VERSION ""

NS_ :

BS_:

BU_:

BO_ 2147548630 BJM1: 8 Vector__XXX
 SG_ Joystick1XAxisDetentPosStatus : 38|2@1+ (1,0) [0|3] "" Vector__XXX
 SG_ Joystick1YAxisDetentPosStatus : 36|2@1+ (1,0) [0|3] "" Vector__XXX
 SG_ Joystick1YAxisPos : 22|10@1+ (0.1,0) [0|102] "%" Vector__XXX
 SG_ Jystck1YAxsLvrFrwrdPstvPsStatus : 20|2@1+ (1,0) [0|3] "" Vector__XXX
 SG_ Jystck1YAxsLvrBckNgtvePosStatus : 18|2@1+ (1,0) [0|3] "" Vector__XXX
 SG_ Joystick1YAxisNeutralPosStatus : 16|2@1+ (1,0) [0|3] "" Vector__XXX
 SG_ Joystick1XAxisPos : 6|10@1+ (0.1,0) [0|102] "%" Vector__XXX
 SG_ Joystick1Button9PressedStatus : 62|2@1+ (1,0) [0|3] "" Vector__XXX
 SG_ Joystick1Button10PressedStatus : 60|2@1+ (1,0) [0|3] "" Vector__XXX
 SG_ Joystick1Button11PressedStatus : 58|2@1+ (1,0) [0|3] "" Vector__XXX
 SG_ Joystick1Button12PressedStatus : 56|2@1+ (1,0) [0|3] "" Vector__XXX
 SG_ Joystick1Button5PressedStatus : 54|2@1+ (1,0) [0|3] "" Vector__XXX
 SG_ Joystick1Button6PressedStatus : 52|2@1+ (1,0) [0|3] "" Vector__XXX
 SG_ Joystick1Button7PressedStatus : 50|2@1+ (1,0) [0|3] "" Vector__XXX
 SG_ Joystick1Button8PressedStatus : 48|2@1+ (1,0) [0|3] "" Vector__XXX
 SG_ Joystick1Button1PressedStatus : 46|2@1+ (1,0) [0|3] "" Vector__XXX
 SG_ Joystick1Button2PressedStatus : 44|2@1+ (1,0) [0|3] "" Vector__XXX
 SG_ Joystick1Button3PressedStatus : 42|2@1+ (1,0) [0|3] "" Vector__XXX
 SG_ Joystick1Button4PressedStatus : 40|2@1+ (1,0) [0|3] "" Vector__XXX
 SG_ Jystck1XAxsLvrRghtPstvPosStatus : 4|2@1+ (1,0) [0|3] "" Vector__XXX
 SG_ Jystck1XAxsLvrLftNgtvePosStatus : 2|2@1+ (1,0) [0|3] "" Vector__XXX
 SG_ Joystick1XAxisNeutralPosStatus : 0|2@1+ (1,0) [0|3] "" Vector__XXX

BO_ 2147548922 B: 8 Vector__XXX
 SG_ ParkingBrakeActuator : 24|2@1+ (1,0) [0|3] "" Vector__XXX
 SG_ BrakeSecondPress : 16|8@1+ (4,0) [0|1000] "kPa" Vector__XXX
 SG_ BrakePrimaryPress : 8|8@1+ (4,0) [0|1000] "kPa" Vector__XXX
 SG_ BrakeAppPress : 0|8@1+ (4,0) [0|1000] "kPa" Vector__XXX

BO_ 2147548926 AWPP: 8 Vector__XXX
 SG_ AuxPumpPress : 0|8@1+ (16,0) [0|4000] "kPa" Vector__XXX

BO_ 2147548889 AUXIO: 8 Vector__XXX
 SG_ AuxI_OChannel2 : 48|16@1+ (1,0) [0|64255] "counts" Vector__XXX
 SG_ AuxI_OChannel1 : 32|16@1+ (1,0) [0|64255] "counts" Vector__XXX
 SG_ AuxI_O13 : 30|2@1+ (1,0) [0|3] "" Vector__XXX
 SG_ AuxI_O14 : 28|2@1+ (1,0) [0|3] "" Vector__XXX
 SG_ AuxI_O15 : 26|2@1+ (1,0) [0|3] "" Vector__XXX
 SG_ AuxI_O16 : 24|2@1+ (1,0) [0|3] "" Vector__XXX
 SG_ AuxI_O09 : 22|2@1+ (1,0) [0|3] "" Vector__XXX
 SG_ AuxI_O10 : 20|2@1+ (1,0) [0|3] "" Vector__XXX
 SG_ AuxI_O11 : 18|2@1+ (1,0) [0|3] "" Vector__XXX
 SG_ AuxI_O12 : 16|2@1+ (1,0) [0|3] "" Vector__XXX
 SG_ AuxI_O05 : 14|2@1+ (1,0) [0|3] "" Vector__XXX
 SG_ AuxI_O06 : 12|2@1+ (1,0) [0|3] "" Vector__XXX
 SG_ AuxI_O07 : 10|2@1+ (1,0) [0|3] "" Vector__XXX
 SG_ AuxI_O08 : 8|2@1+ (1,0) [0|3] "" Vector__XXX
 SG_ AuxI_O01 : 6|2@1+ (1,0) [0|3] "" Vector__XXX
 SG_ AuxI_O02 : 4|2@1+ (1,0) [0|3] "" Vector__XXX
 SG_ AuxI_O03 : 2|2@1+ (1,0) [0|3] "" Vector__XXX
 SG_ AuxI_O04 : 0|2@1+ (1,0) [0|3] "" Vector__XXX

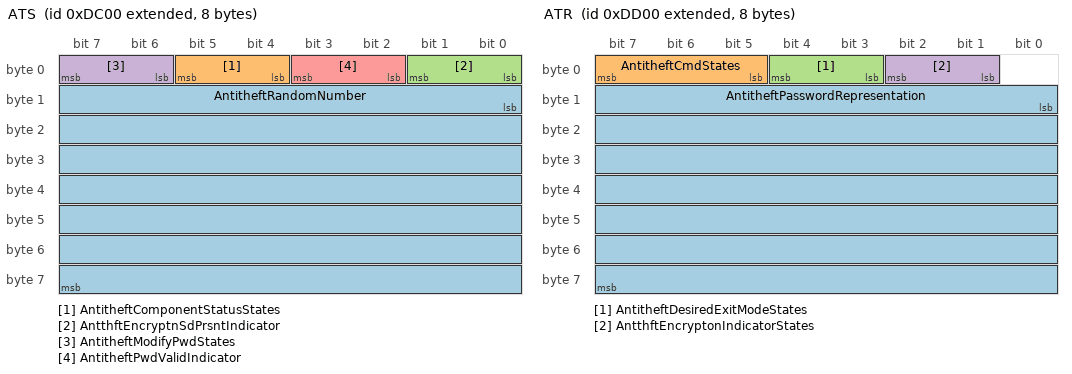
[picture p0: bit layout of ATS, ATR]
BO_ 2147539968 ATS: 8 Vector__XXX
 SG_ AntitheftRandomNumber : 8|56@1+ (1,0) [0|255] "per" Vector__XXX
 SG_ AntitheftComponentStatusStates : 4|2@1+ (1,0) [0|3] "" Vector__XXX
 SG_ AntthftEncryptnSdPrsntIndicator : 0|2@1+ (1,0) [0|3] "" Vector__XXX
 SG_ AntitheftModifyPwdStates : 6|2@1+ (1,0) [0|3] "" Vector__XXX
 SG_ AntitheftPwdValidIndicator : 2|2@1+ (1,0) [0|3] "" Vector__XXX

BO_ 2147540224 ATR: 8 Vector__XXX
 SG_ AntitheftPasswordRepresentation : 8|56@1+ (1,0) [0|255] "per" Vector__XXX
 SG_ AntitheftCmdStates : 5|3@1+ (1,0) [0|7] "" Vector__XXX
 SG_ AntitheftDesiredExitModeStates : 3|2@1+ (1,0) [0|3] "" Vector__XXX
 SG_ AntthftEncryptonIndicatorStates : 1|2@1+ (1,0) [0|3] "" Vector__XXX

BO_ 2147548593 ATI2b: 8 Vector__XXX

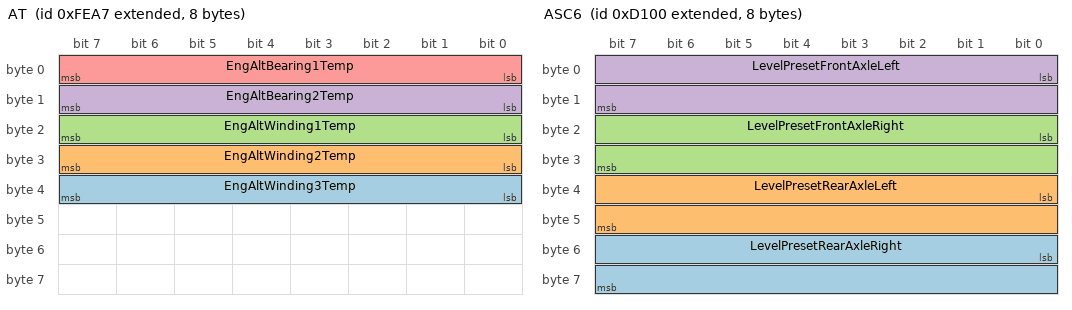
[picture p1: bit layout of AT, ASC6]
BO_ 2147548839 AT: 8 Vector__XXX
 SG_ EngAltWinding3Temp : 32|8@1+ (1,-40) [-40|210] "deg" Vector__XXX
 SG_ EngAltWinding2Temp : 24|8@1+ (1,-40) [-40|210] "deg" Vector__XXX
 SG_ EngAltWinding1Temp : 16|8@1+ (1,-40) [-40|210] "deg" Vector__XXX
 SG_ EngAltBearing2Temp : 8|8@1+ (1,-40) [-40|210] "deg" Vector__XXX
 SG_ EngAltBearing1Temp : 0|8@1+ (1,-40) [-40|210] "deg" Vector__XXX

BO_ 2147537152 ASC6: 8 Vector__XXX
 SG_ LevelPresetRearAxleRight : 48|16@1+ (0.1,-2800) [-2800|3225.5] "mm" Vector__XXX
 SG_ LevelPresetRearAxleLeft : 32|16@1+ (0.1,-2800) [-2800|3225.5] "mm" Vector__XXX
 SG_ LevelPresetFrontAxleRight : 16|16@1+ (0.1,-2800) [-2800|3225.5] "mm" Vector__XXX
 SG_ LevelPresetFrontAxleLeft : 0|16@1+ (0.1,-2800) [-2800|3225.5] "mm" Vector__XXX

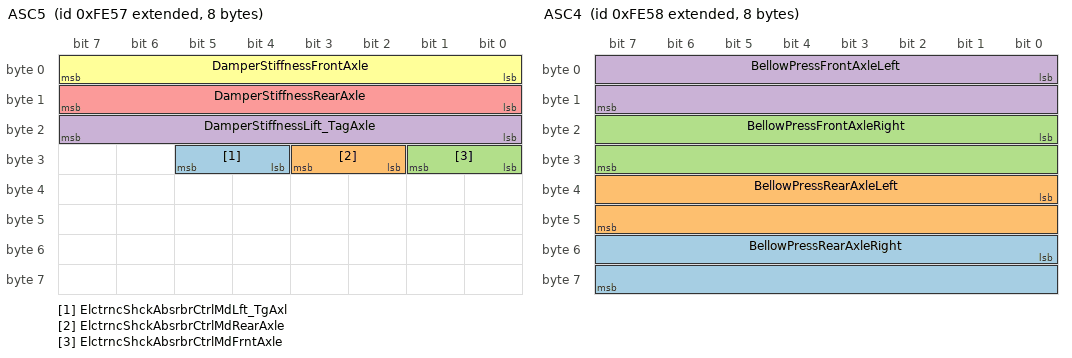
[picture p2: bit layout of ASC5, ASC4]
BO_ 2147548759 ASC5: 8 Vector__XXX
 SG_ ElctrncShckAbsrbrCtrlMdLft_TgAxl : 28|2@1+ (1,0) [0|3] "" Vector__XXX
 SG_ ElctrncShckAbsrbrCtrlMdRearAxle : 26|2@1+ (1,0) [0|3] "" Vector__XXX
 SG_ ElctrncShckAbsrbrCtrlMdFrntAxle : 24|2@1+ (1,0) [0|3] "" Vector__XXX
 SG_ DamperStiffnessLift_TagAxle : 16|8@1+ (0.4,0) [0|100] "%" Vector__XXX
 SG_ DamperStiffnessRearAxle : 8|8@1+ (0.4,0) [0|100] "%" Vector__XXX
 SG_ DamperStiffnessFrontAxle : 0|8@1+ (0.4,0) [0|100] "%" Vector__XXX

BO_ 2147548760 ASC4: 8 Vector__XXX
 SG_ BellowPressRearAxleRight : 48|16@1+ (0.1,0) [0|6425.5] "kPa" Vector__XXX
 SG_ BellowPressRearAxleLeft : 32|16@1+ (0.1,0) [0|6425.5] "kPa" Vector__XXX
 SG_ BellowPressFrontAxleRight : 16|16@1+ (0.1,0) [0|6425.5] "kPa" Vector__XXX
 SG_ BellowPressFrontAxleLeft : 0|16@1+ (0.1,0) [0|6425.5] "kPa" Vector__XXX

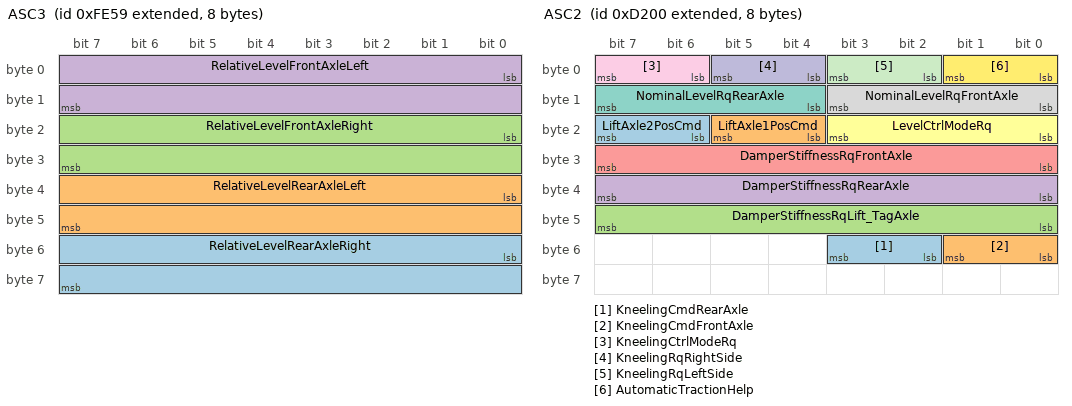
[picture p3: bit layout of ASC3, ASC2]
BO_ 2147548761 ASC3: 8 Vector__XXX
 SG_ RelativeLevelRearAxleRight : 48|16@1+ (0.1,-2800) [-2800|3225.5] "mm" Vector__XXX
 SG_ RelativeLevelRearAxleLeft : 32|16@1+ (0.1,-2800) [-2800|3225.5] "mm" Vector__XXX
 SG_ RelativeLevelFrontAxleRight : 16|16@1+ (0.1,-2800) [-2800|3225.5] "mm" Vector__XXX
 SG_ RelativeLevelFrontAxleLeft : 0|16@1+ (0.1,-2800) [-2800|3225.5] "mm" Vector__XXX

BO_ 2147537408 ASC2: 8 Vector__XXX
 SG_ KneelingCmdRearAxle : 50|2@1+ (1,0) [0|3] "" Vector__XXX
 SG_ KneelingCmdFrontAxle : 48|2@1+ (1,0) [0|3] "" Vector__XXX
 SG_ DamperStiffnessRqLift_TagAxle : 40|8@1+ (0.4,0) [0|100] "%" Vector__XXX
 SG_ DamperStiffnessRqRearAxle : 32|8@1+ (0.4,0) [0|100] "%" Vector__XXX
 SG_ DamperStiffnessRqFrontAxle : 24|8@1+ (0.4,0) [0|100] "%" Vector__XXX
 SG_ LevelCtrlModeRq : 16|4@1+ (1,0) [0|15] "" Vector__XXX
 SG_ NominalLevelRqRearAxle : 12|4@1+ (1,0) [0|15] "" Vector__XXX
 SG_ NominalLevelRqFrontAxle : 8|4@1+ (1,0) [0|15] "" Vector__XXX
 SG_ KneelingCtrlModeRq : 6|2@1+ (1,0) [0|3] "" Vector__XXX
 SG_ KneelingRqRightSide : 4|2@1+ (1,0) [0|3] "" Vector__XXX
 SG_ KneelingRqLeftSide : 2|2@1+ (1,0) [0|3] "" Vector__XXX
 SG_ AutomaticTractionHelp : 0|2@1+ (1,0) [0|3] "" Vector__XXX
 SG_ LiftAxle2PosCmd : 22|2@1+ (1,0) [0|3] "" Vector__XXX
 SG_ LiftAxle1PosCmd : 20|2@1+ (1,0) [0|3] "" Vector__XXX

BO_ 2147548762 ASC1: 8 Vector__XXX
 SG_ SspensionCtrlRefusalInformation : 56|4@1+ (1,0) [0|15] "" Vector__XXX
 SG_ SuspensionRemoteCtrl2 : 50|2@1+ (1,0) [0|3] "" Vector__XXX
 SG_ SuspensionRemoteCtrl1 : 48|2@1+ (1,0) [0|3] "" Vector__XXX
 SG_ RearAxleInBumperRange : 42|2@1+ (1,0) [0|3] "" Vector__XXX
 SG_ FrontAxleInBumperRange : 40|2@1+ (1,0) [0|3] "" Vector__XXX
 SG_ DoorRelease : 36|2@1+ (1,0) [0|3] "" Vector__XXX
 SG_ VehicleMotionInhibit : 34|2@1+ (1,0) [0|3] "" Vector__XXX
 SG_ SecurityDevice : 32|2@1+ (1,0) [0|3] "" Vector__XXX
 SG_ LevelCtrlMode : 28|4@1+ (1,0) [0|15] "" Vector__XXX
 SG_ KneelingInformation : 24|4@1+ (1,0) [0|15] "" Vector__XXX
 SG_ LiftingCtrlModeRearAxle : 22|2@1+ (1,0) [0|3] "" Vector__XXX
 SG_ LiftingCtrlModeFrontAxle : 20|2@1+ (1,0) [0|3] "" Vector__XXX
 SG_ LoweringCtrlModeRearAxle : 18|2@1+ (1,0) [0|3] "" Vector__XXX
 SG_ LoweringCtrlModeFrontAxle : 16|2@1+ (1,0) [0|3] "" Vector__XXX
 SG_ AboveNominalLevelRearAxle : 14|2@1+ (1,0) [0|3] "" Vector__XXX
 SG_ AboveNominalLevelFrontAxle : 12|2@1+ (1,0) [0|3] "" Vector__XXX
 SG_ BelowNominalLevelRearAxle : 10|2@1+ (1,0) [0|3] "" Vector__XXX
 SG_ BelowNominalLevelFrontAxle : 8|2@1+ (1,0) [0|3] "" Vector__XXX
 SG_ NominalLevelRearAxle : 4|4@1+ (1,0) [0|15] "" Vector__XXX
 SG_ NominalLevelFrontAxle : 0|4@1+ (1,0) [0|15] "" Vector__XXX
 SG_ LiftAxle2Pos : 46|2@1+ (1,0) [0|3] "" Vector__XXX
 SG_ LiftAxle1Pos : 38|2@1+ (1,0) [0|3] "" Vector__XXX

BO_ 2147548885 AS: 8 Vector__XXX
 SG_ AltSpeed : 0|16@1+ (0.5,0) [0|32127.5] "rpm" Vector__XXX

BO_ 2147548791 AP: 8 Vector__XXX
 SG_ AuxAbsPressReading : 32|16@1+ (0.5,0) [0|32127.5] "kPa" Vector__XXX
 SG_ AuxGagePressReading1 : 16|16@1+ (0.5,0) [0|32127.5] "kPa" Vector__XXX
 SG_ AuxVacuumPressReading : 0|16@1+ (0.5,0) [0|32127.5] "kPa" Vector__XXX

BO_ 2147548640 AMB2: 8 Vector__XXX
 SG_ SolarSensorMax : 8|8@1+ (0.4,0) [0|100] "mW/cm^2" Vector__XXX
 SG_ SolarIntensityPercent : 0|8@1+ (0.4,0) [0|100] "%" Vector__XXX

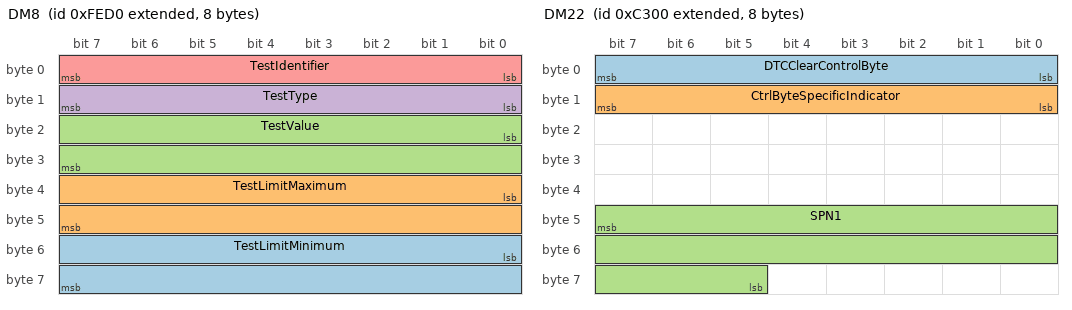
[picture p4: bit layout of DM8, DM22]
BO_ 2147548880 DM8: 8 Vector__XXX
 SG_ TestLimitMinimum : 48|16@1+ (1,0) [0|64255] "" Vector__XXX
 SG_ TestLimitMaximum : 32|16@1+ (1,0) [0|64255] "" Vector__XXX
 SG_ TestValue : 16|16@1+ (1,0) [0|64255] "" Vector__XXX
 SG_ TestType : 8|8@1+ (1,0) [1|64] "" Vector__XXX
 SG_ TestIdentifier : 0|8@1+ (1,0) [1|64] "" Vector__XXX

BO_ 2680225732 PropBC4: 8 Vector__XXX

BO_ 2680225731 PropBC3: 8 Vector__XXX

BO_ 2680225730 PropBC2: 8 Vector__XXX

BO_ 2680225729 PropBC1: 8 Vector__XXX

BO_ 2680225728 PropBC0: 8 Vector__XXX

BO_ 2680225727 PropBBF: 8 Vector__XXX

BO_ 2680225726 PropBBE: 8 Vector__XXX

BO_ 2680225725 PropBBD: 8 Vector__XXX

BO_ 2680225724 PropBBC: 8 Vector__XXX

BO_ 2680225723 PropBBB: 8 Vector__XXX

BO_ 2680225722 PropBBA: 8 Vector__XXX

BO_ 2680225721 PropBB9: 8 Vector__XXX

BO_ 2680225720 PropBB8: 8 Vector__XXX

BO_ 2680225719 PropBB7: 8 Vector__XXX

BO_ 2680225718 PropBB6: 8 Vector__XXX

BO_ 2680225717 PropBB5: 8 Vector__XXX

BO_ 2680225716 PropBB4: 8 Vector__XXX

BO_ 2680225715 PropBB3: 8 Vector__XXX

BO_ 2680225714 PropBB2: 8 Vector__XXX

BO_ 2680225713 PropBB1: 8 Vector__XXX

BO_ 2680225712 PropBB0: 8 Vector__XXX

BO_ 2680225711 PropBAF: 8 Vector__XXX

BO_ 2680225710 PropBAE: 8 Vector__XXX

BO_ 2680225709 PropBAD: 8 Vector__XXX

BO_ 2680225708 PropBAC: 8 Vector__XXX

BO_ 2680225707 PropBAB: 8 Vector__XXX

BO_ 2680225706 PropBAA: 8 Vector__XXX

BO_ 2680225705 PropBA9: 8 Vector__XXX

BO_ 2680225704 PropBA8: 8 Vector__XXX

BO_ 2680225703 PropBA7: 8 Vector__XXX

BO_ 2680225702 PropBA6: 8 Vector__XXX

BO_ 2680225701 PropBA5: 8 Vector__XXX

BO_ 2680225700 PropBA4: 8 Vector__XXX

BO_ 2680225699 PropBA3: 8 Vector__XXX

BO_ 2680225698 PropBA2: 8 Vector__XXX

BO_ 2680225697 PropBA1: 8 Vector__XXX

BO_ 2680225696 PropBA0: 8 Vector__XXX

BO_ 2680225695 PropB9F: 8 Vector__XXX

BO_ 2680225694 PropB9E: 8 Vector__XXX

BO_ 2680225693 PropB9D: 8 Vector__XXX

BO_ 2680225692 PropB9C: 8 Vector__XXX

BO_ 2680225691 PropB9B: 8 Vector__XXX

BO_ 2680225690 PropB9A: 8 Vector__XXX

BO_ 2680225689 PropB99: 8 Vector__XXX

BO_ 2680225688 PropB98: 8 Vector__XXX

BO_ 2680225687 PropB97: 8 Vector__XXX

BO_ 2680225686 PropB96: 8 Vector__XXX

BO_ 2680225685 PropB95: 8 Vector__XXX

BO_ 2680225684 PropB94: 8 Vector__XXX

BO_ 2680225683 PropB93: 8 Vector__XXX

BO_ 2680225682 PropB92: 8 Vector__XXX

BO_ 2680225681 PropB91: 8 Vector__XXX

BO_ 2680225680 PropB90: 8 Vector__XXX

BO_ 2680225679 PropB8F: 8 Vector__XXX

BO_ 2680225678 PropB8E: 8 Vector__XXX

BO_ 2680225677 PropB8D: 8 Vector__XXX

BO_ 2680225676 PropB8C: 8 Vector__XXX

BO_ 2680225675 PropB8B: 8 Vector__XXX

BO_ 2680225674 PropB8A: 8 Vector__XXX

BO_ 2680225673 PropB89: 8 Vector__XXX

BO_ 2680225672 PropB88: 8 Vector__XXX

BO_ 2680225671 PropB87: 8 Vector__XXX

BO_ 2680225670 PropB86: 8 Vector__XXX

BO_ 2680225669 PropB85: 8 Vector__XXX

BO_ 2680225668 PropB84: 8 Vector__XXX

BO_ 2680225667 PropB83: 8 Vector__XXX

BO_ 2680225666 PropB82: 8 Vector__XXX

BO_ 2680225665 PropB81: 8 Vector__XXX

BO_ 2680225664 PropB80: 8 Vector__XXX

BO_ 2680225663 PropB7F: 8 Vector__XXX

BO_ 2147541760 DM7: 8 Vector__XXX
 SG_ TestIdentifier : 0|8@1+ (1,0) [1|64] "" Vector__XXX

BO_ 2147548879 DM6: 22 Vector__XXX
 SG_ SPN5 : 151|19@0+ (1,0) [0|524287] "" Vector__XXX
 SG_ SPN4 : 119|19@0+ (1,0) [0|524287] "" Vector__XXX
 SG_ SPN3 : 87|19@0+ (1,0) [0|524287] "" Vector__XXX
 SG_ SPN2 : 55|19@0+ (1,0) [0|524287] "" Vector__XXX
 SG_ FailureModeIdentifier5 : 160|5@1+ (1,0) [0|0] "" Vector__XXX
 SG_ FailureModeIdentifier4 : 128|5@1+ (1,0) [0|0] "" Vector__XXX
 SG_ FailureModeIdentifier3 : 96|5@1+ (1,0) [0|0] "" Vector__XXX
 SG_ FailureModeIdentifier2 : 64|5@1+ (1,0) [0|0] "" Vector__XXX
 SG_ SPNConversionMethod5 : 175|1@1+ (1,0) [0|1] "" Vector__XXX
 SG_ SPNConversionMethod4 : 143|1@1+ (1,0) [0|1] "" Vector__XXX
 SG_ SPNConversionMethod3 : 111|1@1+ (1,0) [0|1] "" Vector__XXX
 SG_ SPNConversionMethod2 : 79|1@1+ (1,0) [0|1] "" Vector__XXX
 SG_ OccurenceCount5 : 168|7@1+ (1,0) [0|126] "" Vector__XXX
 SG_ OccurenceCount4 : 136|7@1+ (1,0) [0|126] "" Vector__XXX
 SG_ OccurenceCount3 : 104|7@1+ (1,0) [0|126] "" Vector__XXX
 SG_ OccurenceCount2 : 72|7@1+ (1,0) [0|126] "" Vector__XXX
 SG_ OccurenceCount1 : 40|7@1+ (1,0) [0|126] "" Vector__XXX
 SG_ SPNConversionMethod1 : 47|1@1+ (1,0) [0|1] "" Vector__XXX
 SG_ FailureModeIdentifier1 : 32|5@1+ (1,0) [0|0] "" Vector__XXX
 SG_ SPN1 : 23|19@0+ (1,0) [0|524287] "" Vector__XXX
 SG_ MalfunctionIndicatorLampStatus : 6|2@1+ (1,0) [0|3] "" Vector__XXX
 SG_ RedStopLampState : 4|2@1+ (1,0) [0|3] "" Vector__XXX
 SG_ AmberWarningLampStatus : 2|2@1+ (1,0) [0|3] "" Vector__XXX
 SG_ ProtectLampStatus : 0|2@1+ (1,0) [0|3] "" Vector__XXX

BO_ 2147548878 DM5: 8 Vector__XXX
 SG_ MisfireMonitoringSupport : 24|1@1+ (1,0) [0|0] "" Vector__XXX
 SG_ OBDCompliance : 16|8@1+ (1,0) [0|240] "" Vector__XXX
 SG_ PreviouslyActiveTroubleCodes : 8|8@1+ (1,0) [0|240] "" Vector__XXX
 SG_ ActiveTroubleCodes : 0|8@1+ (1,0) [0|240] "" Vector__XXX
 SG_ SecondAirSystemMonStatus : 51|1@1+ (1,0) [0|1] "" Vector__XXX
 SG_ EvaporativeSystemMonStatus : 50|1@1+ (1,0) [0|1] "" Vector__XXX
 SG_ ACSystemRefrigerantMonStatus : 52|1@1+ (1,0) [0|1] "" Vector__XXX
 SG_ OxygenSensorHeaterMonStatus : 54|1@1+ (1,0) [0|1] "" Vector__XXX
 SG_ OxygenSensorMonStatus : 53|1@1+ (1,0) [0|1] "" Vector__XXX
 SG_ EGRSystemMonitoringStatus : 55|1@1+ (1,0) [0|1] "" Vector__XXX
 SG_ CatalystMonStatus : 48|1@1+ (1,0) [0|1] "" Vector__XXX
 SG_ ColdStartAidSystemMonStatus : 56|1@1+ (1,0) [0|1] "" Vector__XXX
 SG_ HeatedCatalystMonStatus : 49|1@1+ (1,0) [0|0] "" Vector__XXX
 SG_ CatalystMonSupp : 32|1@1+ (1,0) [0|1] "" Vector__XXX
 SG_ ColdStartAidSystemMonSupp : 40|1@1+ (1,0) [0|1] "" Vector__XXX
 SG_ HeatedCatalystMonSupp : 33|1@1+ (1,0) [0|0] "" Vector__XXX
 SG_ EvaporativeSystemMonSupp : 34|1@1+ (1,0) [0|1] "" Vector__XXX
 SG_ SecondAirSystemMonSupp : 35|1@1+ (1,0) [0|1] "" Vector__XXX
 SG_ ACSystemRefrigerantMonSupp : 36|1@1+ (1,0) [0|1] "" Vector__XXX
 SG_ OxygenSensorMonSupp : 37|1@1+ (1,0) [0|1] "" Vector__XXX
 SG_ OxygenSensorHeaterMonSupp : 38|1@1+ (1,0) [0|1] "" Vector__XXX
 SG_ EGRSystemMonitoringSupp : 39|1@1+ (1,0) [0|1] "" Vector__XXX
 SG_ MisfireMonitoringStatus : 28|1@1+ (1,0) [0|0] "" Vector__XXX
 SG_ ComprehensiveCompMonStatus : 30|1@1+ (1,0) [0|1] "" Vector__XXX
 SG_ FuelSystemMonitoringStatus : 29|1@1+ (1,0) [0|1] "" Vector__XXX
 SG_ ComprehensiveComponentMonSupp : 26|1@1+ (1,0) [0|0] "" Vector__XXX
 SG_ FuelSystemMonitoringSupport : 25|1@1+ (1,0) [0|1] "" Vector__XXX

BO_ 2147548877 DM4: 13 Vector__XXX
 SG_ OccurenceCount1 : 32|7@1+ (1,0) [0|126] "" Vector__XXX
 SG_ SPNConversionMethod1 : 39|1@1+ (1,0) [0|1] "" Vector__XXX
 SG_ VehicleSpeed : 88|16@1+ (0.00390625,0) [0|250.996] "km/h" Vector__XXX
 SG_ EngineLoad : 72|8@1+ (0.4,0) [0|100] "%" Vector__XXX
 SG_ Boost : 48|8@1+ (2,0) [0|500] "kPa" Vector__XXX
 SG_ FailureModeIdentifier1 : 24|5@1+ (1,0) [0|0] "" Vector__XXX
 SG_ SPN1 : 15|19@0+ (1,0) [0|524287] "" Vector__XXX
 SG_ FreezeFrameLength : 0|8@1+ (1,0) [0|255] "byte" Vector__XXX
 SG_ EngineTorqueMode : 40|8@1+ (1,0) [0|255] "" Vector__XXX
 SG_ EngineSpeed : 56|16@1+ (0.125,0) [0|8031.88] "rpm" Vector__XXX
 SG_ EngineCoolantTemperature : 80|8@1+ (1,-40) [-40|210] "°C" Vector__XXX

BO_ 2147548876 DM3: 0 Vector__XXX

BO_ 2147548599 DM25: 13 Vector__XXX
 SG_ OccurenceCount1 : 32|7@1+ (1,0) [0|126] "" Vector__XXX
 SG_ SPNConversionMethod1 : 39|1@1+ (1,0) [0|1] "" Vector__XXX
 SG_ FailureModeIdentifier1 : 24|5@1+ (1,0) [0|0] "" Vector__XXX
 SG_ SPN1 : 15|19@0+ (1,0) [0|524287] "" Vector__XXX
 SG_ ExtendedFreezeFrameLength : 0|8@1+ (1,0) [0|255] "byte" Vector__XXX

BO_ 2147548598 DM24: 8 Vector__XXX
 SG_ SPNDataLength : 56|8@1+ (1,0) [0|240] "" Vector__XXX
 SG_ SPNSupportType : 24|32@1+ (1,0) [0|4294967295] "" Vector__XXX
 SG_ SPNSupported : 0|24@1+ (1,0) [0|524287] "" Vector__XXX

BO_ 2147548597 DM23: 22 Vector__XXX
 SG_ SPN5 : 151|19@0+ (1,0) [0|524287] "" Vector__XXX
 SG_ SPN4 : 119|19@0+ (1,0) [0|524287] "" Vector__XXX
 SG_ SPN3 : 87|19@0+ (1,0) [0|524287] "" Vector__XXX
 SG_ SPN2 : 55|19@0+ (1,0) [0|524287] "" Vector__XXX
 SG_ FailureModeIdentifier5 : 160|5@1+ (1,0) [0|0] "" Vector__XXX
 SG_ FailureModeIdentifier4 : 128|5@1+ (1,0) [0|0] "" Vector__XXX
 SG_ OccurenceCount1 : 40|7@1+ (1,0) [0|126] "" Vector__XXX
 SG_ SPNConversionMethod1 : 47|1@1+ (1,0) [0|1] "" Vector__XXX
 SG_ FailureModeIdentifier1 : 32|5@1+ (1,0) [0|0] "" Vector__XXX
 SG_ SPN1 : 23|19@0+ (1,0) [0|524287] "" Vector__XXX
 SG_ MalfunctionIndicatorLampStatus : 6|2@1+ (1,0) [0|3] "" Vector__XXX
 SG_ RedStopLampState : 4|2@1+ (1,0) [0|3] "" Vector__XXX
 SG_ AmberWarningLampStatus : 2|2@1+ (1,0) [0|3] "" Vector__XXX
 SG_ ProtectLampStatus : 0|2@1+ (1,0) [0|3] "" Vector__XXX
 SG_ FailureModeIdentifier3 : 96|5@1+ (1,0) [0|0] "" Vector__XXX
 SG_ FailureModeIdentifier2 : 64|5@1+ (1,0) [0|0] "" Vector__XXX
 SG_ SPNConversionMethod5 : 175|1@1+ (1,0) [0|1] "" Vector__XXX
 SG_ SPNConversionMethod4 : 143|1@1+ (1,0) [0|1] "" Vector__XXX
 SG_ SPNConversionMethod3 : 111|1@1+ (1,0) [0|1] "" Vector__XXX
 SG_ SPNConversionMethod2 : 79|1@1+ (1,0) [0|1] "" Vector__XXX
 SG_ OccurenceCount5 : 168|7@1+ (1,0) [0|126] "" Vector__XXX
 SG_ OccurenceCount4 : 136|7@1+ (1,0) [0|126] "" Vector__XXX
 SG_ OccurenceCount3 : 104|7@1+ (1,0) [0|126] "" Vector__XXX
 SG_ OccurenceCount2 : 72|7@1+ (1,0) [0|126] "" Vector__XXX

BO_ 2147533568 DM22: 8 Vector__XXX
 SG_ DTCClearControlByte : 0|8@1+ (1,0) [0|255] "" Vector__XXX
 SG_ CtrlByteSpecificIndicator : 8|8@1+ (1,0) [0|255] "" Vector__XXX
 SG_ SPN1 : 47|19@0+ (1,0) [0|524287] "" Vector__XXX

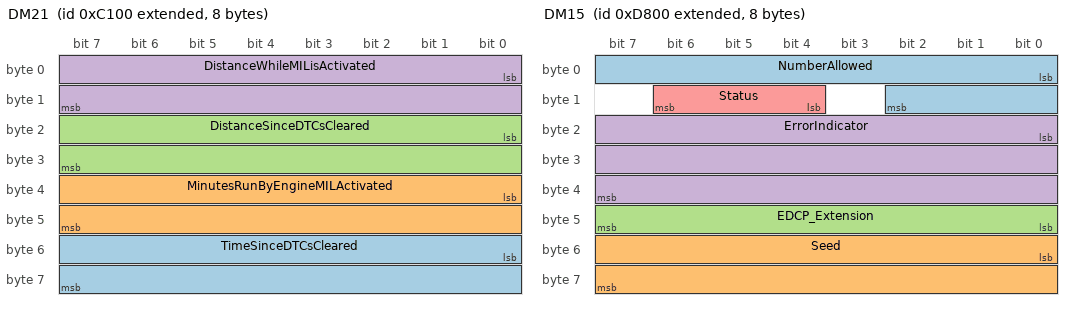
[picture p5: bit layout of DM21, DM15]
BO_ 2147533056 DM21: 8 Vector__XXX
 SG_ TimeSinceDTCsCleared : 48|16@1+ (1,0) [0|64255] "min" Vector__XXX
 SG_ MinutesRunByEngineMILActivated : 32|16@1+ (1,0) [0|64255] "min" Vector__XXX
 SG_ DistanceSinceDTCsCleared : 16|16@1+ (1,0) [0|64255] "km" Vector__XXX
 SG_ DistanceWhileMILisActivated : 0|16@1+ (1,0) [0|64255] "km" Vector__XXX

BO_ 2147533312 DM20: 11 Vector__XXX
 SG_ ApplSysMonitorDenominator : 72|16@1+ (1,0) [0|65535] "" Vector__XXX
 SG_ ApplSysMonitorNumerator : 56|16@1+ (1,0) [0|65535] "" Vector__XXX
 SG_ SPNofApplSysMonitor : 32|24@1+ (1,0) [0|524287] "" Vector__XXX
 SG_ OBDMonitoringCondEncountered : 16|16@1+ (1,0) [0|65535] "" Vector__XXX
 SG_ IgnitionCycleCounter : 0|16@1+ (1,0) [0|65535] "" Vector__XXX

BO_ 2147548875 DM2: 22 Vector__XXX
 SG_ SPN5 : 151|19@0+ (1,0) [0|524287] "" Vector__XXX
 SG_ SPN4 : 119|19@0+ (1,0) [0|524287] "" Vector__XXX
 SG_ SPN3 : 87|19@0+ (1,0) [0|524287] "" Vector__XXX
 SG_ SPN2 : 55|19@0+ (1,0) [0|524287] "" Vector__XXX
 SG_ FailureModeIdentifier5 : 160|5@1+ (1,0) [0|0] "" Vector__XXX
 SG_ FailureModeIdentifier4 : 128|5@1+ (1,0) [0|0] "" Vector__XXX
 SG_ OccurenceCount1 : 40|7@1+ (1,0) [0|126] "" Vector__XXX
 SG_ SPNConversionMethod1 : 47|1@1+ (1,0) [0|1] "" Vector__XXX
 SG_ FailureModeIdentifier1 : 32|5@1+ (1,0) [0|0] "" Vector__XXX
 SG_ SPN1 : 23|19@0+ (1,0) [0|524287] "" Vector__XXX
 SG_ MalfunctionIndicatorLampStatus : 6|2@1+ (1,0) [0|3] "" Vector__XXX
 SG_ RedStopLampState : 4|2@1+ (1,0) [0|3] "" Vector__XXX
 SG_ AmberWarningLampStatus : 2|2@1+ (1,0) [0|3] "" Vector__XXX
 SG_ ProtectLampStatus : 0|2@1+ (1,0) [0|3] "" Vector__XXX
 SG_ FailureModeIdentifier3 : 96|5@1+ (1,0) [0|0] "" Vector__XXX
 SG_ FailureModeIdentifier2 : 64|5@1+ (1,0) [0|0] "" Vector__XXX
 SG_ SPNConversionMethod5 : 175|1@1+ (1,0) [0|1] "" Vector__XXX
 SG_ SPNConversionMethod4 : 143|1@1+ (1,0) [0|1] "" Vector__XXX
 SG_ SPNConversionMethod3 : 111|1@1+ (1,0) [0|1] "" Vector__XXX
 SG_ SPNConversionMethod2 : 79|1@1+ (1,0) [0|1] "" Vector__XXX
 SG_ OccurenceCount5 : 168|7@1+ (1,0) [0|126] "" Vector__XXX
 SG_ OccurenceCount4 : 136|7@1+ (1,0) [0|126] "" Vector__XXX
 SG_ OccurenceCount3 : 104|7@1+ (1,0) [0|126] "" Vector__XXX
 SG_ OccurenceCount2 : 72|7@1+ (1,0) [0|126] "" Vector__XXX

BO_ 2147537664 DM19: 20 Vector__XXX
 SG_ CalibrationID4 : 128|32@1+ (1,0) [0|4294967295] "" Vector__XXX
 SG_ CalibrationID3 : 96|32@1+ (1,0) [0|4294967295] "" Vector__XXX
 SG_ CalibrationID2 : 64|32@1+ (1,0) [0|4294967295] "" Vector__XXX
 SG_ CalibrationID1 : 32|32@1+ (1,0) [0|4294967295] "" Vector__XXX
 SG_ CalibrationVerificationNumber : 0|32@1+ (1,0) [0|4294967295] "" Vector__XXX

BO_ 2147538432 DM17: 8 Vector__XXX

BO_ 2147538688 DM16: 8 Vector__XXX
 SG_ NumberOfOccurance : 0|8@1+ (1,0) [0|0] "" Vector__XXX

BO_ 2147538944 DM15: 8 Vector__XXX
 SG_ NumberAllowed : 0|11@1+ (1,0) [0|2047] "" Vector__XXX
 SG_ Seed : 48|16@1+ (1,0) [0|65535] "" Vector__XXX
 SG_ EDCP_Extension : 40|8@1+ (1,0) [0|255] "" Vector__XXX
 SG_ ErrorIndicator : 16|24@1+ (1,0) [0|16777215] "" Vector__XXX
 SG_ Status : 12|3@1+ (1,0) [0|7] "" Vector__XXX

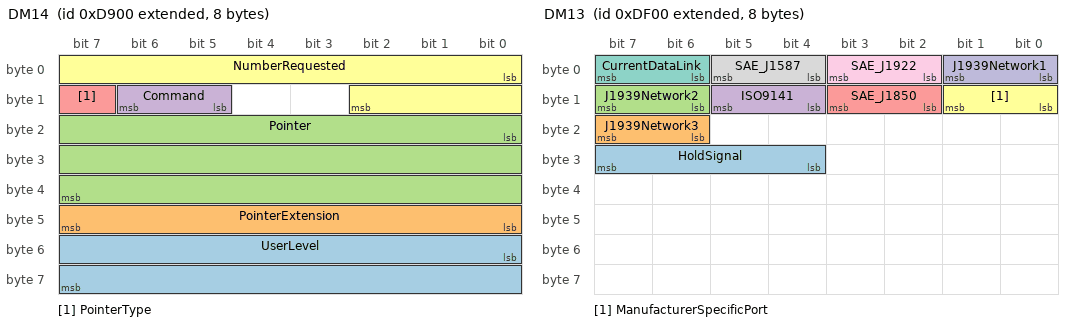
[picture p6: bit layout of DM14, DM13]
BO_ 2147539200 DM14: 8 Vector__XXX
 SG_ UserLevel : 48|16@1+ (1,0) [0|65535] "" Vector__XXX
 SG_ PointerExtension : 40|8@1+ (1,0) [0|255] "" Vector__XXX
 SG_ Pointer : 16|24@1+ (1,0) [0|16777215] "" Vector__XXX
 SG_ Command : 13|2@1+ (1,0) [0|3] "" Vector__XXX
 SG_ PointerType : 15|1@1+ (1,0) [0|1] "" Vector__XXX
 SG_ NumberRequested : 0|11@1+ (1,0) [0|2047] "" Vector__XXX

BO_ 2147540736 DM13: 8 Vector__XXX
 SG_ HoldSignal : 28|4@1+ (1,0) [0|15] "" Vector__XXX
 SG_ J1939Network3 : 22|2@1+ (1,0) [0|3] "" Vector__XXX
 SG_ J1939Network2 : 14|2@1+ (1,0) [0|3] "" Vector__XXX
 SG_ ISO9141 : 12|2@1+ (1,0) [0|3] "" Vector__XXX
 SG_ SAE_J1850 : 10|2@1+ (1,0) [0|3] "" Vector__XXX
 SG_ ManufacturerSpecificPort : 8|2@1+ (1,0) [0|3] "" Vector__XXX
 SG_ CurrentDataLink : 6|2@1+ (1,0) [0|3] "" Vector__XXX
 SG_ SAE_J1587 : 4|2@1+ (1,0) [0|3] "" Vector__XXX
 SG_ SAE_J1922 : 2|2@1+ (1,0) [0|3] "" Vector__XXX
 SG_ J1939Network1 : 0|2@1+ (1,0) [0|3] "" Vector__XXX

BO_ 2147548884 DM12: 22 Vector__XXX
 SG_ SPN5 : 151|19@0+ (1,0) [0|524287] "" Vector__XXX
 SG_ SPN4 : 119|19@0+ (1,0) [0|524287] "" Vector__XXX
 SG_ SPN3 : 87|19@0+ (1,0) [0|524287] "" Vector__XXX
 SG_ SPN2 : 55|19@0+ (1,0) [0|524287] "" Vector__XXX
 SG_ FailureModeIdentifier5 : 160|5@1+ (1,0) [0|0] "" Vector__XXX
 SG_ FailureModeIdentifier4 : 128|5@1+ (1,0) [0|0] "" Vector__XXX
 SG_ FailureModeIdentifier3 : 96|5@1+ (1,0) [0|0] "" Vector__XXX
 SG_ OccurenceCount1 : 40|7@1+ (1,0) [0|126] "" Vector__XXX
 SG_ SPNConversionMethod1 : 47|1@1+ (1,0) [0|1] "" Vector__XXX
 SG_ FailureModeIdentifier1 : 32|5@1+ (1,0) [0|0] "" Vector__XXX
 SG_ SPN1 : 23|19@0+ (1,0) [0|524287] "" Vector__XXX
 SG_ MalfunctionIndicatorLampStatus : 6|2@1+ (1,0) [0|3] "" Vector__XXX
 SG_ RedStopLampState : 4|2@1+ (1,0) [0|3] "" Vector__XXX
 SG_ AmberWarningLampStatus : 2|2@1+ (1,0) [0|3] "" Vector__XXX
 SG_ ProtectLampStatus : 0|2@1+ (1,0) [0|3] "" Vector__XXX
 SG_ FailureModeIdentifier2 : 64|5@1+ (1,0) [0|0] "" Vector__XXX
 SG_ SPNConversionMethod5 : 175|1@1+ (1,0) [0|1] "" Vector__XXX
 SG_ SPNConversionMethod4 : 143|1@1+ (1,0) [0|1] "" Vector__XXX
 SG_ SPNConversionMethod3 : 111|1@1+ (1,0) [0|1] "" Vector__XXX
 SG_ SPNConversionMethod2 : 79|1@1+ (1,0) [0|1] "" Vector__XXX
 SG_ OccurenceCount5 : 168|7@1+ (1,0) [0|126] "" Vector__XXX
 SG_ OccurenceCount4 : 136|7@1+ (1,0) [0|126] "" Vector__XXX
 SG_ OccurenceCount3 : 104|7@1+ (1,0) [0|126] "" Vector__XXX
 SG_ OccurenceCount2 : 72|7@1+ (1,0) [0|126] "" Vector__XXX

BO_ 2147548883 DM11: 0 Vector__XXX

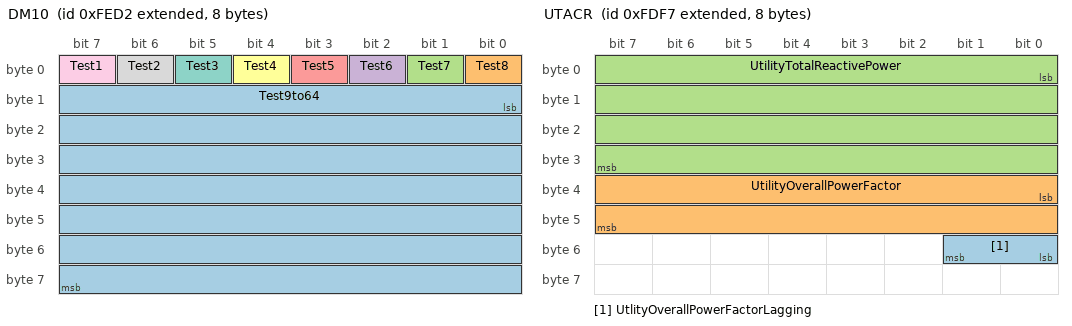
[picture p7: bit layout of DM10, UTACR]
BO_ 2147548882 DM10: 8 Vector__XXX
 SG_ Test9to64 : 8|56@1+ (1,0) [0|0] "" Vector__XXX
 SG_ Test8 : 0|1@1+ (1,0) [0|0] "" Vector__XXX
 SG_ Test7 : 1|1@1+ (1,0) [0|0] "" Vector__XXX
 SG_ Test6 : 2|1@1+ (1,0) [0|0] "" Vector__XXX
 SG_ Test5 : 3|1@1+ (1,0) [0|0] "" Vector__XXX
 SG_ Test4 : 4|1@1+ (1,0) [0|0] "" Vector__XXX
 SG_ Test3 : 5|1@1+ (1,0) [0|0] "" Vector__XXX
 SG_ Test2 : 6|1@1+ (1,0) [0|0] "" Vector__XXX
 SG_ Test1 : 7|1@1+ (1,0) [0|0] "" Vector__XXX

BO_ 2147548874 DM1: 22 Vector__XXX
 SG_ SPN5 : 151|19@0+ (1,0) [0|524287] "" Vector__XXX
 SG_ SPN4 : 119|19@0+ (1,0) [0|524287] "" Vector__XXX
 SG_ SPN3 : 87|19@0+ (1,0) [0|524287] "" Vector__XXX
 SG_ SPN2 : 55|19@0+ (1,0) [0|524287] "" Vector__XXX
 SG_ FailureModeIdentifier5 : 160|5@1+ (1,0) [0|0] "" Vector__XXX
 SG_ FailureModeIdentifier4 : 128|5@1+ (1,0) [0|0] "" Vector__XXX
 SG_ FailureModeIdentifier3 : 96|5@1+ (1,0) [0|0] "" Vector__XXX
 SG_ FlashEngineRedStopLamp : 12|2@1+ (1,0) [0|3] "" Vector__XXX
 SG_ FlashEngineProtectLamp : 8|2@1+ (1,0) [0|3] "" Vector__XXX
 SG_ FlashEngineMalfuncIndicatorLamp : 14|2@1+ (1,0) [0|3] "" Vector__XXX
 SG_ FlashEngineAmberWarningLamp : 10|2@1+ (1,0) [0|3] "" Vector__XXX
 SG_ MalfunctionIndicatorLampStatus : 6|2@1+ (1,0) [0|3] "" Vector__XXX
 SG_ AmberWarningLampStatus : 2|2@1+ (1,0) [0|3] "" Vector__XXX
 SG_ OccurenceCount1 : 40|7@1+ (1,0) [0|126] "" Vector__XXX
 SG_ SPNConversionMethod1 : 47|1@1+ (1,0) [0|1] "" Vector__XXX
 SG_ FailureModeIdentifier1 : 32|5@1+ (1,0) [0|0] "" Vector__XXX
 SG_ SPN1 : 23|19@0+ (1,0) [0|524287] "" Vector__XXX
 SG_ RedStopLampState : 4|2@1+ (1,0) [0|3] "" Vector__XXX
 SG_ ProtectLampStatus : 0|2@1+ (1,0) [0|3] "" Vector__XXX
 SG_ FailureModeIdentifier2 : 64|5@1+ (1,0) [0|0] "" Vector__XXX
 SG_ SPNConversionMethod5 : 175|1@1+ (1,0) [0|1] "" Vector__XXX
 SG_ SPNConversionMethod4 : 143|1@1+ (1,0) [0|1] "" Vector__XXX
 SG_ SPNConversionMethod3 : 111|1@1+ (1,0) [0|1] "" Vector__XXX
 SG_ SPNConversionMethod2 : 79|1@1+ (1,0) [0|1] "" Vector__XXX
 SG_ OccurenceCount5 : 168|7@1+ (1,0) [0|126] "" Vector__XXX
 SG_ OccurenceCount4 : 136|7@1+ (1,0) [0|126] "" Vector__XXX
 SG_ OccurenceCount3 : 104|7@1+ (1,0) [0|126] "" Vector__XXX
 SG_ OccurenceCount2 : 72|7@1+ (1,0) [0|126] "" Vector__XXX

BO_ 2147548663 UTACR: 8 Vector__XXX
 SG_ UtlityOverallPowerFactorLagging : 48|2@1+ (1,0) [0|3] "" Vector__XXX
 SG_ UtilityOverallPowerFactor : 32|16@1+ (1,-1) [-1|0] "+2.921814" Vector__XXX
 SG_ UtilityTotalReactivePower : 0|32@1+ (1,-2000000000) [-2000000000|0] "+2,211,081,215 Var" Vector__XXX

BO_ 2147548664 UTACP: 8 Vector__XXX
 SG_ UtilityTotalApparentPower : 32|32@1+ (1,-2000000000) [-2000000000|0] "+2,211,081,215 VA" Vector__XXX
 SG_ UtilityTotalRealPower : 0|32@1+ (1,-2000000000) [-2000000000|0] "+2,211,081,215 Watts" Vector__XXX

BO_ 2147548653 UTACE: 8 Vector__XXX
 SG_ UtilityTotalKWHoursImport : 32|32@1+ (1,0) [-83886081|0] "kWh" Vector__XXX
 SG_ UtilityTotalKWHoursExport : 0|32@1+ (1,0) [-83886081|0] "kWh" Vector__XXX

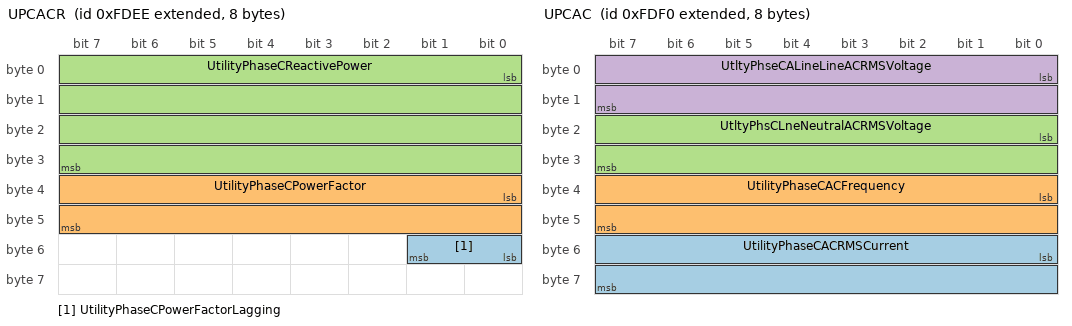
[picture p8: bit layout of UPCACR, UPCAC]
BO_ 2147548654 UPCACR: 8 Vector__XXX
 SG_ UtilityPhaseCPowerFactorLagging : 48|2@1+ (1,0) [0|3] "" Vector__XXX
 SG_ UtilityPhaseCPowerFactor : 32|16@1+ (1,-1) [-1|0] "+2.921814" Vector__XXX
 SG_ UtilityPhaseCReactivePower : 0|32@1+ (1,-2000000000) [-2000000000|0] "+2,211,081,215 Var" Vector__XXX

BO_ 2147548655 UPCACP: 8 Vector__XXX
 SG_ UtilityPhaseCApparentPower : 32|32@1+ (1,-2000000000) [-2000000000|0] "+2,211,081,215 VA" Vector__XXX
 SG_ UtilityPhaseCRealPower : 0|32@1+ (1,-2000000000) [-2000000000|0] "+2,211,081,215 Watts" Vector__XXX

BO_ 2147548656 UPCAC: 8 Vector__XXX
 SG_ UtilityPhaseCACRMSCurrent : 48|16@1+ (1,0) [0|64255] "Amps" Vector__XXX
 SG_ UtilityPhaseCACFrequency : 32|16@1+ (1,0) [0|501.9921875] "Hz" Vector__XXX
 SG_ UtltyPhsCLneNeutralACRMSVoltage : 16|16@1+ (1,0) [0|64255] "Volts" Vector__XXX
 SG_ UtltyPhseCALineLineACRMSVoltage : 0|16@1+ (1,0) [0|64255] "Volts" Vector__XXX

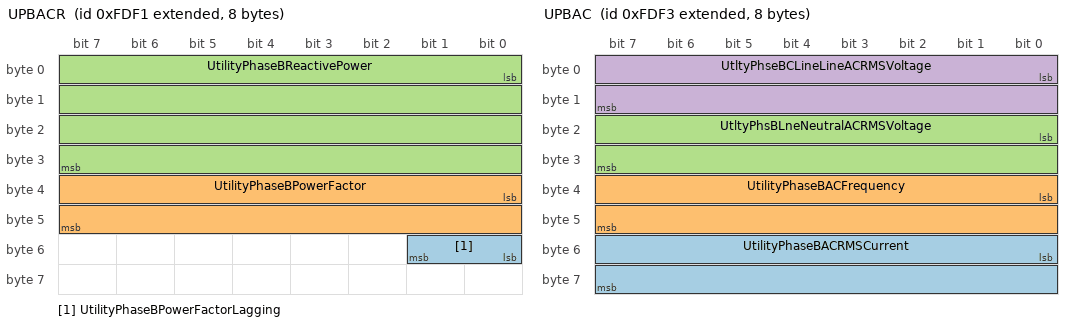
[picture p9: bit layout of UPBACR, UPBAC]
BO_ 2147548657 UPBACR: 8 Vector__XXX
 SG_ UtilityPhaseBPowerFactorLagging : 48|2@1+ (1,0) [0|3] "" Vector__XXX
 SG_ UtilityPhaseBPowerFactor : 32|16@1+ (1,-1) [-1|0] "+2.921814" Vector__XXX
 SG_ UtilityPhaseBReactivePower : 0|32@1+ (1,-2000000000) [-2000000000|0] "+2,211,081,215 Var" Vector__XXX

BO_ 2147548658 UPBACP: 8 Vector__XXX
 SG_ UtilityPhaseBApparentPower : 32|32@1+ (1,-2000000000) [-2000000000|0] "+2,211,081,215 VA" Vector__XXX
 SG_ UtilityPhaseBRealPower : 0|32@1+ (1,-2000000000) [-2000000000|0] "+2,211,081,215 Watts" Vector__XXX

BO_ 2147548659 UPBAC: 8 Vector__XXX
 SG_ UtilityPhaseBACRMSCurrent : 48|16@1+ (1,0) [0|64255] "Amps" Vector__XXX
 SG_ UtilityPhaseBACFrequency : 32|16@1+ (1,0) [0|501.9921875] "Hz" Vector__XXX
 SG_ UtltyPhsBLneNeutralACRMSVoltage : 16|16@1+ (1,0) [0|64255] "Volts" Vector__XXX
 SG_ UtltyPhseBCLineLineACRMSVoltage : 0|16@1+ (1,0) [0|64255] "Volts" Vector__XXX

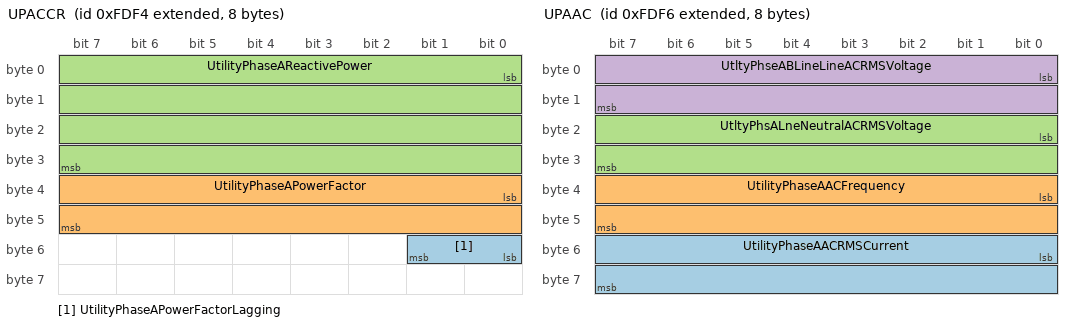
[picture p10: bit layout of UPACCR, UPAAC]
BO_ 2147548660 UPACCR: 8 Vector__XXX
 SG_ UtilityPhaseAPowerFactorLagging : 48|2@1+ (1,0) [0|3] "" Vector__XXX
 SG_ UtilityPhaseAPowerFactor : 32|16@1+ (1,-1) [-1|0] "+2.921814" Vector__XXX
 SG_ UtilityPhaseAReactivePower : 0|32@1+ (1,-2000000000) [-2000000000|0] "+2,211,081,215 Var" Vector__XXX

BO_ 2147548661 UPAACP: 8 Vector__XXX
 SG_ UtilityPhaseAApparentPower : 32|32@1+ (1,-2000000000) [-2000000000|0] "+2,211,081,215 VA" Vector__XXX
 SG_ UtilityPhaseARealPower : 0|32@1+ (1,-2000000000) [-2000000000|0] "+2,211,081,215 Watts" Vector__XXX

BO_ 2147548662 UPAAC: 8 Vector__XXX
 SG_ UtilityPhaseAACRMSCurrent : 48|16@1+ (1,0) [0|64255] "Amps" Vector__XXX
 SG_ UtilityPhaseAACFrequency : 32|16@1+ (1,0) [0|501.9921875] "Hz" Vector__XXX
 SG_ UtltyPhsALneNeutralACRMSVoltage : 16|16@1+ (1,0) [0|64255] "Volts" Vector__XXX
 SG_ UtltyPhseABLineLineACRMSVoltage : 0|16@1+ (1,0) [0|64255] "Volts" Vector__XXX

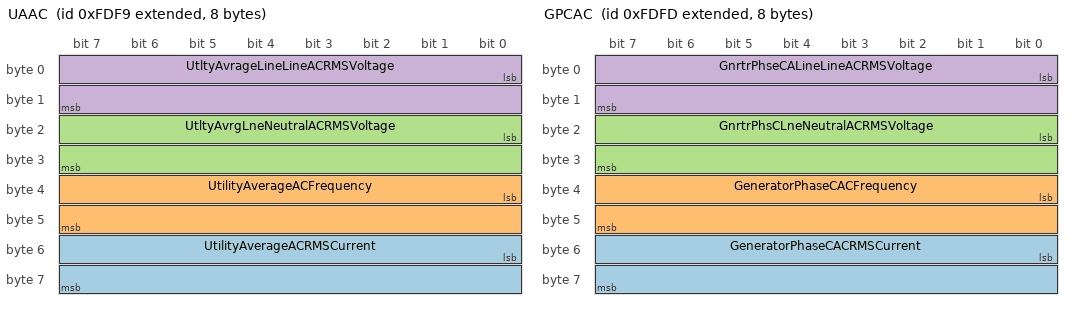
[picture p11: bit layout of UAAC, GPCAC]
BO_ 2147548665 UAAC: 8 Vector__XXX
 SG_ UtilityAverageACRMSCurrent : 48|16@1+ (1,0) [0|64255] "Amps" Vector__XXX
 SG_ UtilityAverageACFrequency : 32|16@1+ (1,0) [0|501.9921875] "Hz" Vector__XXX
 SG_ UtltyAvrgLneNeutralACRMSVoltage : 16|16@1+ (1,0) [0|64255] "Volts" Vector__XXX
 SG_ UtltyAvrageLineLineACRMSVoltage : 0|16@1+ (1,0) [0|64255] "Volts" Vector__XXX

BO_ 2147548676 GTACR: 8 Vector__XXX
 SG_ GnrtorOverallPowerFactorLagging : 48|2@1+ (1,0) [0|3] "" Vector__XXX
 SG_ GeneratorOverallPowerFactor : 32|16@1+ (1,-1) [-1|0] "+2.921814" Vector__XXX
 SG_ GeneratorTotalReactivePower : 0|32@1+ (1,-2000000000) [-2000000000|0] "+2,211,081,215 Var" Vector__XXX

BO_ 2147548677 GTACP: 8 Vector__XXX
 SG_ GeneratorTotalApparentPower : 32|32@1+ (1,-2000000000) [-2000000000|0] "+2,211,081,215 VA" Vector__XXX
 SG_ GeneratorTotalRealPower : 0|32@1+ (1,-2000000000) [-2000000000|0] "+2,211,081,215 Watts" Vector__XXX

BO_ 2147548666 GTACE: 8 Vector__XXX
 SG_ GeneratorTotalKWHoursImport : 32|32@1+ (1,0) [-83886081|0] "kWh" Vector__XXX
 SG_ GeneratorTotalKWHoursExport : 0|32@1+ (1,0) [-83886081|0] "kWh" Vector__XXX

BO_ 2147548667 GPCACR: 8 Vector__XXX
 SG_ GnratorPhaseCPowerFactorLagging : 48|2@1+ (1,0) [0|3] "" Vector__XXX
 SG_ GeneratorPhaseCPowerFactor : 32|16@1+ (1,-1) [-1|0] "+2.921814" Vector__XXX
 SG_ GeneratorPhaseCReactivePower : 0|32@1+ (1,-2000000000) [-2000000000|0] "+2,211,081,215 Var" Vector__XXX

BO_ 2147548668 GPCACP: 8 Vector__XXX
 SG_ GeneratorPhaseCApparentPower : 32|32@1+ (1,-2000000000) [-2000000000|0] "+2,211,081,215 VA" Vector__XXX
 SG_ GeneratorPhaseCRealPower : 0|32@1+ (1,-2000000000) [-2000000000|0] "+2,211,081,215 Watts" Vector__XXX

BO_ 2147548669 GPCAC: 8 Vector__XXX
 SG_ GeneratorPhaseCACRMSCurrent : 48|16@1+ (1,0) [0|64255] "Amps" Vector__XXX
 SG_ GeneratorPhaseCACFrequency : 32|16@1+ (1,0) [0|501.9921875] "Hz" Vector__XXX
 SG_ GnrtrPhsCLneNeutralACRMSVoltage : 16|16@1+ (1,0) [0|64255] "Volts" Vector__XXX
 SG_ GnrtrPhseCALineLineACRMSVoltage : 0|16@1+ (1,0) [0|64255] "Volts" Vector__XXX

BO_ 2147548670 GPBACRP: 8 Vector__XXX
 SG_ GnratorPhaseBPowerFactorLagging : 48|2@1+ (1,0) [0|3] "" Vector__XXX
 SG_ GeneratorPhaseBPowerFactor : 32|16@1+ (1,-1) [-1|0] "+2.921814" Vector__XXX
 SG_ GeneratorPhaseBReactivePower : 0|32@1+ (1,-2000000000) [-2000000000|0] "+2,211,081,215 Var" Vector__XXX

BO_ 2147548671 GPBACP: 8 Vector__XXX
 SG_ GeneratorPhaseBApparentPower : 32|32@1+ (1,-2000000000) [-2000000000|0] "+2,211,081,215 VA" Vector__XXX
 SG_ GeneratorPhaseBRealPower : 0|32@1+ (1,-2000000000) [-2000000000|0] "+2,211,081,215 Watts" Vector__XXX

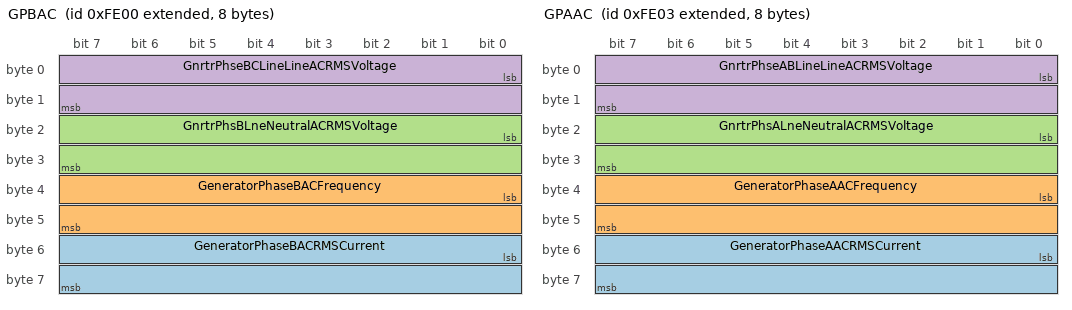
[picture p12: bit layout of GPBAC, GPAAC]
BO_ 2147548672 GPBAC: 8 Vector__XXX
 SG_ GeneratorPhaseBACRMSCurrent : 48|16@1+ (1,0) [0|64255] "Amps" Vector__XXX
 SG_ GeneratorPhaseBACFrequency : 32|16@1+ (1,0) [0|501.9921875] "Hz" Vector__XXX
 SG_ GnrtrPhsBLneNeutralACRMSVoltage : 16|16@1+ (1,0) [0|64255] "Volts" Vector__XXX
 SG_ GnrtrPhseBCLineLineACRMSVoltage : 0|16@1+ (1,0) [0|64255] "Volts" Vector__XXX

BO_ 2147548673 GPAACR: 8 Vector__XXX
 SG_ GnratorPhaseAPowerFactorLagging : 48|2@1+ (1,0) [0|3] "" Vector__XXX
 SG_ GeneratorPhaseAPowerFactor : 32|16@1+ (1,-1) [-1|0] "+2.921814" Vector__XXX
 SG_ GeneratorPhaseAReactivePower : 0|32@1+ (1,-2000000000) [-2000000000|0] "+2,211,081,215 Var" Vector__XXX

BO_ 2147548674 GPAACP: 8 Vector__XXX
 SG_ GeneratorPhaseAApparentPower : 32|32@1+ (1,-2000000000) [-2000000000|0] "+2,211,081,215 VA" Vector__XXX
 SG_ GeneratorPhaseARealPower : 0|32@1+ (1,-2000000000) [-2000000000|0] "+2,211,081,215 Watts" Vector__XXX

BO_ 2147548675 GPAAC: 8 Vector__XXX
 SG_ GeneratorPhaseAACRMSCurrent : 48|16@1+ (1,0) [0|64255] "Amps" Vector__XXX
 SG_ GeneratorPhaseAACFrequency : 32|16@1+ (1,0) [0|501.9921875] "Hz" Vector__XXX
 SG_ GnrtrPhsALneNeutralACRMSVoltage : 16|16@1+ (1,0) [0|64255] "Volts" Vector__XXX
 SG_ GnrtrPhseABLineLineACRMSVoltage : 0|16@1+ (1,0) [0|64255] "Volts" Vector__XXX

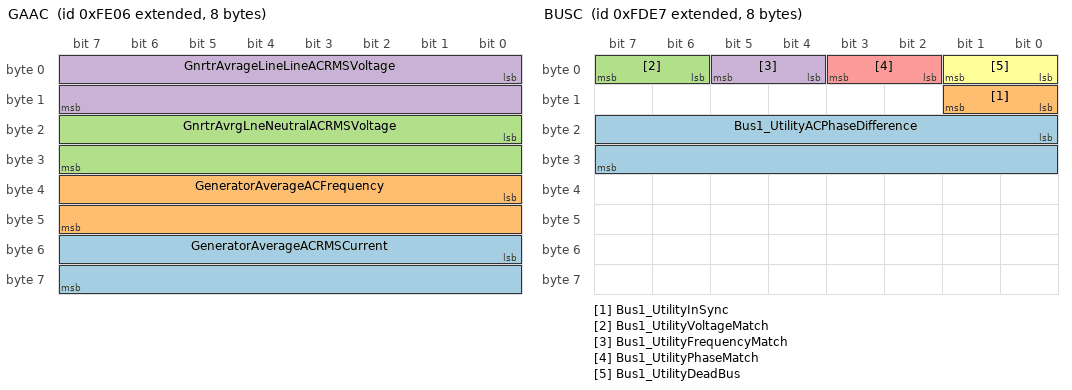
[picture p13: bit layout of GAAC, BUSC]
BO_ 2147548678 GAAC: 8 Vector__XXX
 SG_ GeneratorAverageACRMSCurrent : 48|16@1+ (1,0) [0|64255] "Amps" Vector__XXX
 SG_ GeneratorAverageACFrequency : 32|16@1+ (1,0) [0|501.9921875] "Hz" Vector__XXX
 SG_ GnrtrAvrgLneNeutralACRMSVoltage : 16|16@1+ (1,0) [0|64255] "Volts" Vector__XXX
 SG_ GnrtrAvrageLineLineACRMSVoltage : 0|16@1+ (1,0) [0|64255] "Volts" Vector__XXX

BO_ 2147548647 BUSC: 8 Vector__XXX
 SG_ Bus1_UtilityACPhaseDifference : 16|16@1+ (1,-200) [-200|301.99] "deg" Vector__XXX
 SG_ Bus1_UtilityInSync : 8|2@1+ (1,0) [0|3] "" Vector__XXX
 SG_ Bus1_UtilityVoltageMatch : 6|2@1+ (1,0) [0|3] "" Vector__XXX
 SG_ Bus1_UtilityFrequencyMatch : 4|2@1+ (1,0) [0|3] "" Vector__XXX
 SG_ Bus1_UtilityPhaseMatch : 2|2@1+ (1,0) [0|3] "" Vector__XXX
 SG_ Bus1_UtilityDeadBus : 0|2@1+ (1,0) [0|3] "" Vector__XXX

BO_ 2147548649 BPCAC: 8 Vector__XXX
 SG_ Bus1PhaseCACFrequency : 32|16@1+ (1,0) [0|501.9921875] "Hz" Vector__XXX
 SG_ Bs1PhseCLineNeutralACRMSVoltage : 16|16@1+ (1,0) [0|64255] "Volts" Vector__XXX
 SG_ Bus1PhaseCALineLineACRMSVoltage : 0|16@1+ (1,0) [0|64255] "Volts" Vector__XXX

BO_ 2147548650 BPBAC: 8 Vector__XXX
 SG_ Bus1PhaseBACFrequency : 32|16@1+ (1,0) [0|501.9921875] "Hz" Vector__XXX
 SG_ Bs1PhseBLineNeutralACRMSVoltage : 16|16@1+ (1,0) [0|64255] "Volts" Vector__XXX
 SG_ Bus1PhaseBCLineLineACRMSVoltage : 0|16@1+ (1,0) [0|64255] "Volts" Vector__XXX

BO_ 2147548651 BPAAC: 8 Vector__XXX
 SG_ Bus1PhaseAACFrequency : 32|16@1+ (1,0) [0|501.9921875] "Hz" Vector__XXX
 SG_ Bs1PhseALineNeutralACRMSVoltage : 16|16@1+ (1,0) [0|64255] "Volts" Vector__XXX
 SG_ Bus1PhaseABLineLineACRMSVoltage : 0|16@1+ (1,0) [0|64255] "Volts" Vector__XXX

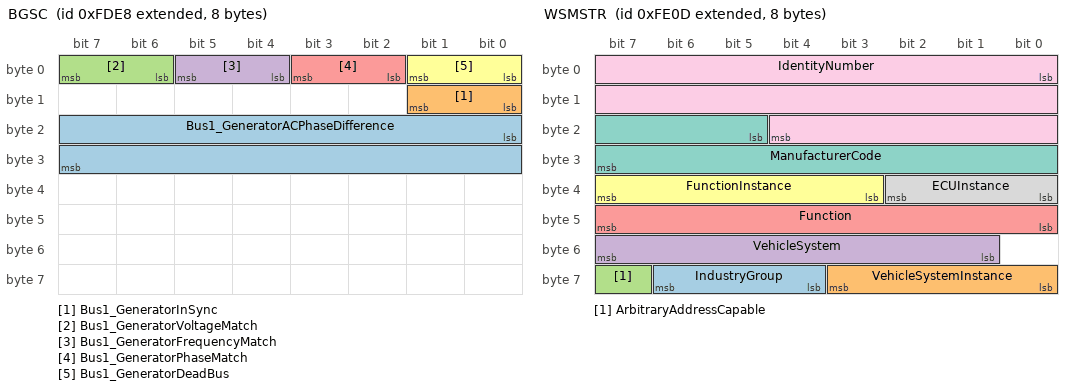
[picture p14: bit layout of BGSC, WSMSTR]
BO_ 2147548648 BGSC: 8 Vector__XXX
 SG_ Bus1_GeneratorACPhaseDifference : 16|16@1+ (1,-200) [-200|301.99] "deg" Vector__XXX
 SG_ Bus1_GeneratorInSync : 8|2@1+ (1,0) [0|3] "" Vector__XXX
 SG_ Bus1_GeneratorVoltageMatch : 6|2@1+ (1,0) [0|3] "" Vector__XXX
 SG_ Bus1_GeneratorFrequencyMatch : 4|2@1+ (1,0) [0|3] "" Vector__XXX
 SG_ Bus1_GeneratorPhaseMatch : 2|2@1+ (1,0) [0|3] "" Vector__XXX
 SG_ Bus1_GeneratorDeadBus : 0|2@1+ (1,0) [0|3] "" Vector__XXX

BO_ 2147548652 BAAC: 8 Vector__XXX
 SG_ Bus1AverageACFrequency : 32|16@1+ (1,0) [0|501.9921875] "Hz" Vector__XXX
 SG_ Bs1AvrgeLineNeutralACRMSVoltage : 16|16@1+ (1,0) [0|64255] "Volts" Vector__XXX
 SG_ Bus1AverageLineLineACRMSVoltage : 0|16@1+ (1,0) [0|64255] "Volts" Vector__XXX

BO_ 2147548685 WSMSTR: 8 Vector__XXX
 SG_ IndustryGroup : 60|3@1+ (1,0) [0|7] "" Vector__XXX
 SG_ VehicleSystemInstance : 56|4@1+ (1,0) [0|15] "" Vector__XXX
 SG_ ArbitraryAddressCapable : 63|1@1+ (1,0) [0|1] "" Vector__XXX
 SG_ VehicleSystem : 49|7@1+ (1,0) [0|127] "" Vector__XXX
 SG_ Function : 40|8@1+ (1,0) [0|255] "" Vector__XXX
 SG_ FunctionInstance : 35|5@1+ (1,0) [0|31] "" Vector__XXX
 SG_ ManufacturerCode : 21|11@1+ (1,0) [0|2047] "" Vector__XXX
 SG_ ECUInstance : 32|3@1+ (1,0) [0|7] "" Vector__XXX
 SG_ IdentityNumber : 0|21@1+ (1,0) [0|2097152] "" Vector__XXX

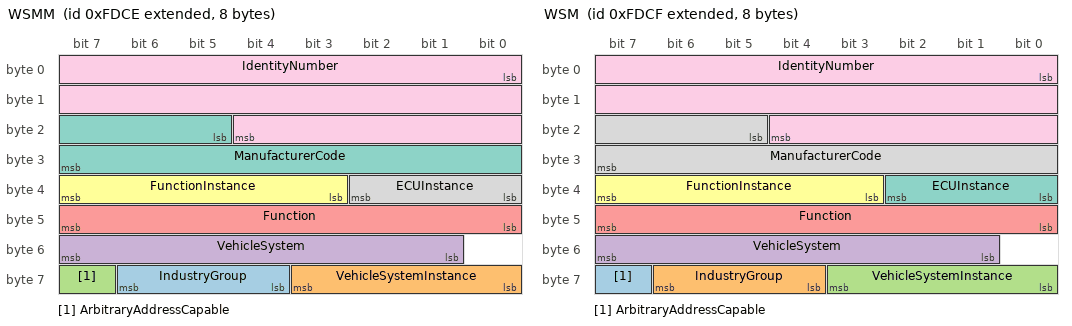
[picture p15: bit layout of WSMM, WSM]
BO_ 2147548622 WSMM: 8 Vector__XXX
 SG_ IndustryGroup : 60|3@1+ (1,0) [0|7] "" Vector__XXX
 SG_ VehicleSystemInstance : 56|4@1+ (1,0) [0|15] "" Vector__XXX
 SG_ ArbitraryAddressCapable : 63|1@1+ (1,0) [0|1] "" Vector__XXX
 SG_ VehicleSystem : 49|7@1+ (1,0) [0|127] "" Vector__XXX
 SG_ Function : 40|8@1+ (1,0) [0|255] "" Vector__XXX
 SG_ FunctionInstance : 35|5@1+ (1,0) [0|31] "" Vector__XXX
 SG_ ManufacturerCode : 21|11@1+ (1,0) [0|2047] "" Vector__XXX
 SG_ ECUInstance : 32|3@1+ (1,0) [0|7] "" Vector__XXX
 SG_ IdentityNumber : 0|21@1+ (1,0) [0|2097152] "" Vector__XXX

BO_ 2147548623 WSM: 8 Vector__XXX
 SG_ ArbitraryAddressCapable : 63|1@1+ (1,0) [0|1] "" Vector__XXX
 SG_ IndustryGroup : 60|3@1+ (1,0) [0|7] "" Vector__XXX
 SG_ VehicleSystemInstance : 56|4@1+ (1,0) [0|15] "" Vector__XXX
 SG_ VehicleSystem : 49|7@1+ (1,0) [0|127] "" Vector__XXX
 SG_ Function : 40|8@1+ (1,0) [0|255] "" Vector__XXX
 SG_ FunctionInstance : 35|5@1+ (1,0) [0|31] "" Vector__XXX
 SG_ ECUInstance : 32|3@1+ (1,0) [0|7] "" Vector__XXX
 SG_ ManufacturerCode : 21|11@1+ (1,0) [0|2047] "" Vector__XXX
 SG_ IdentityNumber : 0|21@1+ (1,0) [0|2097152] "" Vector__XXX

BO_ 2147548888 CA: 9 Vector__XXX
 SG_ ArbitraryAddressCapable : 63|1@1+ (1,0) [0|1] "" Vector__XXX
 SG_ IndustryGroup : 60|3@1+ (1,0) [0|7] "" Vector__XXX
 SG_ VehicleSystemInstance : 56|4@1+ (1,0) [0|15] "" Vector__XXX
 SG_ VehicleSystem : 49|7@1+ (1,0) [0|127] "" Vector__XXX
 SG_ Function : 40|8@1+ (1,0) [0|255] "" Vector__XXX
 SG_ FunctionInstance : 35|5@1+ (1,0) [0|31] "" Vector__XXX
 SG_ ECUInstance : 32|3@1+ (1,0) [0|7] "" Vector__XXX
 SG_ ManufacturerCode : 21|11@1+ (1,0) [0|2047] "" Vector__XXX
 SG_ IdentityNumber : 0|21@1+ (1,0) [0|2097152] "" Vector__XXX
 SG_ AddressAssignment : 64|8@1+ (1,0) [0|255] "" Vector__XXX

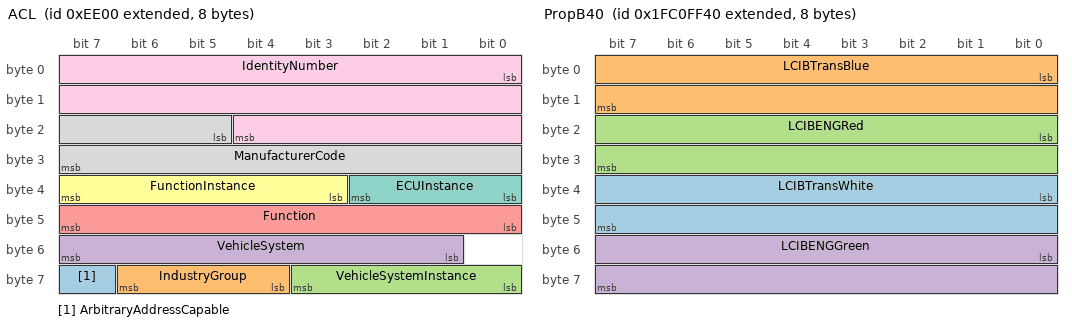
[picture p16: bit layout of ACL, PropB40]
BO_ 2147544576 ACL: 8 Vector__XXX
 SG_ ArbitraryAddressCapable : 63|1@1+ (1,0) [0|1] "" Vector__XXX
 SG_ IndustryGroup : 60|3@1+ (1,0) [0|7] "" Vector__XXX
 SG_ VehicleSystemInstance : 56|4@1+ (1,0) [0|15] "" Vector__XXX
 SG_ VehicleSystem : 49|7@1+ (1,0) [0|127] "" Vector__XXX
 SG_ Function : 40|8@1+ (1,0) [0|255] "" Vector__XXX
 SG_ FunctionInstance : 35|5@1+ (1,0) [0|31] "" Vector__XXX
 SG_ ECUInstance : 32|3@1+ (1,0) [0|7] "" Vector__XXX
 SG_ ManufacturerCode : 21|11@1+ (1,0) [0|2047] "" Vector__XXX
 SG_ IdentityNumber : 0|21@1+ (1,0) [0|2097152] "" Vector__XXX

BO_ 2147535360 XFER: 8 Vector__XXX
 SG_ ShrtNameOfActualReportingDevice : 32|32@1+ (1,0) [0|0] "(2^32 - 1)" Vector__XXX
 SG_ LengthOfDataForTheReportedPGN : 24|8@1+ (1,0) [0|255] "" Vector__XXX
 SG_ PGNofRequstedInformation : 0|24@1+ (1,0) [0|16777215] "" Vector__XXX

BO_ 2147543808 TPDT: 8 Vector__XXX
 SG_ SequenceNumber : 0|8@1+ (1,0) [0|252] "" Vector__XXX

BO_ 2147544064 TPCM: 8 Vector__XXX
 SG_ PGNumber m255 : 40|24@1+ (1,0) [0|16777215] "" Vector__XXX
 SG_ ConnectionAbortReason m255 : 8|8@1+ (1,0) [0|255] "" Vector__XXX
 SG_ NextPacketNumberToBeSent m17 : 16|8@1+ (1,0) [0|255] "" Vector__XXX
 SG_ NumberOfPacketsThatCanBeSent m17 : 8|8@1+ (1,0) [0|255] "" Vector__XXX
 SG_ PGNumber m32 : 40|24@1+ (1,0) [0|16777200] "" Vector__XXX
 SG_ MaximumNumberOfPackets m16 : 32|8@1+ (1,0) [0|255] "" Vector__XXX
 SG_ TotalNumberOfPackets m32 : 24|8@1+ (1,0) [0|255] "" Vector__XXX
 SG_ TotalMessageSize m32 : 8|16@1+ (1,0) [0|64255] "counts" Vector__XXX
 SG_ ControlByte M : 0|8@1+ (1,0) [0|255] "" Vector__XXX

BO_ 2147535104 RQST2: 8 Vector__XXX
 SG_ UseTransferMode : 24|2@1+ (1,0) [0|3] "" Vector__XXX
 SG_ ParameterGroupNumber : 0|24@1+ (1,0) [0|16777215] "" Vector__XXX

BO_ 2147543552 RQST: 3 Vector__XXX
 SG_ RqstedPGN : 0|24@1+ (1,0) [0|16777215] "" Vector__XXX

BO_ 2680225791 PropBFF: 8 Vector__XXX

BO_ 2680225790 PropBFE: 8 Vector__XXX

BO_ 2680225789 PropBFD: 8 Vector__XXX

BO_ 2680225788 PropBFC: 8 Vector__XXX

BO_ 2680225787 PropBFB: 8 Vector__XXX

BO_ 2680225786 PropBFA: 8 Vector__XXX

BO_ 2680225785 PropBF9: 8 Vector__XXX

BO_ 2680225784 PropBF8: 8 Vector__XXX

BO_ 2680225783 PropBF7: 8 Vector__XXX

BO_ 2680225782 PropBF6: 8 Vector__XXX

BO_ 2680225781 PropBF5: 8 Vector__XXX

BO_ 2680225780 PropBF4: 8 Vector__XXX

BO_ 2680225779 PropBF3: 8 Vector__XXX

BO_ 2680225778 PropBF2: 8 Vector__XXX

BO_ 2680225777 PropBF1: 8 Vector__XXX

BO_ 2680225776 PropBF0: 8 Vector__XXX

BO_ 2680225775 PropBEF: 8 Vector__XXX

BO_ 2680225774 PropBEE: 8 Vector__XXX

BO_ 2680225773 PropBED: 8 Vector__XXX

BO_ 2680225772 PropBEC: 8 Vector__XXX

BO_ 2680225771 PropBEB: 8 Vector__XXX

BO_ 2680225770 PropBEA: 8 Vector__XXX

BO_ 2680225769 PropBE9: 8 Vector__XXX

BO_ 2680225768 PropBE8: 8 Vector__XXX

BO_ 2680225767 PropBE7: 8 Vector__XXX

BO_ 2680225766 PropBE6: 8 Vector__XXX

BO_ 2680225765 PropBE5: 8 Vector__XXX

BO_ 2680225764 PropBE4: 8 Vector__XXX

BO_ 2680225763 PropBE3: 8 Vector__XXX

BO_ 2680225762 PropBE2: 8 Vector__XXX

BO_ 2680225761 PropBE1: 8 Vector__XXX

BO_ 2680225760 PropBE0: 8 Vector__XXX

BO_ 2680225759 PropBDF: 8 Vector__XXX

BO_ 2680225758 PropBDE: 8 Vector__XXX

BO_ 2680225757 PropBDD: 8 Vector__XXX

BO_ 2680225756 PropBDC: 8 Vector__XXX

BO_ 2680225755 PropBDB: 8 Vector__XXX

BO_ 2680225754 PropBDA: 8 Vector__XXX

BO_ 2680225753 PropBD9: 8 Vector__XXX

BO_ 2680225752 PropBD8: 8 Vector__XXX

BO_ 2680225751 PropBD7: 8 Vector__XXX

BO_ 2680225750 PropBD6: 8 Vector__XXX

BO_ 2680225749 PropBD5: 8 Vector__XXX

BO_ 2680225748 PropBD4: 8 Vector__XXX

BO_ 2680225747 PropBD3: 8 Vector__XXX

BO_ 2680225746 PropBD2: 8 Vector__XXX

BO_ 2680225745 PropBD1: 8 Vector__XXX

BO_ 2680225744 PropBD0: 8 Vector__XXX

BO_ 2680225743 PropBCF: 8 Vector__XXX

BO_ 2680225742 PropBCE: 8 Vector__XXX

BO_ 2680225741 PropBCD: 8 Vector__XXX

BO_ 2680225740 PropBCC: 8 Vector__XXX

BO_ 2680225739 PropBCB: 8 Vector__XXX

BO_ 2680225738 PropBCA: 8 Vector__XXX

BO_ 2680225737 PropBC9: 8 Vector__XXX

BO_ 2680225736 PropBC8: 8 Vector__XXX

BO_ 2680225735 PropBC7: 8 Vector__XXX

BO_ 2680225734 PropBC6: 8 Vector__XXX

BO_ 2680225733 PropBC5: 8 Vector__XXX

BO_ 2680225627 PropB5B: 8 Vector__XXX

BO_ 2680225626 PropB5A: 8 Vector__XXX

BO_ 2680225625 PropB59: 8 Vector__XXX

BO_ 2680225624 PropB58: 8 Vector__XXX

BO_ 2680225623 PropB57: 8 Vector__XXX

BO_ 2680225622 PropB56: 8 Vector__XXX

BO_ 2680225621 PropB55: 8 Vector__XXX

BO_ 2680225620 PropB54: 8 Vector__XXX

BO_ 2680225619 PropB53: 8 Vector__XXX

BO_ 2680225618 PropB52: 8 Vector__XXX

BO_ 2680225617 PropB51: 8 Vector__XXX

BO_ 2680225616 PropB50: 8 Vector__XXX

BO_ 2680225615 PropB4F: 8 Vector__XXX

BO_ 2680225614 PropB4E: 8 Vector__XXX

BO_ 2680225613 PropB4D: 8 Vector__XXX

BO_ 2680225612 PropB4C: 8 Vector__XXX

BO_ 2680225611 PropB4B: 8 Vector__XXX

BO_ 2680225610 PropB4A: 8 Vector__XXX

BO_ 2680225609 PropB49: 8 Vector__XXX

BO_ 2680225608 PropB48: 8 Vector__XXX

BO_ 2680225607 PropB47: 6 Vector__XXX
 SG_ FrontAxlePSI : 32|16@1- (0.005722,-18.75) [0|0] "PSI" Vector__XXX
 SG_ RearDriverTandemPSI : 16|16@1- (0.005722,-18.75) [0|0] "PSI" Vector__XXX
 SG_ RearPassTandemPSI : 0|16@1- (0.005722,-18.75) [0|0] "PSI" Vector__XXX

BO_ 2680225606 PropB46: 8 Vector__XXX

BO_ 2680225605 PropB45: 8 Vector__XXX

BO_ 2680225604 PropB44: 8 Vector__XXX

BO_ 2680225603 PropB43: 2 Vector__XXX
 SG_ Driveline_Torque : 0|16@1- (1.22074,0) [-40000|400000] "LBFT" Vector__XXX

BO_ 2680225602 PropB42: 8 Vector__XXX

BO_ 2680225601 PropB41: 4 Vector__XXX
 SG_ ClutchHouseAmbPass : 16|16@1- (0.0625,0) [0|0] "C" Vector__XXX
 SG_ ClutchHouseAmbDriv : 0|16@1- (0.0625,0) [0|0] "C" Vector__XXX

BO_ 2680225600 PropB40: 8 Vector__XXX
 SG_ LCIBTransWhite : 32|16@1- (0.0625,0) [0|0] "C" Vector__XXX
 SG_ LCIBTransBlue : 0|16@1- (0.0625,0) [0|0] "C" Vector__XXX
 SG_ LCIBENGRed : 16|16@1- (0.0625,0) [0|0] "C" Vector__XXX
 SG_ LCIBENGGreen : 48|16@1- (0.0625,0) [0|0] "C" Vector__XXX

BO_ 2680225599 PropB3F: 8 Vector__XXX

BO_ 2680225598 PropB3E: 8 Vector__XXX

BO_ 2680225597 PropB3D: 8 Vector__XXX

BO_ 2680225596 PropB3C: 8 Vector__XXX

BO_ 2680225595 PropB3B: 8 Vector__XXX

BO_ 2680225594 PropB3A: 8 Vector__XXX

BO_ 2680225593 PropB39: 8 Vector__XXX

BO_ 2680225592 PropB38: 8 Vector__XXX

BO_ 2680225591 PropB37: 8 Vector__XXX

BO_ 2680225590 PropB36: 8 Vector__XXX

BO_ 2680225589 PropB35: 8 Vector__XXX

BO_ 2680225588 PropB34: 8 Vector__XXX

BO_ 2680225587 PropB33: 8 Vector__XXX

BO_ 2680225586 PropB32: 8 Vector__XXX

BO_ 2680225585 PropB31: 8 Vector__XXX

BO_ 2680225584 PropB30: 8 Vector__XXX

BO_ 2680225583 PropB2F: 8 Vector__XXX

BO_ 2680225582 PropB2E: 8 Vector__XXX

BO_ 2680225581 PropB2D: 8 Vector__XXX

BO_ 2680225580 PropB2C: 8 Vector__XXX

BO_ 2680225579 PropB2B: 8 Vector__XXX

BO_ 2680225578 PropB2A: 8 Vector__XXX

BO_ 2680225577 PropB29: 8 Vector__XXX

BO_ 2680225576 PropB28: 8 Vector__XXX

BO_ 2680225575 PropB27: 8 Vector__XXX

BO_ 2680225574 PropB26: 8 Vector__XXX

BO_ 2680225573 PropB25: 8 Vector__XXX

BO_ 2680225572 PropB24: 8 Vector__XXX

BO_ 2680225571 PropB23: 8 Vector__XXX

BO_ 2680225570 PropB22: 8 Vector__XXX

BO_ 2680225569 PropB21: 8 Vector__XXX

BO_ 2680225568 PropB20: 8 Vector__XXX

BO_ 2680225567 PropB1F: 8 Vector__XXX

BO_ 2680225566 PropB1E: 8 Vector__XXX

BO_ 2680225565 PropB1D: 8 Vector__XXX

BO_ 2680225564 PropB1C: 8 Vector__XXX

BO_ 2680225563 PropB1B: 8 Vector__XXX

BO_ 2680225562 PropB1A: 8 Vector__XXX

BO_ 2680225561 PropB19: 8 Vector__XXX

BO_ 2680225560 PropB18: 8 Vector__XXX

BO_ 2680225559 PropB17: 8 Vector__XXX

BO_ 2680225558 PropB16: 8 Vector__XXX

BO_ 2680225662 PropB7E: 8 Vector__XXX

BO_ 2680225661 PropB7D: 8 Vector__XXX

BO_ 2680225660 PropB7C: 8 Vector__XXX

BO_ 2680225659 PropB7B: 8 Vector__XXX

BO_ 2680225658 PropB7A: 8 Vector__XXX

BO_ 2680225657 PropB79: 8 Vector__XXX

BO_ 2680225656 PropB78: 8 Vector__XXX

BO_ 2680225655 PropB77: 8 Vector__XXX

BO_ 2680225654 PropB76: 8 Vector__XXX

BO_ 2680225653 PropB75: 8 Vector__XXX

BO_ 2680225652 PropB74: 8 Vector__XXX

BO_ 2680225651 PropB73: 8 Vector__XXX

BO_ 2680225650 PropB72: 8 Vector__XXX

BO_ 2680225649 PropB71: 8 Vector__XXX

BO_ 2680225648 PropB70: 8 Vector__XXX

BO_ 2680225647 PropB6F: 8 Vector__XXX

BO_ 2680225646 PropB6E: 8 Vector__XXX

BO_ 2680225645 PropB6D: 8 Vector__XXX

BO_ 2680225644 PropB6C: 8 Vector__XXX

BO_ 2680225643 PropB6B: 8 Vector__XXX

BO_ 2680225642 PropB6A: 8 Vector__XXX

BO_ 2680225641 PropB69: 8 Vector__XXX

BO_ 2680225640 PropB68: 8 Vector__XXX

BO_ 2680225639 PropB67: 8 Vector__XXX

BO_ 2680225638 PropB66: 8 Vector__XXX

BO_ 2680225637 PropB65: 8 Vector__XXX

BO_ 2680225636 PropB64: 8 Vector__XXX

BO_ 2680225635 PropB63: 8 Vector__XXX

BO_ 2680225634 PropB62: 8 Vector__XXX

BO_ 2680225633 PropB61: 8 Vector__XXX

BO_ 2680225632 PropB60: 8 Vector__XXX

BO_ 2680225631 PropB5F: 8 Vector__XXX

BO_ 2680225630 PropB5E: 8 Vector__XXX

BO_ 2680225629 PropB5D: 8 Vector__XXX

BO_ 2680225628 PropB5C: 8 Vector__XXX

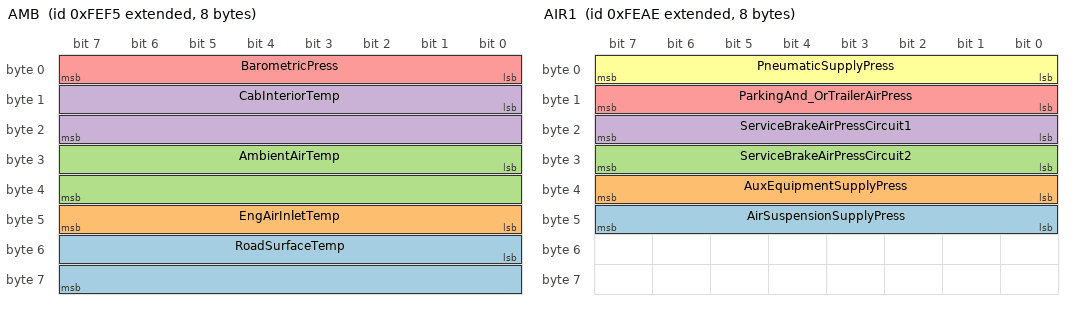
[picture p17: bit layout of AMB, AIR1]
BO_ 2147548917 AMB: 8 Vector__XXX
 SG_ RoadSurfaceTemp : 48|16@1+ (0.03125,-273) [-273|1735] "deg" Vector__XXX
 SG_ EngAirInletTemp : 40|8@1+ (1,-40) [-40|210] "deg" Vector__XXX
 SG_ AmbientAirTemp : 24|16@1+ (0.03125,-273) [-273|1735] "deg" Vector__XXX
 SG_ CabInteriorTemp : 8|16@1+ (0.03125,-273) [-273|1735] "deg" Vector__XXX
 SG_ BarometricPress : 0|8@1+ (0.5,0) [0|125] "kPa" Vector__XXX

BO_ 2147548894 AIR2: 8 Vector__XXX
 SG_ EngAirStartPress : 0|8@1+ (4,0) [0|1000] "kPa" Vector__XXX

BO_ 2147548846 AIR1: 8 Vector__XXX
 SG_ AirSuspensionSupplyPress : 40|8@1+ (8,0) [0|2000] "kPa" Vector__XXX
 SG_ AuxEquipmentSupplyPress : 32|8@1+ (8,0) [0|2000] "kPa" Vector__XXX
 SG_ ServiceBrakeAirPressCircuit2 : 24|8@1+ (8,0) [0|2000] "kPa" Vector__XXX
 SG_ ServiceBrakeAirPressCircuit1 : 16|8@1+ (8,0) [0|2000] "kPa" Vector__XXX
 SG_ ParkingAnd_OrTrailerAirPress : 8|8@1+ (8,0) [0|2000] "kPa" Vector__XXX
 SG_ PneumaticSupplyPress : 0|8@1+ (8,0) [0|2000] "kPa" Vector__XXX

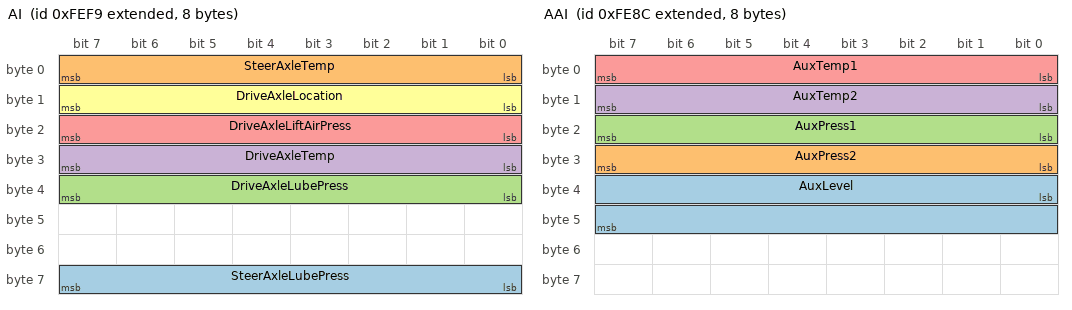
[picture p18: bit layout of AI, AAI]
BO_ 2147548921 AI: 8 Vector__XXX
 SG_ SteerAxleLubePress : 56|8@1+ (4,0) [0|1000] "kPa" Vector__XXX
 SG_ SteerAxleTemp : 0|8@1+ (1,-40) [-40|210] "deg" Vector__XXX
 SG_ DriveAxleLubePress : 32|8@1+ (4,0) [0|1000] "kPa" Vector__XXX
 SG_ DriveAxleTemp : 24|8@1+ (1,-40) [-40|210] "deg" Vector__XXX
 SG_ DriveAxleLiftAirPress : 16|8@1+ (4,0) [0|1000] "kPa" Vector__XXX
 SG_ DriveAxleLocation : 8|8@1+ (1,0) [0|255] "" Vector__XXX

BO_ 2147548842 AF2: 8 Vector__XXX
 SG_ EngTurboWastegateValvePos : 24|8@1+ (0.4,0) [0|100] "%" Vector__XXX
 SG_ EngGsMssFlwSnsrFelingCorrection : 32|8@1+ (1,-125) [-125|125] "%" Vector__XXX
 SG_ EngDsiredAbsIntakeManifoldPress : 8|16@1+ (0.1,0) [0|6425.5] "kPa" Vector__XXX
 SG_ EngGasFuelCorrectionFactor : 0|8@1+ (1,0) [0|250] "%" Vector__XXX

BO_ 2147548753 ACC2: 8 Vector__XXX
 SG_ RqedACCDistanceMode : 5|3@1+ (1,0) [0|7] "" Vector__XXX

BO_ 2147548783 ACC1: 8 Vector__XXX
 SG_ ACCDistanceAlertSignal : 52|2@1+ (1,0) [0|3] "" Vector__XXX
 SG_ ACCSystemShutoffWarning : 50|2@1+ (1,0) [0|3] "" Vector__XXX
 SG_ ACCTargetDetected : 48|2@1+ (1,0) [0|3] "" Vector__XXX
 SG_ RoadCurvature : 32|16@1+ (1,-250) [-250|251.992] "1/km" Vector__XXX
 SG_ AdptveCruiseCtrlSetDistanceMode : 27|3@1+ (1,0) [0|7] "" Vector__XXX
 SG_ AdaptiveCruiseCtrlMode : 24|3@1+ (1,0) [0|7] "" Vector__XXX
 SG_ AdaptiveCruiseCtrlSetSpeed : 16|8@1+ (1,0) [0|250] "km/h" Vector__XXX
 SG_ DistanceToForwardVehicle : 8|8@1+ (1,0) [0|250] "m" Vector__XXX
 SG_ SpeedOfForwardVehicle : 0|8@1+ (1,0) [0|250] "km/h" Vector__XXX

BO_ 2147548840 AC: 8 Vector__XXX
 SG_ ArticulationAngle : 0|8@1+ (1,-125) [-125|125] "deg" Vector__XXX

BO_ 2147548812 AAI: 8 Vector__XXX
 SG_ AuxLevel : 32|16@1+ (0.1,0) [0|6425.5] "mm" Vector__XXX
 SG_ AuxPress2 : 24|8@1+ (16,0) [0|4000] "kPa" Vector__XXX
 SG_ AuxPress1 : 16|8@1+ (16,0) [0|4000] "kPa" Vector__XXX
 SG_ AuxTemp2 : 8|8@1+ (1,-40) [-40|210] "deg" Vector__XXX
 SG_ AuxTemp1 : 0|8@1+ (1,-40) [-40|210] "deg" Vector__XXX

BO_ 2147548925 A1: 8 Vector__XXX
 SG_ EngBlowerBypassValvePos : 0|8@1+ (0.4,0) [0|100] "%" Vector__XXX
 SG_ EngGasSupplyPress : 8|16@1+ (0.5,0) [0|32127.5] "kPa" Vector__XXX

BO_ 2680225557 PropB15: 8 Vector__XXX

BO_ 2680225556 PropB14: 8 Vector__XXX

BO_ 2680225555 PropB13: 8 Vector__XXX

BO_ 2680225554 PropB12: 8 Vector__XXX

BO_ 2680225553 PropB11: 8 Vector__XXX

BO_ 2680225552 PropB10: 8 Vector__XXX

BO_ 2680225551 PropB0F: 8 Vector__XXX

BO_ 2680225550 PropB0E: 8 Vector__XXX

BO_ 2680225549 PropB0D: 8 Vector__XXX

BO_ 2680225548 PropB0C: 8 Vector__XXX

BO_ 2680225547 PropB0B: 8 Vector__XXX

BO_ 2680225546 PropB0A: 8 Vector__XXX

BO_ 2680225545 PropB09: 8 Vector__XXX

BO_ 2680225544 PropB08: 8 Vector__XXX

BO_ 2680225543 PropB07: 8 Vector__XXX

BO_ 2680225542 PropB06: 8 Vector__XXX

BO_ 2680225541 PropB05: 4 Vector__XXX
 SG_ GradeExtSen : 0|16@1- (0.00029908,0) [-9.80025344|9.79995436] "" Vector__XXX
 SG_ GradeECASen : 16|16@1- (0.00029908,0) [-9.80025344|9.79995436] "" Vector__XXX

BO_ 2680225540 PropB04: 8 Vector__XXX

BO_ 2680225539 PropB03: 0 Vector__XXX

BO_ 2680225538 PropB02: 0 Vector__XXX

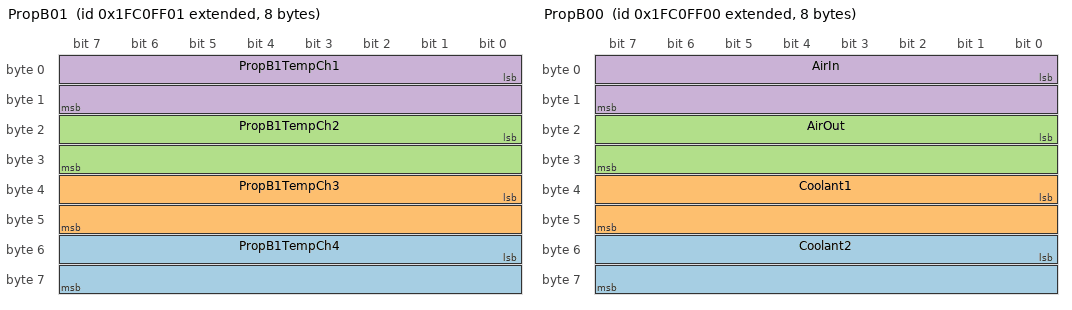
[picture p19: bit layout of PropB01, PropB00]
BO_ 2680225537 PropB01: 8 Vector__XXX
 SG_ PropB1TempCh4 : 48|16@1- (0.0625,0) [0|0] "" Vector__XXX
 SG_ PropB1TempCh3 : 32|16@1- (0.0625,0) [0|0] "" Vector__XXX
 SG_ PropB1TempCh2 : 16|16@1- (0.0625,0) [0|0] "" Vector__XXX
 SG_ PropB1TempCh1 : 0|16@1- (0.0625,0) [0|0] "" Vector__XXX

BO_ 2680225536 PropB00: 8 Vector__XXX
 SG_ Coolant2 : 48|16@1- (0.0625,0) [0|0] "" Vector__XXX
 SG_ Coolant1 : 32|16@1- (0.0625,0) [0|0] "" Vector__XXX
 SG_ AirOut : 16|16@1- (0.0625,0) [0|0] "" Vector__XXX
 SG_ AirIn : 0|16@1- (0.0625,0) [0|0] "" Vector__XXX

BO_ 2680221694 PropA: 8 Vector__XXX

BO_ 2147543040 ACKM: 8 Vector__XXX
 SG_ PGNumber m3 : 40|24@1+ (1,0) [0|16777215] "" Vector__XXX
 SG_ GroupFunctionValue m3 : 8|8@1+ (1,0) [0|255] "" Vector__XXX
 SG_ CtrlByte M : 0|8@1+ (1,0) [0|255] "" Vector__XXX

CM_ BO_ 2147548630 "Basic Joystick Message 1";
CM_ SG_ 2147548630 Joystick1XAxisDetentPosStatus "Reports when the current joystick position is in the detent position for that axis of travel.";
CM_ SG_ 2147548630 Joystick1YAxisDetentPosStatus "Reports when the current joystick position is in the detent position for that axis of travel.";
CM_ SG_ 2147548630 Joystick1YAxisPos "The position of the joystick in the relative motion of travel from the neutral position.";
CM_ SG_ 2147548630 Joystick1YAxisNeutralPosStatus "Reports when the current joystick position is in the neutral position for that axis of travel.";
CM_ SG_ 2147548630 Joystick1XAxisPos "The position of the joystick in the relative motion of travel from the neutral position.";
CM_ SG_ 2147548630 Joystick1Button9PressedStatus "Reports when the joystick button has been pressed.";
CM_ SG_ 2147548630 Joystick1Button10PressedStatus "Reports when the joystick button has been pressed.";
CM_ SG_ 2147548630 Joystick1Button11PressedStatus "Reports when the joystick button has been pressed.";
CM_ SG_ 2147548630 Joystick1Button12PressedStatus "Reports when the joystick button has been pressed.";
CM_ SG_ 2147548630 Joystick1Button5PressedStatus "Reports when the joystick button has been pressed.";
CM_ SG_ 2147548630 Joystick1Button6PressedStatus "Reports when the joystick button has been pressed.";
CM_ SG_ 2147548630 Joystick1Button7PressedStatus "Reports when the joystick button has been pressed.";
CM_ SG_ 2147548630 Joystick1Button8PressedStatus "Reports when the joystick button has been pressed.";
CM_ SG_ 2147548630 Joystick1Button1PressedStatus "Reports when the joystick button has been pressed.";
CM_ SG_ 2147548630 Joystick1Button2PressedStatus "Reports when the joystick button has been pressed.";
CM_ SG_ 2147548630 Joystick1Button3PressedStatus "Reports when the joystick button has been pressed.";
CM_ SG_ 2147548630 Joystick1Button4PressedStatus "Reports when the joystick button has been pressed.";
CM_ SG_ 2147548630 Joystick1XAxisNeutralPosStatus "Reports when the current joystick position is in the neutral position for that axis of travel.";
CM_ BO_ 2147548922 "Brakes";
CM_ SG_ 2147548922 ParkingBrakeActuator "Signal which indicates the current state of the actuator(s) that control the parking brake (see also SPN 70).";
CM_ SG_ 2147548922 BrakeSecondPress "Gage pressure of air in the secondary, or service side, of the air brake system.";
CM_ SG_ 2147548922 BrakePrimaryPress "Gage pressure of air in the primary, or supply side, of the air brake system.";
CM_ BO_ 2147548926 "Auxiliary Water Pump Pressure";
CM_ SG_ 2147548926 AuxPumpPress "Gage pressure of auxiliary water pump driven as a PTO device.";
CM_ BO_ 2147548889 "Auxiliary Input/Output Status";
CM_ SG_ 2147548889 AuxI_OChannel2 "Auxiliary channel of data (16 bit) read by the ECU.";
CM_ SG_ 2147548889 AuxI_OChannel1 "Auxiliary channel of data (16 bit) read by the ECU.";
CM_ SG_ 2147548889 AuxI_O13 "Identifies the current status of auxiliary input/output functions that are configured uniquely per application.";
CM_ SG_ 2147548889 AuxI_O14 "Identifies the current status of auxiliary input/output functions that are configured uniquely per application.";
CM_ SG_ 2147548889 AuxI_O15 "Identifies the current status of auxiliary input/output functions that are configured uniquely per application.";
CM_ SG_ 2147548889 AuxI_O16 "Identifies the current status of auxiliary input/output functions that are configured uniquely per application.";
CM_ SG_ 2147548889 AuxI_O09 "Identifies the current status of auxiliary input/output functions that are configured uniquely per application.";
CM_ SG_ 2147548889 AuxI_O10 "Identifies the current status of auxiliary input/output functions that are configured uniquely per application.";
CM_ SG_ 2147548889 AuxI_O11 "Identifies the current status of auxiliary input/output functions that are configured uniquely per application.";
CM_ SG_ 2147548889 AuxI_O12 "Identifies the current status of auxiliary input/output functions that are configured uniquely per application.";
CM_ SG_ 2147548889 AuxI_O05 "Identifies the current status of auxiliary input/output functions that are configured uniquely per application.";
CM_ SG_ 2147548889 AuxI_O06 "Identifies the current status of auxiliary input/output functions that are configured uniquely per application.";
CM_ SG_ 2147548889 AuxI_O07 "Identifies the current status of auxiliary input/output functions that are configured uniquely per application.";
CM_ SG_ 2147548889 AuxI_O08 "Identifies the current status of auxiliary input/output functions that are configured uniquely per application.";
CM_ SG_ 2147548889 AuxI_O01 "Identifies the current status of auxiliary input/output functions that are configured uniquely per application.";
CM_ SG_ 2147548889 AuxI_O02 "Identifies the current status of auxiliary input/output functions that are configured uniquely per application.";
CM_ SG_ 2147548889 AuxI_O03 "Identifies the current status of auxiliary input/output functions that are configured uniquely per application.";
CM_ SG_ 2147548889 AuxI_O04 "Identifies the current status of auxiliary input/output functions that are configured uniquely per application.";
CM_ BO_ 2147539968 "Anti-theft Status";
CM_ SG_ 2147539968 AntitheftRandomNumber "A seven byte random numeric code provided by the component in response to an anti-theft request.";
CM_ SG_ 2147539968 AntitheftComponentStatusStates "Indicates whether or not the component can be started.";
CM_ SG_ 2147539968 AntthftEncryptnSdPrsntIndicator "Indicates the presence of the encryption seed random number.";
CM_ SG_ 2147539968 AntitheftPwdValidIndicator "Indicates the presence of a validated password.";
CM_ BO_ 2147540224 "Anti-theft Request";
CM_ SG_ 2147540224 AntitheftPasswordRepresentation "This parameter is the seven byte numeric code (i.";
CM_ SG_ 2147540224 AntitheftCmdStates "This parameter is used to identify the specific requests being sent to the component.";
CM_ BO_ 2147548593 "After Treatment Intake Gas 2-b";
CM_ BO_ 2147548839 "Alternator Temperature";
CM_ SG_ 2147548839 EngAltWinding3Temp "Temperature of the windings inside the alternator.";
CM_ SG_ 2147548839 EngAltWinding2Temp "Temperature of the windings inside the alternator.";
CM_ SG_ 2147548839 EngAltWinding1Temp "Temperature of the windings inside the alternator.";
CM_ SG_ 2147548839 EngAltBearing2Temp "Temperature of the bearing inside the alternator.";
CM_ SG_ 2147548839 EngAltBearing1Temp "Temperature of the bearing inside the alternator.";
CM_ BO_ 2147537152 "Air Suspension Control 6";
CM_ SG_ 2147537152 LevelPresetRearAxleRight "Set value for nominal level 'preset level' at the right side of the rear axle.";
CM_ SG_ 2147537152 LevelPresetRearAxleLeft "Set value for nominal level 'preset level' at the left side of the rear axle.";
CM_ SG_ 2147537152 LevelPresetFrontAxleRight "Set value for nominal level 'preset level' at the right side of the front axle.";
CM_ SG_ 2147537152 LevelPresetFrontAxleLeft "Set value for nominal level 'preset level' at the left side of the front axle.";
CM_ BO_ 2147548759 "Air Suspension Control 5";
CM_ SG_ 2147548759 ElctrncShckAbsrbrCtrlMdLft_TgAxl "Signal which indicates the current mode of operation of the electronic shock absorber control at the lift/tag axle.";
CM_ SG_ 2147548759 ElctrncShckAbsrbrCtrlMdRearAxle "Signal which indicates the current mode of operation of the electronic shock absorber control at the rear axle.";
CM_ SG_ 2147548759 ElctrncShckAbsrbrCtrlMdFrntAxle "Signal which indicates the current mode of operation of the electronic shock absorber control at the front axle.";
CM_ BO_ 2147548760 "Air Suspension Control 4";
CM_ BO_ 2147548761 "Air Suspension Control 3";
CM_ SG_ 2147548761 RelativeLevelRearAxleRight "Information of the height at the left side of the rear axle referred to normal level 1.";
CM_ SG_ 2147548761 RelativeLevelRearAxleLeft "Information of the height at the left side of the rear axle referred to normal level 1.";
CM_ SG_ 2147548761 RelativeLevelFrontAxleRight "Information of the height at the right side of the front axle referred to normal level 1.";
CM_ SG_ 2147548761 RelativeLevelFrontAxleLeft "Information of the height at the left side of the front axle referred to normal level 1.";
CM_ BO_ 2147537408 "Air Suspension Control 2";
CM_ SG_ 2147537408 KneelingCmdRearAxle "Command signal to activate the kneeling functionality at the rear axle of the vehicle.";
CM_ SG_ 2147537408 DamperStiffnessRqRearAxle "Demand value for the shock absorber control at the rear axle.";
CM_ SG_ 2147537408 DamperStiffnessRqFrontAxle "Demand value for the shock absorber control at the front axle.";
CM_ SG_ 2147537408 NominalLevelRqRearAxle "Command signal to activate a level of the rear axle programmed and/or memorised in the ECU.";
CM_ SG_ 2147537408 LiftAxle2PosCmd "Signal to command the position / load condition of lift / tag axle #2.";
CM_ SG_ 2147537408 LiftAxle1PosCmd "Signal to command the position/load condition of lift/tag axle #1.";
CM_ BO_ 2147548762 "Air Suspension Control 1";
CM_ SG_ 2147548762 SspensionCtrlRefusalInformation "Signal which indicates that the air suspension control cannot perform a request due to the operating conditions.";
CM_ SG_ 2147548762 SuspensionRemoteCtrl2 "Signal which indicates that the suspension system is controlled by remote control #2.";
CM_ SG_ 2147548762 SuspensionRemoteCtrl1 "Signal which indicates that the suspension system is controlled by remote control #1.";
CM_ SG_ 2147548762 RearAxleInBumperRange "Signal which indicates that the vehicle height at the rear axle (SPNs 1723 and 1724) is within the bumper range.";
CM_ SG_ 2147548762 FrontAxleInBumperRange "Signal which indicates that the vehicle height at the front axle (SPNs 1721 and 1722) is within the bumper range.";
CM_ SG_ 2147548762 DoorRelease "Signal which indicates that the doors may be opened.";
CM_ SG_ 2147548762 VehicleMotionInhibit "Signal which indicates whether vehicle motion is inhibited.";
CM_ SG_ 2147548762 SecurityDevice "The signal which indicates the status of the security device.";
CM_ SG_ 2147548762 AboveNominalLevelRearAxle "Signal which indicates whether the actual height of the rear axle is above the nominal (desired) level of the rear axle.";
CM_ SG_ 2147548762 AboveNominalLevelFrontAxle "Signal which indicates whether the actual height of the front axle is above the nominal (desired) level of the front axle.";
CM_ SG_ 2147548762 BelowNominalLevelRearAxle "Signal which indicates whether the actual height of the rear axle is below the nominal (desired) level for the rear axle.";
CM_ SG_ 2147548762 BelowNominalLevelFrontAxle "Signal which indicates whether the actual height of the front axle is below the nominal (desired) level for the front axle.";
CM_ SG_ 2147548762 NominalLevelRearAxle "Signal which indicates the nominal (desired) height of the rear axle to be controlled by the suspension system.";
CM_ SG_ 2147548762 NominalLevelFrontAxle "Signal which indicates the nominal (desired) height of the front axle to be controlled by the suspension system.";
CM_ SG_ 2147548762 LiftAxle2Pos "Signal which indicates the position / load condition of lift axle / tag axle #2.";
CM_ SG_ 2147548762 LiftAxle1Pos "Signal which indicates the position / load condition of lift axle / tag axle #1.";
CM_ BO_ 2147548885 "Alternator Speed";
CM_ SG_ 2147548885 AltSpeed "Actual rotation speed of the alternator.";
CM_ BO_ 2147548791 "Auxiliary Pressures";
CM_ SG_ 2147548791 AuxAbsPressReading "Identifies the current absolute pressure (relative to 0 pressure) that is configured uniquely per application.";
CM_ SG_ 2147548791 AuxGagePressReading1 "Identifies the current gage pressure (relative to atmosphere) that is configured uniquely per application.";
CM_ SG_ 2147548791 AuxVacuumPressReading "Identifies the current vacuum pressure (relative to atmosphere) that is configured uniquely per application.";
CM_ BO_ 2147548640 "Ambient Conditions 2";
CM_ SG_ 2147548640 SolarSensorMax "This is the maximum value which can be reported by the sensor for the solar intensity.";
CM_ SG_ 2147548640 SolarIntensityPercent "This is the solar radiation (power density) falling on the vehicle in percent of the maximum sensor value (SPN 2611).";
CM_ BO_ 2147548880 "Test results for non-continously monitored systems.";
CM_ SG_ 2147548880 TestLimitMinimum "The threshold which the test value must be above to pass the test.";
CM_ SG_ 2147548880 TestLimitMaximum "The threshold which the test value must be below to pass the test.";
CM_ SG_ 2147548880 TestValue "The test value collected during the test.";
CM_ SG_ 2147548880 TestType "Identifies the non-continously monitored component identifier that was tested.";
CM_ SG_ 2147548880 TestIdentifier "Designates the test to be run.";
CM_ BO_ 2680225732 "Proprietary B";
CM_ BO_ 2680225731 "Proprietary B";
CM_ BO_ 2680225730 "Proprietary B";
CM_ BO_ 2680225729 "Proprietary B";
CM_ BO_ 2680225728 "Proprietary B";
CM_ BO_ 2680225727 "Proprietary B";
CM_ BO_ 2680225726 "Proprietary B";
CM_ BO_ 2680225725 "Proprietary B";
CM_ BO_ 2680225724 "Proprietary B";
CM_ BO_ 2680225723 "Proprietary B";
CM_ BO_ 2680225722 "Proprietary B";
CM_ BO_ 2680225721 "Proprietary B";
CM_ BO_ 2680225720 "Proprietary B";
CM_ BO_ 2680225719 "Proprietary B";
CM_ BO_ 2680225718 "Proprietary B";
CM_ BO_ 2680225717 "Proprietary B";
CM_ BO_ 2680225716 "Proprietary B";
CM_ BO_ 2680225715 "Proprietary B";
CM_ BO_ 2680225714 "Proprietary B";
CM_ BO_ 2680225713 "Proprietary B";
CM_ BO_ 2680225712 "Proprietary B";
CM_ BO_ 2680225711 "Proprietary B";
CM_ BO_ 2680225710 "Proprietary B";
CM_ BO_ 2680225709 "Proprietary B";
CM_ BO_ 2680225708 "Proprietary B";
CM_ BO_ 2680225707 "Proprietary B";
CM_ BO_ 2680225706 "Proprietary B";
CM_ BO_ 2680225705 "Proprietary B";
CM_ BO_ 2680225704 "Proprietary B";
CM_ BO_ 2680225703 "Proprietary B";
CM_ BO_ 2680225702 "Proprietary B";
CM_ BO_ 2680225701 "Proprietary B";
CM_ BO_ 2680225700 "Proprietary B";
CM_ BO_ 2680225699 "Proprietary B";
CM_ BO_ 2680225698 "Proprietary B";
CM_ BO_ 2680225697 "Proprietary B";
CM_ BO_ 2680225696 "Proprietary B";
CM_ BO_ 2680225695 "Proprietary B";
CM_ BO_ 2680225694 "Proprietary B";
CM_ BO_ 2680225693 "Proprietary B";
CM_ BO_ 2680225692 "Proprietary B";
CM_ BO_ 2680225691 "Proprietary B";
CM_ BO_ 2680225690 "Proprietary B";
CM_ BO_ 2680225689 "Proprietary B";
CM_ BO_ 2680225688 "Proprietary B";
CM_ BO_ 2680225687 "Proprietary B";
CM_ BO_ 2680225686 "Proprietary B";
CM_ BO_ 2680225685 "Proprietary B";
CM_ BO_ 2680225684 "Proprietary B";
CM_ BO_ 2680225683 "Proprietary B";
CM_ BO_ 2680225682 "Proprietary B";
CM_ BO_ 2680225681 "Proprietary B";
CM_ BO_ 2680225680 "Proprietary B";
CM_ BO_ 2680225679 "Proprietary B";
CM_ BO_ 2680225678 "Proprietary B";
CM_ BO_ 2680225677 "Proprietary B";
CM_ BO_ 2680225676 "Proprietary B";
CM_ BO_ 2680225675 "Proprietary B";
CM_ BO_ 2680225674 "Proprietary B";
CM_ BO_ 2680225673 "Proprietary B";
CM_ BO_ 2680225672 "Proprietary B";
CM_ BO_ 2680225671 "Proprietary B";
CM_ BO_ 2680225670 "Proprietary B";
CM_ BO_ 2680225669 "Proprietary B";
CM_ BO_ 2680225668 "Proprietary B";
CM_ BO_ 2680225667 "Proprietary B";
CM_ BO_ 2680225666 "Proprietary B";
CM_ BO_ 2680225665 "Proprietary B";
CM_ BO_ 2680225664 "Proprietary B";
CM_ BO_ 2680225663 "Proprietary B";
CM_ BO_ 2147541760 "Command non-continously monitored test";
CM_ SG_ 2147541760 TestIdentifier "Designates the test to be run.";
CM_ BO_ 2147548879 "Pending DTCs";
CM_ SG_ 2147548879 SPN5 "SPN #5 (Conversion Version 1)";
CM_ SG_ 2147548879 SPN4 "SPN #1 (Conversion Version 4)";
CM_ SG_ 2147548879 SPN3 "SPN #3 (Conversion Version 1)";
CM_ SG_ 2147548879 SPN2 "SPN #1 (Conversion Version 2)";
CM_ SG_ 2147548879 FailureModeIdentifier5 "The FMI defines the type of failure detected in the subsystem identified by an SPN.";
CM_ SG_ 2147548879 FailureModeIdentifier4 "The FMI defines the type of failure detected in the subsystem identified by an SPN.";
CM_ SG_ 2147548879 FailureModeIdentifier3 "The FMI defines the type of failure detected in the subsystem identified by an SPN.";
CM_ SG_ 2147548879 FailureModeIdentifier2 "The FMI defines the type of failure detected in the subsystem identified by an SPN.";
CM_ SG_ 2147548879 OccurenceCount5 "The 7 bit occurence count field contains the number of times a fault has gone from active to previously active.";
CM_ SG_ 2147548879 OccurenceCount4 "The 7 bit occurence count field contains the number of times a fault has gone from active to previously active.";
CM_ SG_ 2147548879 OccurenceCount3 "The 7 bit occurence count field contains the number of times a fault has gone from active to previously active.";
CM_ SG_ 2147548879 OccurenceCount2 "The 7 bit occurence count field contains the number of times a fault has gone from active to previously active.";
CM_ SG_ 2147548879 OccurenceCount1 "The 7 bit occurence count field contains the number of times a fault has gone from active to previously active.";
CM_ SG_ 2147548879 FailureModeIdentifier1 "The FMI defines the type of failure detected in the subsystem identified by an SPN.";
CM_ SG_ 2147548879 SPN1 "SPN #1 (Conversion Version 1)";
CM_ SG_ 2147548879 MalfunctionIndicatorLampStatus "A lamp used to relay only emissions-related trouble code information.";
CM_ SG_ 2147548879 RedStopLampState "This lamp is uesed to relay trouble code information that is of a severe enought condition that it warrants stopping the vehicle.";
CM_ SG_ 2147548879 AmberWarningLampStatus "This lamp is used to relay trouble code information that is reporting a problem with the vehicle system but the vehicle need
not be immediately stopped.";
CM_ SG_ 2147548879 ProtectLampStatus "This lamp is used to relay trouble code informatio that is reporting a problem with a vehicle system that is most
probably not electronic subsystem related.";
CM_ BO_ 2147548878 "Diagnostic readiness";
CM_ SG_ 2147548878 OBDCompliance "Identifies the OBD compliance capabilityof the responding controller.";
CM_ SG_ 2147548878 PreviouslyActiveTroubleCodes "Identifies the number of previously active trouble codes that are present in a specific controller.";
CM_ SG_ 2147548878 ActiveTroubleCodes "Identifies the number of active trouble codes that are present in a specific controller.";
CM_ BO_ 2147548877 "Freeze frame parameters";
CM_ SG_ 2147548877 OccurenceCount1 "The 7 bit occurence count field contains the number of times a fault has gone from active to previously active.";
CM_ SG_ 2147548877 Boost "Gage pressure of air measured downstream on the compressor discharge side of the turbocharger.";
CM_ SG_ 2147548877 FailureModeIdentifier1 "The FMI defines the type of failure detected in the subsystem identified by an SPN.";
CM_ SG_ 2147548877 SPN1 "SPN #1 (Conversion Version 1)";
CM_ SG_ 2147548877 FreezeFrameLength "The freeze frame length shall be equal to the number of bytes in the required parameters plus the number of bytes in the
manufacturer specific parameters.";
CM_ SG_ 2147548877 EngineTorqueMode "State signal which indicates which engine torque mode is currently generating, limiting, or controlling the torque";
CM_ SG_ 2147548877 EngineSpeed "Actual engine speed which is calculated over a minimum crankshaft angle of 720 degrees divided by
the number of cylinders.";
CM_ BO_ 2147548876 "Diagnostic data clear/reset of previously active DTCs.";
CM_ BO_ 2147548599 "Expanded freeze frame.";
CM_ SG_ 2147548599 OccurenceCount1 "The 7 bit occurence count field contains the number of times a fault has gone from active to previously active.";
CM_ SG_ 2147548599 FailureModeIdentifier1 "The FMI defines the type of failure detected in the subsystem identified by an SPN.";
CM_ SG_ 2147548599 SPN1 "SPN #1 (Conversion Version 1)";
CM_ SG_ 2147548599 ExtendedFreezeFrameLength "The freeze frame length shall be equal to the number of bytes in the required parameters plus the number of bytes in the
manufacturer specific parameters.";
CM_ BO_ 2147548598 "SPN Support. This message is used to identify those SPNs supported by the product for freeze frames and data stream messages.";
CM_ SG_ 2147548598 SPNDataLength "The number of data bytes associated with the SPN in the Freeze Frame.";
CM_ SG_ 2147548598 SPNSupportType "This parameter defines whether the applicable parameter (that is the SPN) is supported in the freeze frame, the data stream or both the freeze frame and data stream.";
CM_ SG_ 2147548598 SPNSupported "This parameter defines the SPN(s) that is/are supported for the freeze frame and/or data stream information.";
CM_ BO_ 2147548597 "Previously active emission related faults.";
CM_ SG_ 2147548597 SPN5 "SPN #5 (Conversion Version 1)";
CM_ SG_ 2147548597 SPN4 "SPN #1 (Conversion Version 4)";
CM_ SG_ 2147548597 SPN3 "SPN #3 (Conversion Version 1)";
CM_ SG_ 2147548597 SPN2 "SPN #1 (Conversion Version 2)";
CM_ SG_ 2147548597 FailureModeIdentifier5 "The FMI defines the type of failure detected in the subsystem identified by an SPN.";
CM_ SG_ 2147548597 FailureModeIdentifier4 "The FMI defines the type of failure detected in the subsystem identified by an SPN.";
CM_ SG_ 2147548597 OccurenceCount1 "The 7 bit occurence count field contains the number of times a fault has gone from active to previously active.";
CM_ SG_ 2147548597 FailureModeIdentifier1 "The FMI defines the type of failure detected in the subsystem identified by an SPN.";
CM_ SG_ 2147548597 SPN1 "SPN #1 (Conversion Version 1)";
CM_ SG_ 2147548597 MalfunctionIndicatorLampStatus "A lamp used to relay only emissions-related trouble code information.";
CM_ SG_ 2147548597 RedStopLampState "This lamp is uesed to relay trouble code information that is of a severe enought condition that it warrants stopping the vehicle.";
CM_ SG_ 2147548597 AmberWarningLampStatus "This lamp is used to relay trouble code information that is reporting a problem with the vehicle system but the vehicle need
not be immediately stopped.";
CM_ SG_ 2147548597 ProtectLampStatus "This lamp is used to relay trouble code informatio that is reporting a problem with a vehicle system that is most
probably not electronic subsystem related.";
CM_ SG_ 2147548597 FailureModeIdentifier3 "The FMI defines the type of failure detected in the subsystem identified by an SPN.";
CM_ SG_ 2147548597 FailureModeIdentifier2 "The FMI defines the type of failure detected in the subsystem identified by an SPN.";
CM_ SG_ 2147548597 OccurenceCount5 "The 7 bit occurence count field contains the number of times a fault has gone from active to previously active.";
CM_ SG_ 2147548597 OccurenceCount4 "The 7 bit occurence count field contains the number of times a fault has gone from active to previously active.";
CM_ SG_ 2147548597 OccurenceCount3 "The 7 bit occurence count field contains the number of times a fault has gone from active to previously active.";
CM_ SG_ 2147548597 OccurenceCount2 "The 7 bit occurence count field contains the number of times a fault has gone from active to previously active.";
CM_ BO_ 2147533568 "Individual Clear/Reset of active and previously active DTC.";
CM_ SG_ 2147533568 SPN1 "SPN #1 (Conversion Version 1)";
CM_ SG_ 2147533056 TimeSinceDTCsCleared "Time accumulated since DTCs were cleared (via an external test equipment or possibly, a battery disconnect) (SPN=?).";
CM_ SG_ 2147533056 MinutesRunByEngineMILActivated "Accumulated count (in minutes) while the MIL is activated (on) (SPN=?).";
CM_ SG_ 2147533056 DistanceSinceDTCsCleared "Distance accumulated since DTCs were cleared (SPN=?).";
CM_ SG_ 2147533056 DistanceWhileMILisActivated "The kilometers accumulated while the MIL is activated (SPN 3060).";
CM_ BO_ 2147533312 "Monitor Performance Ratio";
CM_ SG_ 2147533312 ApplSysMonitorDenominator "The number of times a vehicle has been operated that constitutes a driving cycle where this Applicable System Monitor could be operated per regulatory requirements (SPN 3068).";
CM_ SG_ 2147533312 ApplSysMonitorNumerator "The number of times a vehicle has been operated such that all conditions necessary for the Applicable System Monitor to detect a malfunction have been encountered (SPN 3067).";
CM_ SG_ 2147533312 SPNofApplSysMonitor "Contain the SPN of the system monitor for which Monitor ratio is being reported (SPN 3066).";
CM_ SG_ 2147533312 OBDMonitoringCondEncountered "Displays the number of times that the vehicle has been operated in the specified OBD monitoring conditions (SPN 3049).";
CM_ SG_ 2147533312 IgnitionCycleCounter "A single counter that defines the number of ignition cycles (SPN 3048).";
CM_ BO_ 2147548875 "Previously active diagnostic trouble codes";
CM_ SG_ 2147548875 SPN5 "SPN #5 (Conversion Version 1)";
CM_ SG_ 2147548875 SPN4 "SPN #1 (Conversion Version 4)";
CM_ SG_ 2147548875 SPN3 "SPN #3 (Conversion Version 1)";
CM_ SG_ 2147548875 SPN2 "SPN #1 (Conversion Version 2)";
CM_ SG_ 2147548875 FailureModeIdentifier5 "The FMI defines the type of failure detected in the subsystem identified by an SPN.";
CM_ SG_ 2147548875 FailureModeIdentifier4 "The FMI defines the type of failure detected in the subsystem identified by an SPN.";
CM_ SG_ 2147548875 OccurenceCount1 "The 7 bit occurence count field contains the number of times a fault has gone from active to previously active.";
CM_ SG_ 2147548875 FailureModeIdentifier1 "The FMI defines the type of failure detected in the subsystem identified by an SPN.";
CM_ SG_ 2147548875 SPN1 "SPN #1 (Conversion Version 1)";
CM_ SG_ 2147548875 MalfunctionIndicatorLampStatus "A lamp used to relay only emissions-related trouble code information.";
CM_ SG_ 2147548875 RedStopLampState "This lamp is uesed to relay trouble code information that is of a severe enought condition that it warrants stopping the vehicle.";
CM_ SG_ 2147548875 AmberWarningLampStatus "This lamp is used to relay trouble code information that is reporting a problem with the vehicle system but the vehicle need
not be immediately stopped.";
CM_ SG_ 2147548875 ProtectLampStatus "This lamp is used to relay trouble code informatio that is reporting a problem with a vehicle system that is most
probably not electronic subsystem related.";
CM_ SG_ 2147548875 FailureModeIdentifier3 "The FMI defines the type of failure detected in the subsystem identified by an SPN.";
CM_ SG_ 2147548875 FailureModeIdentifier2 "The FMI defines the type of failure detected in the subsystem identified by an SPN.";
CM_ SG_ 2147548875 OccurenceCount5 "The 7 bit occurence count field contains the number of times a fault has gone from active to previously active.";
CM_ SG_ 2147548875 OccurenceCount4 "The 7 bit occurence count field contains the number of times a fault has gone from active to previously active.";
CM_ SG_ 2147548875 OccurenceCount3 "The 7 bit occurence count field contains the number of times a fault has gone from active to previously active.";
CM_ SG_ 2147548875 OccurenceCount2 "The 7 bit occurence count field contains the number of times a fault has gone from active to previously active.";
CM_ BO_ 2147537664 "Calibration Information";
CM_ BO_ 2147538432 "Boot Load Data";
CM_ BO_ 2147538688 "Binary Data Transfer";
CM_ SG_ 2147538688 NumberOfOccurance "Number of occurance of raw binary data";
CM_ BO_ 2147538944 "Memory Access Response";
CM_ SG_ 2147538944 ErrorIndicator "Error Indicator/EDC Parameter";
CM_ BO_ 2147539200 "Memory Access Request";
CM_ SG_ 2147539200 UserLevel "Key/User Level";
CM_ SG_ 2147539200 NumberRequested "Length/Number Requested";
CM_ BO_ 2147540736 "Stop start broadcast";
CM_ SG_ 2147540736 HoldSignal "Indicator to all nodes that the communication ports that have been acted upon by the 'Stop start broadcast'
PGN are remaining in the modified state.";
CM_ SG_ 2147540736 J1939Network3 "Identifies the action to be performed on the SAE J1939 Network #3.";
CM_ SG_ 2147540736 J1939Network2 "Identifies the action to be performed on the SAE J1939 Network #2.";
CM_ SG_ 2147540736 ISO9141 "Identifies the action to be performed on the ISO9141 communications port.";
CM_ SG_ 2147540736 SAE_J1850 "Identifies the action to be performed on the SAE J1850 communications port.";
CM_ SG_ 2147540736 ManufacturerSpecificPort "Identifies the action to be performed on 'Other, manufacturer specific port' communications port.";
CM_ SG_ 2147540736 CurrentDataLink "Identifies the action to be performed on the communications port that this parameter was received.";
CM_ SG_ 2147540736 SAE_J1587 "Identifies the action to be performed on the SAE J1587 communications port.";
CM_ SG_ 2147540736 SAE_J1922 "Identifies the action to be performed on the SAE J1922 communications port.";
CM_ SG_ 2147540736 J1939Network1 "Identifies the action to be performed on the SAE J1939 Network #1, Primary vehicle communications port.";
CM_ BO_ 2147548884 "Emissions-related active diagnostic trouble codes.";
CM_ SG_ 2147548884 SPN5 "SPN #5 (Conversion Version 1)";
CM_ SG_ 2147548884 SPN4 "SPN #1 (Conversion Version 4)";
CM_ SG_ 2147548884 SPN3 "SPN #3 (Conversion Version 1)";
CM_ SG_ 2147548884 SPN2 "SPN #1 (Conversion Version 2)";
CM_ SG_ 2147548884 FailureModeIdentifier5 "The FMI defines the type of failure detected in the subsystem identified by an SPN.";
CM_ SG_ 2147548884 FailureModeIdentifier4 "The FMI defines the type of failure detected in the subsystem identified by an SPN.";
CM_ SG_ 2147548884 FailureModeIdentifier3 "The FMI defines the type of failure detected in the subsystem identified by an SPN.";
CM_ SG_ 2147548884 OccurenceCount1 "The 7 bit occurence count field contains the number of times a fault has gone from active to previously active.";
CM_ SG_ 2147548884 FailureModeIdentifier1 "The FMI defines the type of failure detected in the subsystem identified by an SPN.";
CM_ SG_ 2147548884 SPN1 "SPN #1 (Conversion Version 1)";
CM_ SG_ 2147548884 MalfunctionIndicatorLampStatus "A lamp used to relay only emissions-related trouble code information.";
CM_ SG_ 2147548884 RedStopLampState "This lamp is uesed to relay trouble code information that is of a severe enought condition that it warrants stopping the vehicle.";
CM_ SG_ 2147548884 AmberWarningLampStatus "This lamp is used to relay trouble code information that is reporting a problem with the vehicle system but the vehicle need
not be immediately stopped.";
CM_ SG_ 2147548884 ProtectLampStatus "This lamp is used to relay trouble code informatio that is reporting a problem with a vehicle system that is most
probably not electronic subsystem related.";
CM_ SG_ 2147548884 FailureModeIdentifier2 "The FMI defines the type of failure detected in the subsystem identified by an SPN.";
CM_ SG_ 2147548884 OccurenceCount5 "The 7 bit occurence count field contains the number of times a fault has gone from active to previously active.";
CM_ SG_ 2147548884 OccurenceCount4 "The 7 bit occurence count field contains the number of times a fault has gone from active to previously active.";
CM_ SG_ 2147548884 OccurenceCount3 "The 7 bit occurence count field contains the number of times a fault has gone from active to previously active.";
CM_ SG_ 2147548884 OccurenceCount2 "The 7 bit occurence count field contains the number of times a fault has gone from active to previously active.";
CM_ BO_ 2147548883 "Diagnostic data clear/Reset for active DTCs";
CM_ BO_ 2147548882 "Non-continously monitored systems test identifiers support";
CM_ SG_ 2147548882 Test9to64 "Indicates the test identifiers that the controller supports.";
CM_ SG_ 2147548882 Test8 "Indicates the test identifiers that the controller supports.";
CM_ SG_ 2147548882 Test7 "Indicates the test identifiers that the controller supports.";
CM_ SG_ 2147548882 Test6 "Indicates the test identifiers that the controller supports.";
CM_ SG_ 2147548882 Test5 "Indicates the test identifiers that the controller supports.";
CM_ SG_ 2147548882 Test4 "Indicates the test identifiers that the controller supports.";
CM_ SG_ 2147548882 Test3 "Indicates the test identifiers that the controller supports.";
CM_ SG_ 2147548882 Test2 "Indicates the test identifiers that the controller supports.";
CM_ SG_ 2147548882 Test1 "Indicates the test identifiers that the controller supports.";
CM_ BO_ 2147548874 "Active diagnostic trouble codes";
CM_ SG_ 2147548874 SPN5 "SPN #5 (Conversion Version 1)";
CM_ SG_ 2147548874 SPN4 "SPN #1 (Conversion Version 4)";
CM_ SG_ 2147548874 SPN3 "SPN #3 (Conversion Version 1)";
CM_ SG_ 2147548874 SPN2 "SPN #1 (Conversion Version 2)";
CM_ SG_ 2147548874 FailureModeIdentifier5 "The FMI defines the type of failure detected in the subsystem identified by an SPN.";
CM_ SG_ 2147548874 FailureModeIdentifier4 "The FMI defines the type of failure detected in the subsystem identified by an SPN.";
CM_ SG_ 2147548874 FailureModeIdentifier3 "The FMI defines the type of failure detected in the subsystem identified by an SPN.";
CM_ SG_ 2147548874 FlashEngineRedStopLamp "This parameter provides the capability to flash the RSL (SPN 3039).";
CM_ SG_ 2147548874 FlashEngineProtectLamp "This parameter provides the capability to flash the engine protect lamp (SPN 3041).";
CM_ SG_ 2147548874 FlashEngineMalfuncIndicatorLamp "This parameter provides the capability to flash the MIL (SPN 3038).";
CM_ SG_ 2147548874 FlashEngineAmberWarningLamp "This parameter provides the capability to flash the AWL (SPN 3040). ";
CM_ SG_ 2147548874 MalfunctionIndicatorLampStatus "A lamp used to relay only emissions-related trouble code information.";
CM_ SG_ 2147548874 AmberWarningLampStatus "This lamp is used to relay trouble code information that is reporting a problem with the vehicle system but the vehicle need
not be immediately stopped.";
CM_ SG_ 2147548874 OccurenceCount1 "The 7 bit occurence count field contains the number of times a fault has gone from active to previously active.";
CM_ SG_ 2147548874 FailureModeIdentifier1 "The FMI defines the type of failure detected in the subsystem identified by an SPN.";
CM_ SG_ 2147548874 SPN1 "SPN #1 (Conversion Version 1)";
CM_ SG_ 2147548874 RedStopLampState "This lamp is uesed to relay trouble code information that is of a severe enought condition that it warrants stopping the vehicle.";
CM_ SG_ 2147548874 ProtectLampStatus "This lamp is used to relay trouble code informatio that is reporting a problem with a vehicle system that is most
probably not electronic subsystem related.";
CM_ SG_ 2147548874 FailureModeIdentifier2 "The FMI defines the type of failure detected in the subsystem identified by an SPN.";
CM_ SG_ 2147548874 OccurenceCount5 "The 7 bit occurence count field contains the number of times a fault has gone from active to previously active.";
CM_ SG_ 2147548874 OccurenceCount4 "The 7 bit occurence count field contains the number of times a fault has gone from active to previously active.";
CM_ SG_ 2147548874 OccurenceCount3 "The 7 bit occurence count field contains the number of times a fault has gone from active to previously active.";
CM_ SG_ 2147548874 OccurenceCount2 "The 7 bit occurence count field contains the number of times a fault has gone from active to previously active.";
CM_ BO_ 2147548663 "Utility Total AC Reactive Power";
CM_ SG_ 2147548663 UtlityOverallPowerFactorLagging "Lead/lag status for utility incomer average power factor.";
CM_ SG_ 2147548663 UtilityOverallPowerFactor "The average power factor of the utility incomer.";
CM_ SG_ 2147548663 UtilityTotalReactivePower "The total reactive power delivered by the utility incomer";
CM_ BO_ 2147548664 "Utility Total AC Power";
CM_ SG_ 2147548664 UtilityTotalApparentPower "The total apparent power delivered by the utility incomer.";
CM_ SG_ 2147548664 UtilityTotalRealPower "Total real power delivered by the utility incomer.";
CM_ BO_ 2147548653 "Utility Total AC Energy";
CM_ SG_ 2147548653 UtilityTotalKWHoursImport "The total kilowatt-hours that have been imported by the utility incomer.";
CM_ SG_ 2147548653 UtilityTotalKWHoursExport "The total kilowatt-hours that have been exported by the utility incomer.";
CM_ BO_ 2147548654 "Utility Phase C AC Reactive Power";
CM_ SG_ 2147548654 UtilityPhaseCPowerFactorLagging "Lead/lag status for utility incomer phase C power factor.";
CM_ SG_ 2147548654 UtilityPhaseCPowerFactor "The power factor of phases C of the utility incomer.";
CM_ SG_ 2147548654 UtilityPhaseCReactivePower "The reactive power delivered by phase C of the utility incomer";
CM_ BO_ 2147548655 "Utility Phase C AC Power";
CM_ SG_ 2147548655 UtilityPhaseCApparentPower "The apparent power delivered by phase C of the utility incomer.";
CM_ SG_ 2147548655 UtilityPhaseCRealPower "The real power delivered by phase C of the utility incomer.";
CM_ BO_ 2147548656 "Utility Phase C AC Basic Quantities";
CM_ SG_ 2147548656 UtilityPhaseCACRMSCurrent "RMS current measured at the utility incomer phase C.";
CM_ SG_ 2147548656 UtilityPhaseCACFrequency "AC frequency measured at the utility incomer phase C.";
CM_ SG_ 2147548656 UtltyPhsCLneNeutralACRMSVoltage "Line to Neutral RMS voltage measured at the utility incomer phase C.";
CM_ SG_ 2147548656 UtltyPhseCALineLineACRMSVoltage "Line to Line RMS voltage measured at the utility incomer phase CA.";
CM_ BO_ 2147548657 "Utility Phase B AC Reactive Power";
CM_ SG_ 2147548657 UtilityPhaseBPowerFactorLagging "Lead/lag status for utility incomer phase B power factor.";
CM_ SG_ 2147548657 UtilityPhaseBPowerFactor "The power factor of phases B of the utility incomer.";
CM_ SG_ 2147548657 UtilityPhaseBReactivePower "The reactive power delivered by phase B of the utility incomer";
CM_ BO_ 2147548658 "Utility Phase B AC Power";
CM_ SG_ 2147548658 UtilityPhaseBApparentPower "The apparent power delivered by phase B of the utility incomer.";
CM_ SG_ 2147548658 UtilityPhaseBRealPower "The real power delivered by phase B of the utility incomer.";
CM_ BO_ 2147548659 "Utility Phase B AC Basic Quantities";
CM_ SG_ 2147548659 UtilityPhaseBACRMSCurrent "RMS current measured at the utility incomer phase B.";
CM_ SG_ 2147548659 UtilityPhaseBACFrequency "AC frequency measured at the utility incomer phase B.";
CM_ SG_ 2147548659 UtltyPhsBLneNeutralACRMSVoltage "Line to Neutral RMS voltage measured at the utility incomer phase B.";
CM_ SG_ 2147548659 UtltyPhseBCLineLineACRMSVoltage "Line to Line RMS voltage measured at the utility incomer phase BC.";
CM_ BO_ 2147548660 "Utility Phase A  AC Reactive Power";
CM_ SG_ 2147548660 UtilityPhaseAPowerFactorLagging "Lead/lag status for utility incomer phase A power factor.";
CM_ SG_ 2147548660 UtilityPhaseAPowerFactor "The power factor of phase A of the utility incomer.";
CM_ SG_ 2147548660 UtilityPhaseAReactivePower "The reactive power delivered by phase A of the utility incomer";
CM_ BO_ 2147548661 "Utility Phase A  AC Power";
CM_ SG_ 2147548661 UtilityPhaseAApparentPower "The apparent power delivered by phase A of the utility incomer.";
CM_ SG_ 2147548661 UtilityPhaseARealPower "The real power delivered by phase A of the utility incomer.";
CM_ BO_ 2147548662 "Utility Phase A Basic AC Quantities";
CM_ SG_ 2147548662 UtilityPhaseAACRMSCurrent "RMS current measured at the utility incomer phase A.";
CM_ SG_ 2147548662 UtilityPhaseAACFrequency "AC frequency measured at the utility incomer phase A.";
CM_ SG_ 2147548662 UtltyPhsALneNeutralACRMSVoltage "Line to Neutral RMS voltage measured at the utility incomer phase A.";
CM_ SG_ 2147548662 UtltyPhseABLineLineACRMSVoltage "Line to Line RMS voltage measured at the utility incomer phase AB.";
CM_ BO_ 2147548665 "Utility Average Basic AC Quantities";
CM_ SG_ 2147548665 UtilityAverageACRMSCurrent "Average RMS current measured at the utility incomer.";
CM_ SG_ 2147548665 UtilityAverageACFrequency "Average AC frequency measured at the utility incomer.";
CM_ SG_ 2147548665 UtltyAvrgLneNeutralACRMSVoltage "The average Line to Neutral AC RMS voltage measured at the utility incomer .";
CM_ SG_ 2147548665 UtltyAvrageLineLineACRMSVoltage "Average Line to Line RMS voltage measured at the utility incomer .";
CM_ BO_ 2147548676 "Generator Total AC Reactive Power";
CM_ SG_ 2147548676 GnrtorOverallPowerFactorLagging "Lead/lag status for generator average power factor.";
CM_ SG_ 2147548676 GeneratorOverallPowerFactor "The average power factor of the generator.";
CM_ SG_ 2147548676 GeneratorTotalReactivePower "The total reactive power delivered by the generator";
CM_ BO_ 2147548677 "Generator Total AC Power";
CM_ SG_ 2147548677 GeneratorTotalApparentPower "The total apparent power delivered by the generator.";
CM_ SG_ 2147548677 GeneratorTotalRealPower "Total real power delivered by the generator.";
CM_ BO_ 2147548666 "Generator Total AC Energy";
CM_ SG_ 2147548666 GeneratorTotalKWHoursImport "The total kilowatt-hours that have been imported by the generator.";
CM_ SG_ 2147548666 GeneratorTotalKWHoursExport "The total kilowatt-hours that have been exported by the generator.";
CM_ BO_ 2147548667 "Generator Phase C AC Reactive Power";
CM_ SG_ 2147548667 GnratorPhaseCPowerFactorLagging "Lead/lag status for generator phase C power factor.";
CM_ SG_ 2147548667 GeneratorPhaseCPowerFactor "The power factor of phases C of the generator.";
CM_ SG_ 2147548667 GeneratorPhaseCReactivePower "The reactive power delivered by phase C of the generator";
CM_ BO_ 2147548668 "Generator Phase C AC Power";
CM_ SG_ 2147548668 GeneratorPhaseCApparentPower "The apparent power delivered by phase C of the generator.";
CM_ SG_ 2147548668 GeneratorPhaseCRealPower "The real power delivered by phase C of the generator.";
CM_ BO_ 2147548669 "Generator Phase C Basic AC Quantities";
CM_ SG_ 2147548669 GeneratorPhaseCACRMSCurrent "RMS current measured at the generator phase C output.";
CM_ SG_ 2147548669 GeneratorPhaseCACFrequency "AC frequency measured at the generator phase C output.";
CM_ SG_ 2147548669 GnrtrPhsCLneNeutralACRMSVoltage "Line to Neutral RMS voltage measured at the generator phase C output.";
CM_ SG_ 2147548669 GnrtrPhseCALineLineACRMSVoltage "Line to Line RMS voltage measured at the generator phase CA output.";
CM_ BO_ 2147548670 "Generator Phase B AC Reactive Power";
CM_ SG_ 2147548670 GnratorPhaseBPowerFactorLagging "Lead/lag status for generator phase B power factor.";
CM_ SG_ 2147548670 GeneratorPhaseBPowerFactor "The power factor of phases B of the generator.";
CM_ SG_ 2147548670 GeneratorPhaseBReactivePower "The reactive power delivered by phase B of the generator";
CM_ BO_ 2147548671 "Generator Phase B AC Power";
CM_ SG_ 2147548671 GeneratorPhaseBApparentPower "The apparent power delivered by phase B of the generator.";
CM_ SG_ 2147548671 GeneratorPhaseBRealPower "The real power delivered by phase B of the generator.";
CM_ BO_ 2147548672 "Generator Phase B Basic AC Quantities";
CM_ SG_ 2147548672 GeneratorPhaseBACRMSCurrent "RMS current measured at the generator phase B output.";
CM_ SG_ 2147548672 GeneratorPhaseBACFrequency "AC frequency measured at the generator phase B output.";
CM_ SG_ 2147548672 GnrtrPhsBLneNeutralACRMSVoltage "Line to Neutral RMS voltage measured at the generator phase B output.";
CM_ SG_ 2147548672 GnrtrPhseBCLineLineACRMSVoltage "Line to Line RMS voltage measured at the generator phase BC output.";
CM_ BO_ 2147548673 "Generator Phase A AC Reactive Power";
CM_ SG_ 2147548673 GnratorPhaseAPowerFactorLagging "Lead/lag status for generator phase A power factor.";
CM_ SG_ 2147548673 GeneratorPhaseAPowerFactor "The power factor of phase A of the generator.";
CM_ SG_ 2147548673 GeneratorPhaseAReactivePower "The reactive power delivered by phase A of the generator";
CM_ BO_ 2147548674 "Generator Phase A AC Power";
CM_ SG_ 2147548674 GeneratorPhaseAApparentPower "The apparent power delivered by phase A of the generator.";
CM_ SG_ 2147548674 GeneratorPhaseARealPower "The real power delivered by phase A of the generator.";
CM_ BO_ 2147548675 "Generator Phase A Basic AC Quantities";
CM_ SG_ 2147548675 GeneratorPhaseAACRMSCurrent "RMS current measured at the generator phase A output.";
CM_ SG_ 2147548675 GeneratorPhaseAACFrequency "AC frequency measured at the generator phase A output.";
CM_ SG_ 2147548675 GnrtrPhsALneNeutralACRMSVoltage "Line to Neutral RMS voltage measured at the generator phase A output.";
CM_ SG_ 2147548675 GnrtrPhseABLineLineACRMSVoltage "Line to Line RMS voltage measured at the generator phase AB output.";
CM_ BO_ 2147548678 "Generator Average Basic AC Quantities";
CM_ SG_ 2147548678 GeneratorAverageACRMSCurrent "Average RMS current measured at the generator output.";
CM_ SG_ 2147548678 GeneratorAverageACFrequency "Average AC frequency measured at the generator output.";
CM_ SG_ 2147548678 GnrtrAvrgLneNeutralACRMSVoltage "The average Line to Neutral AC RMS voltage measured at the Generator output.";
CM_ SG_ 2147548678 GnrtrAvrageLineLineACRMSVoltage "Average Line to Line RMS voltage measured at the generator output.";
CM_ BO_ 2147548647 "Bus #1/Utility Sync Check Status";
CM_ SG_ 2147548647 Bus1_UtilityACPhaseDifference "The phase difference between the Bus #1 voltage and Utility voltage.";
CM_ SG_ 2147548647 Bus1_UtilityInSync "Indicator of whether Bus #1 and Utility are properly synchronized for paralleling. This indicator will be based on parameters such as Voltage Match, Frequency Match, and Phase Match.";
CM_ SG_ 2147548647 Bus1_UtilityVoltageMatch "Indicator of whether voltage difference between Bus #1 and Utility is adequate for paralleling. This indicator will be based on the measured AC voltages qualified using parameters such as Voltage Tolerance.";
CM_ SG_ 2147548647 Bus1_UtilityFrequencyMatch "Indicator of whether frequency difference between Bus #1 and Utility is adequate for paralleling. This indicator will be based on the measured AC frequencies qualified using parameters such as Frequency Tolerance, Phase Tolerance, and Dwell Time.";
CM_ SG_ 2147548647 Bus1_UtilityPhaseMatch "Indicator of whether phase difference between Bus #1 and Utility is adequate for paralleling. This indicator will be based on the measured AC phase difference qualified using parameters such as Phase Tolerance and Dwell Time.";
CM_ SG_ 2147548647 Bus1_UtilityDeadBus "Indicator of whether Bus #1 is considered dead for closing to the utility. This indicator will be based on parameters such as Bus #1 Voltage and dead bus threshold values.";
CM_ BO_ 2147548649 "Bus #1 Phase C  Basic AC Quantities";
CM_ SG_ 2147548649 Bus1PhaseCACFrequency "AC frequency measured at bus #1 phase C.";
CM_ SG_ 2147548649 Bs1PhseCLineNeutralACRMSVoltage "Line to Neutral RMS voltage measured at bus #1 phase C.";
CM_ SG_ 2147548649 Bus1PhaseCALineLineACRMSVoltage "Line to Line RMS voltage measured at bus #1 phase CA.";
CM_ BO_ 2147548650 "Bus #1 Phase B  Basic AC Quantities";
CM_ SG_ 2147548650 Bus1PhaseBACFrequency "AC frequency measured at bus #1 phase B.";
CM_ SG_ 2147548650 Bs1PhseBLineNeutralACRMSVoltage "Line to Neutral RMS voltage measured at bus #1 phase B.";
CM_ SG_ 2147548650 Bus1PhaseBCLineLineACRMSVoltage "Line to Line RMS voltage measured at bus #1 phase BC.";
CM_ BO_ 2147548651 "Bus #1 Phase A  Basic AC Quantities";
CM_ SG_ 2147548651 Bus1PhaseAACFrequency "AC frequency measured at bus #1 phase A.";
CM_ SG_ 2147548651 Bs1PhseALineNeutralACRMSVoltage "Line to Neutral RMS voltage measured at bus #1 phase A.";
CM_ SG_ 2147548651 Bus1PhaseABLineLineACRMSVoltage "Line to Line RMS voltage measured at bus #1 phase AB.";
CM_ BO_ 2147548648 "Bus #1/Generator Sync Check Status";
CM_ SG_ 2147548648 Bus1_GeneratorACPhaseDifference "The phase difference between the Bus #1 voltage and Generator voltage.";
CM_ SG_ 2147548648 Bus1_GeneratorInSync "Indicator of whether Bus #1 and Generator are properly synchronized for paralleling. This indicator will be based on parameters such as Voltage Match, Frequency Match, and Phase Match.";
CM_ SG_ 2147548648 Bus1_GeneratorVoltageMatch "Indicator of whether voltage difference between Bus #1 and Generator is adequate for paralleling. This indicator will be based on the measured AC voltages qualified using parameters such as Voltage Tolerance.";
CM_ SG_ 2147548648 Bus1_GeneratorFrequencyMatch "Indicator of whether frequency difference between Bus #1 and Generator is adequate for paralleling. This indicator will be based on the measured AC frequencies qualified using parameters such as Frequency Tolerance, Phase Tolerance, and Dwell Time.";
CM_ SG_ 2147548648 Bus1_GeneratorPhaseMatch "Indicator of whether phase difference between Bus #1 and Generator is adequate for paralleling. This indicator will be based on the measured AC phase difference qualified using parameters such as Phase Tolerance and Dwell Time.";
CM_ SG_ 2147548648 Bus1_GeneratorDeadBus "Indicator of whether Bus #1 is considered dead for closing to the generator. This indicator will be based on parameters such as Bus #1 Voltage and dead bus threshold values.";
CM_ BO_ 2147548652 "Bus #1 Average Basic AC Quantities";
CM_ SG_ 2147548652 Bus1AverageACFrequency "Average AC frequency measured at bus #1.";
CM_ SG_ 2147548652 Bs1AvrgeLineNeutralACRMSVoltage "The average Line to Neutral AC RMS voltage measured at bus #1 .";
CM_ SG_ 2147548652 Bus1AverageLineLineACRMSVoltage "Average Line to Line RMS voltage measured at bus #1 .";
CM_ BO_ 2147548685 "Working Set Master";
CM_ BO_ 2147548622 "Working Set Member Message";
CM_ BO_ 2147548623 "Working Set Master Message";
CM_ BO_ 2147548888 "Commanded Address";
CM_ SG_ 2147548888 AddressAssignment "The source address that is to be assigned to the CA that has the NAME corresponding to the one conveyed in the first eight bytes of this Commanded Address message.";
CM_ BO_ 2147544576 "Address Claimed";
CM_ BO_ 2147535360 "Transfer";
CM_ SG_ 2147535360 ShrtNameOfActualReportingDevice "Short name of reporting device of the requested PGN via the Transfer PGN.";
CM_ SG_ 2147535360 LengthOfDataForTheReportedPGN "Length of data reported with the associated PGN via the Transfer PGN.";
CM_ SG_ 2147535360 PGNofRequstedInformation "PGN associated with this transfer message";
CM_ BO_ 2147543808 "Transport Protocol - Data Transfer";
CM_ BO_ 2147544064 "Transport Protocol - Connection Mgmt";
CM_ SG_ 2147544064 PGNumber "Requested PGN in the TP.CM_Conn_Abort message";
CM_ SG_ 2147544064 ConnectionAbortReason "Reason for connection abort message.";
CM_ SG_ 2147544064 NextPacketNumberToBeSent "Next Packet Number to be sent (TP.CM_CTS)";
CM_ SG_ 2147544064 NumberOfPacketsThatCanBeSent "Number of Packets that can be sent (TP.CM_CTS)";
CM_ SG_ 2147544064 MaximumNumberOfPackets "Maximum number of packets for RTS/CTS message.";
CM_ SG_ 2147544064 TotalNumberOfPackets "Total number of packets for BAM message.Total number of packets received for RTS/CTS message.Total number of packets for RTS/CTS message.";
CM_ SG_ 2147544064 TotalMessageSize "Total message size (in bytes) for BAM message.Total message size (in bytes) for RTS/CTS message.Total message size (in bytes) for RTS/CTS message.";
CM_ BO_ 2147535104 "Request 2";
CM_ SG_ 2147535104 UseTransferMode "Requester is to respond via the Transfer PGN";
CM_ SG_ 2147535104 ParameterGroupNumber "PGN which is requested by Request2 message";
CM_ BO_ 2147543552 "Request";
CM_ SG_ 2147543552 RqstedPGN "PGN which is requested by Request2 message";
CM_ BO_ 2680225791 "Proprietary B";
CM_ BO_ 2680225790 "Proprietary B";
CM_ BO_ 2680225789 "Proprietary B";
CM_ BO_ 2680225788 "Proprietary B";
CM_ BO_ 2680225787 "Proprietary B";
CM_ BO_ 2680225786 "Proprietary B";
CM_ BO_ 2680225785 "Proprietary B";
CM_ BO_ 2680225784 "Proprietary B";
CM_ BO_ 2680225783 "Proprietary B";
CM_ BO_ 2680225782 "Proprietary B";
CM_ BO_ 2680225781 "Proprietary B";
CM_ BO_ 2680225780 "Proprietary B";
CM_ BO_ 2680225779 "Proprietary B";
CM_ BO_ 2680225778 "Proprietary B";
CM_ BO_ 2680225777 "Proprietary B";
CM_ BO_ 2680225776 "Proprietary B";
CM_ BO_ 2680225775 "Proprietary B";
CM_ BO_ 2680225774 "Proprietary B";
CM_ BO_ 2680225773 "Proprietary B";
CM_ BO_ 2680225772 "Proprietary B";
CM_ BO_ 2680225771 "Proprietary B";
CM_ BO_ 2680225770 "Proprietary B";
CM_ BO_ 2680225769 "Proprietary B";
CM_ BO_ 2680225768 "Proprietary B";
CM_ BO_ 2680225767 "Proprietary B";
CM_ BO_ 2680225766 "Proprietary B";
CM_ BO_ 2680225765 "Proprietary B";
CM_ BO_ 2680225764 "Proprietary B";
CM_ BO_ 2680225763 "Proprietary B";
CM_ BO_ 2680225762 "Proprietary B";
CM_ BO_ 2680225761 "Proprietary B";
CM_ BO_ 2680225760 "Proprietary B";
CM_ BO_ 2680225759 "Proprietary B";
CM_ BO_ 2680225758 "Proprietary B";
CM_ BO_ 2680225757 "Proprietary B";
CM_ BO_ 2680225756 "Proprietary B";
CM_ BO_ 2680225755 "Proprietary B";
CM_ BO_ 2680225754 "Proprietary B";
CM_ BO_ 2680225753 "Proprietary B";
CM_ BO_ 2680225752 "Proprietary B";
CM_ BO_ 2680225751 "Proprietary B";
CM_ BO_ 2680225750 "Proprietary B";
CM_ BO_ 2680225749 "Proprietary B";
CM_ BO_ 2680225748 "Proprietary B";
CM_ BO_ 2680225747 "Proprietary B";
CM_ BO_ 2680225746 "Proprietary B";
CM_ BO_ 2680225745 "Proprietary B";
CM_ BO_ 2680225744 "Proprietary B";
CM_ BO_ 2680225743 "Proprietary B";
CM_ BO_ 2680225742 "Proprietary B";
CM_ BO_ 2680225741 "Proprietary B";
CM_ BO_ 2680225740 "Proprietary B";
CM_ BO_ 2680225739 "Proprietary B";
CM_ BO_ 2680225738 "Proprietary B";
CM_ BO_ 2680225737 "Proprietary B";
CM_ BO_ 2680225736 "Proprietary B";
CM_ BO_ 2680225735 "Proprietary B";
CM_ BO_ 2680225734 "Proprietary B";
CM_ BO_ 2680225733 "Proprietary B";
CM_ BO_ 2680225627 "Proprietary B";
CM_ BO_ 2680225626 "Proprietary B";
CM_ BO_ 2680225625 "Proprietary B";
CM_ BO_ 2680225624 "Proprietary B";
CM_ BO_ 2680225623 "Proprietary B";
CM_ BO_ 2680225622 "Proprietary B";
CM_ BO_ 2680225621 "Proprietary B";
CM_ BO_ 2680225620 "Proprietary B";
CM_ BO_ 2680225619 "Proprietary B";
CM_ BO_ 2680225618 "Proprietary B";
CM_ BO_ 2680225617 "Proprietary B";
CM_ BO_ 2680225616 "Proprietary B";
CM_ BO_ 2680225615 "Proprietary B";
CM_ BO_ 2680225614 "Proprietary B";
CM_ BO_ 2680225613 "Proprietary B";
CM_ BO_ 2680225612 "Proprietary B";
CM_ BO_ 2680225611 "Proprietary B";
CM_ BO_ 2680225610 "Proprietary B";
CM_ BO_ 2680225609 "Proprietary B";
CM_ BO_ 2680225608 "Proprietary B";
CM_ BO_ 2680225607 "Proprietary B";
CM_ BO_ 2680225606 "Proprietary B";
CM_ BO_ 2680225605 "Proprietary B";
CM_ BO_ 2680225604 "Proprietary B";
CM_ BO_ 2680225603 "Proprietary B";
CM_ BO_ 2680225602 "Proprietary B";
CM_ BO_ 2680225601 "Proprietary B";
CM_ BO_ 2680225600 "Proprietary B";
CM_ BO_ 2680225599 "Proprietary B";
CM_ BO_ 2680225598 "Proprietary B";
CM_ BO_ 2680225597 "Proprietary B";
CM_ BO_ 2680225596 "Proprietary B";
CM_ BO_ 2680225595 "Proprietary B";
CM_ BO_ 2680225594 "Proprietary B";
CM_ BO_ 2680225593 "Proprietary B";
CM_ BO_ 2680225592 "Proprietary B";
CM_ BO_ 2680225591 "Proprietary B";
CM_ BO_ 2680225590 "Proprietary B";
CM_ BO_ 2680225589 "Proprietary B";
CM_ BO_ 2680225588 "Proprietary B";
CM_ BO_ 2680225587 "Proprietary B";
CM_ BO_ 2680225586 "Proprietary B";
CM_ BO_ 2680225585 "Proprietary B";
CM_ BO_ 2680225584 "Proprietary B";
CM_ BO_ 2680225583 "Proprietary B";
CM_ BO_ 2680225582 "Proprietary B";
CM_ BO_ 2680225581 "Proprietary B";
CM_ BO_ 2680225580 "Proprietary B";
CM_ BO_ 2680225579 "Proprietary B";
CM_ BO_ 2680225578 "Proprietary B";
CM_ BO_ 2680225577 "Proprietary B";
CM_ BO_ 2680225576 "Proprietary B";
CM_ BO_ 2680225575 "Proprietary B";
CM_ BO_ 2680225574 "Proprietary B";
CM_ BO_ 2680225573 "Proprietary B";
CM_ BO_ 2680225572 "Proprietary B";
CM_ BO_ 2680225571 "Proprietary B";
CM_ BO_ 2680225570 "Proprietary B";
CM_ BO_ 2680225569 "Proprietary B";
CM_ BO_ 2680225568 "Proprietary B";
CM_ BO_ 2680225567 "Proprietary B";
CM_ BO_ 2680225566 "Proprietary B";
CM_ BO_ 2680225565 "Proprietary B";
CM_ BO_ 2680225564 "Proprietary B";
CM_ BO_ 2680225563 "Proprietary B";
CM_ BO_ 2680225562 "Proprietary B";
CM_ BO_ 2680225561 "Proprietary B";
CM_ BO_ 2680225560 "Proprietary B";
CM_ BO_ 2680225559 "Proprietary B";
CM_ BO_ 2680225558 "Proprietary B";
CM_ BO_ 2680225662 "Proprietary B";
CM_ BO_ 2680225661 "Proprietary B";
CM_ BO_ 2680225660 "Proprietary B";
CM_ BO_ 2680225659 "Proprietary B";
CM_ BO_ 2680225658 "Proprietary B";
CM_ BO_ 2680225657 "Proprietary B";
CM_ BO_ 2680225656 "Proprietary B";
CM_ BO_ 2680225655 "Proprietary B";
CM_ BO_ 2680225654 "Proprietary B";
CM_ BO_ 2680225653 "Proprietary B";
CM_ BO_ 2680225652 "Proprietary B";
CM_ BO_ 2680225651 "Proprietary B";
CM_ BO_ 2680225650 "Proprietary B";
CM_ BO_ 2680225649 "Proprietary B";
CM_ BO_ 2680225648 "Proprietary B";
CM_ BO_ 2680225647 "Proprietary B";
CM_ BO_ 2680225646 "Proprietary B";
CM_ BO_ 2680225645 "Proprietary B";
CM_ BO_ 2680225644 "Proprietary B";
CM_ BO_ 2680225643 "Proprietary B";
CM_ BO_ 2680225642 "Proprietary B";
CM_ BO_ 2680225641 "Proprietary B";
CM_ BO_ 2680225640 "Proprietary B";
CM_ BO_ 2680225639 "Proprietary B";
CM_ BO_ 2680225638 "Proprietary B";
CM_ BO_ 2680225637 "Proprietary B";
CM_ BO_ 2680225636 "Proprietary B";
CM_ BO_ 2680225635 "Proprietary B";
CM_ BO_ 2680225634 "Proprietary B";
CM_ BO_ 2680225633 "Proprietary B";
CM_ BO_ 2680225632 "Proprietary B";
CM_ BO_ 2680225631 "Proprietary B";
CM_ BO_ 2680225630 "Proprietary B";
CM_ BO_ 2680225629 "Proprietary B";
CM_ BO_ 2680225628 "Proprietary B";
CM_ BO_ 2147548917 "Ambient Conditions";
CM_ SG_ 2147548917 RoadSurfaceTemp "Indicated temperature of road surface over which vehicle is operating.";
CM_ SG_ 2147548917 EngAirInletTemp "Temperature of air entering vehicle air induction system.";
CM_ SG_ 2147548917 AmbientAirTemp "Temperature of air surrounding vehicle.";
CM_ SG_ 2147548917 CabInteriorTemp "Temperature of air inside the part of the vehicle that encloses the driver and vehicle operating controls.";
CM_ SG_ 2147548917 BarometricPress "Absolute air pressure of the atmosphere.";
CM_ BO_ 2147548894 "Air Start Pressure";
CM_ BO_ 2147548846 "Air Supply Pressure";
CM_ SG_ 2147548846 AirSuspensionSupplyPress "The pneumatic pressure in the circuit for the electronically controlled air suspension system.";
CM_ SG_ 2147548846 AuxEquipmentSupplyPress "The pneumatic pressure in the auxiliary circuit.";
CM_ SG_ 2147548846 ServiceBrakeAirPressCircuit2 "The pneumatic pressure in the service brake circuit or reservoir #2.";
CM_ SG_ 2147548846 ServiceBrakeAirPressCircuit1 "The pneumatic pressure in the service brake circuit or reservoir #1.";
CM_ SG_ 2147548846 ParkingAnd_OrTrailerAirPress "The pneumatic pressure in the circuit or reservoir for the parking brake and/or the trailer supply.";
CM_ SG_ 2147548846 PneumaticSupplyPress "The pneumatic pressure in the main reservoir, sometimes referred to as the wet tank.";
CM_ BO_ 2147548921 "Axle Information";
CM_ SG_ 2147548921 SteerAxleLubePress "The steering axle lubricant pressure.";
CM_ SG_ 2147548921 SteerAxleTemp "Temperature of lubricant in steering axle.";
CM_ SG_ 2147548921 DriveAxleLubePress "The drive axle lubricant pressure with location determined by Drive Axle Location (SPN 930).";
CM_ SG_ 2147548921 DriveAxleTemp "Temperature of axle lubricant in drive axle.";
CM_ SG_ 2147548921 DriveAxleLiftAirPress "Gage pressure of air in system that utilizes compressed air to provide force between axle and frame.";
CM_ SG_ 2147548921 DriveAxleLocation "To identify to which of several similar devices (such as tires or fuel tanks) the information applies.";
CM_ BO_ 2147548842 "Alternate Fuel 2";
CM_ SG_ 2147548842 EngTurboWastegateValvePos "The position of the turbocharger wastegate valve (not the electronic wastegate control valve).";
CM_ SG_ 2147548842 EngDsiredAbsIntakeManifoldPress "The desired absolute intake manifold pressure of the engine.";
CM_ SG_ 2147548842 EngGasFuelCorrectionFactor "A correction to a predefined gaseous fuel energy (expressed in energy per unit volume) represented as a percentage.";
CM_ BO_ 2147548753 "Adaptive Cruise Control, Operator Input";
CM_ SG_ 2147548753 RqedACCDistanceMode "The Requested Distance Control Mode to the ACC system from the operators interface.";
CM_ BO_ 2147548783 "Adaptive Cruise Control";
CM_ SG_ 2147548783 ACCDistanceAlertSignal "Signal to indicate to the operator that the ACC system is not able to maintain the distance to the target.";
CM_ SG_ 2147548783 ACCSystemShutoffWarning "Signal to warn the driver of system deactivation due to non-driver actions.";
CM_ SG_ 2147548783 ACCTargetDetected "Signal to indicate to the driver that the ACC system has detected a target.";
CM_ SG_ 2147548783 RoadCurvature "Estimated value of the current road curvature for use by the adaptive cruise control system.";
CM_ SG_ 2147548783 AdptveCruiseCtrlSetDistanceMode "Selected distance mode for adaptive cruise control.";
CM_ SG_ 2147548783 AdaptiveCruiseCtrlMode "This parameter is used to indicate the current state, or mode, of operation by the Adaptive Cruise Control (ACC) device.";
CM_ SG_ 2147548783 AdaptiveCruiseCtrlSetSpeed "Value of the desired (chosen) velocity of the adaptive cruise control system.";
CM_ SG_ 2147548783 DistanceToForwardVehicle "Distance to the preceding vehicle situated within 250 m in the same lane and moving in the same direction.";
CM_ SG_ 2147548783 SpeedOfForwardVehicle "Absolute velocity of the preceding vehicle situated within 250 m in the same lane and moving in the same direction.";
CM_ BO_ 2147548840 "Articulation Control";
CM_ SG_ 2147548840 ArticulationAngle "Angle of deflection of an articulated transit vehicle.";
CM_ BO_ 2147548812 "Auxiliary Analog Information";
CM_ SG_ 2147548812 AuxLevel "Level measured by a sensor.";
CM_ SG_ 2147548812 AuxPress2 "Pressure measured by auxiliary pressure sensor #2.";
CM_ SG_ 2147548812 AuxPress1 "Pressure measured by auxiliary pressure sensor #1.";
CM_ SG_ 2147548812 AuxTemp2 "Temperature measured by auxiliary temperature sensor #2.";
CM_ SG_ 2147548812 AuxTemp1 "Temperature measured by auxiliary temperature sensor #1.";
CM_ BO_ 2147548925 "Alternate Fuel 1";
CM_ SG_ 2147548925 EngBlowerBypassValvePos "Relative position of the blower bypass valve.";
CM_ SG_ 2147548925 EngGasSupplyPress "Gage pressure of gas supply to fuel metering device.";
CM_ BO_ 2680225557 "Proprietary B";
CM_ BO_ 2680225556 "Proprietary B";
CM_ BO_ 2680225555 "Proprietary B";
CM_ BO_ 2680225554 "Proprietary B";
CM_ BO_ 2680225553 "Proprietary B";
CM_ BO_ 2680225552 "Proprietary B";
CM_ BO_ 2680225551 "Proprietary B";
CM_ BO_ 2680225550 "Proprietary B";
CM_ BO_ 2680225549 "Proprietary B";
CM_ BO_ 2680225548 "Proprietary B";
CM_ BO_ 2680225547 "Proprietary B";
CM_ BO_ 2680225546 "Proprietary B";
CM_ BO_ 2680225545 "Proprietary B";
CM_ BO_ 2680225544 "Proprietary B";
CM_ BO_ 2680225543 "Proprietary B";
CM_ BO_ 2680225542 "Proprietary B";
CM_ BO_ 2680225541 "Proprietary B";
CM_ SG_ 2680225541 GradeExtSen "Filtered ExtGradeSensor";
CM_ BO_ 2680225540 "Proprietary B";
CM_ BO_ 2680225539 "Proprietary B";
CM_ BO_ 2680225538 "Proprietary B";
CM_ BO_ 2680225537 "Proprietary B";
CM_ BO_ 2680225536 "Proprietary B";
CM_ BO_ 2680221694 "Proprietary A";
CM_ BO_ 2147543040 "Acknowledgment Message";
CM_ SG_ 2147543040 PGNumber "PGN which is requested by Request2 message";
CM_ SG_ 2147543040 GroupFunctionValue "Indicates the acknowledgement response.Indicates the acknowledgement response.Negative Acknowledgement Group Function valuePositive Acknowledgement Group Function value";
BA_DEF_ SG_  "SigType" STRING ;
BA_DEF_ SG_  "SPN" INT 0 524287;
BA_DEF_ BO_  "J1939PGPrio" INT 0 7;
BA_DEF_ BO_  "SingleFrame" INT 0 1;
BA_DEF_ BO_  "J1939PGRepetitionCycle" INT 0 1000000;
BA_DEF_ BO_  "J1939PGRepetitionType" ENUM  "always","when active","on request";
BA_DEF_DEF_  "SigType" "";
BA_DEF_DEF_  "SPN" 0;
BA_DEF_DEF_  "J1939PGPrio" 6;
BA_DEF_DEF_  "SingleFrame" 1;
BA_DEF_DEF_  "J1939PGRepetitionCycle" 0;
BA_DEF_DEF_  "J1939PGRepetitionType" "on request";
BA_ "J1939PGPrio" BO_ 2147548630 3;
BA_ "J1939PGRepetitionCycle" BO_ 2147548630 100;
BA_ "J1939PGRepetitionType" BO_ 2147548630 0;
BA_ "J1939PGRepetitionCycle" BO_ 2147548922 1000;
BA_ "J1939PGRepetitionType" BO_ 2147548922 0;
BA_ "J1939PGRepetitionCycle" BO_ 2147548926 1000;
BA_ "J1939PGRepetitionType" BO_ 2147548926 0;
BA_ "J1939PGPrio" BO_ 2147539968 7;
BA_ "J1939PGPrio" BO_ 2147540224 7;
BA_ "J1939PGRepetitionCycle" BO_ 2147548593 500;
BA_ "J1939PGRepetitionType" BO_ 2147548593 0;
BA_ "J1939PGPrio" BO_ 2147548839 7;
BA_ "J1939PGRepetitionCycle" BO_ 2147548839 1000;
BA_ "J1939PGRepetitionType" BO_ 2147548839 0;
BA_ "J1939PGPrio" BO_ 2147537152 3;
BA_ "J1939PGRepetitionCycle" BO_ 2147537152 100;
BA_ "J1939PGRepetitionType" BO_ 2147537152 1;
BA_ "J1939PGPrio" BO_ 2147548759 3;
BA_ "J1939PGRepetitionCycle" BO_ 2147548759 100;
BA_ "J1939PGRepetitionType" BO_ 2147548759 0;
BA_ "J1939PGRepetitionCycle" BO_ 2147548760 100;
BA_ "J1939PGRepetitionType" BO_ 2147548760 0;
BA_ "J1939PGRepetitionCycle" BO_ 2147548761 100;
BA_ "J1939PGRepetitionType" BO_ 2147548761 0;
BA_ "J1939PGPrio" BO_ 2147537408 3;
BA_ "J1939PGRepetitionCycle" BO_ 2147537408 100;
BA_ "J1939PGRepetitionType" BO_ 2147537408 0;
BA_ "J1939PGPrio" BO_ 2147548762 3;
BA_ "J1939PGRepetitionCycle" BO_ 2147548762 100;
BA_ "J1939PGRepetitionType" BO_ 2147548762 0;
BA_ "J1939PGRepetitionCycle" BO_ 2147548885 1000;
BA_ "J1939PGRepetitionType" BO_ 2147548885 0;
BA_ "J1939PGPrio" BO_ 2147548791 7;
BA_ "J1939PGRepetitionCycle" BO_ 2147548640 1000;
BA_ "J1939PGRepetitionType" BO_ 2147548640 0;
BA_ "J1939PGRepetitionCycle" BO_ 2147548917 1000;
BA_ "J1939PGRepetitionType" BO_ 2147548917 0;
BA_ "J1939PGRepetitionCycle" BO_ 2147548846 1000;
BA_ "J1939PGRepetitionType" BO_ 2147548846 0;
BA_ "J1939PGRepetitionCycle" BO_ 2147548921 1000;
BA_ "J1939PGRepetitionType" BO_ 2147548921 0;
BA_ "J1939PGPrio" BO_ 2147548842 7;
BA_ "J1939PGRepetitionCycle" BO_ 2147548753 250;
BA_ "J1939PGRepetitionType" BO_ 2147548753 0;
BA_ "J1939PGPrio" BO_ 2147548783 4;
BA_ "J1939PGRepetitionCycle" BO_ 2147548783 100;
BA_ "J1939PGRepetitionType" BO_ 2147548783 0;
BA_ "J1939PGPrio" BO_ 2147548840 7;
BA_ "J1939PGPrio" BO_ 2147548812 7;
BA_ "J1939PGRepetitionCycle" BO_ 2147548925 500;
BA_ "J1939PGRepetitionType" BO_ 2147548925 0;
BA_ "SigType" SG_ 2147548630 Joystick1XAxisDetentPosStatus "DISCRETE";
BA_ "SPN" SG_ 2147548630 Joystick1XAxisDetentPosStatus 2680;
BA_ "SigType" SG_ 2147548630 Joystick1YAxisDetentPosStatus "DISCRETE";
BA_ "SPN" SG_ 2147548630 Joystick1YAxisDetentPosStatus 2681;
BA_ "SigType" SG_ 2147548630 Joystick1YAxisPos "RANGE";
BA_ "SPN" SG_ 2147548630 Joystick1YAxisPos 2661;
BA_ "SigType" SG_ 2147548630 Jystck1YAxsLvrFrwrdPstvPsStatus "DISCRETE";
BA_ "SPN" SG_ 2147548630 Jystck1YAxsLvrFrwrdPstvPsStatus 2666;
BA_ "SigType" SG_ 2147548630 Jystck1YAxsLvrBckNgtvePosStatus "DISCRETE";
BA_ "SPN" SG_ 2147548630 Jystck1YAxsLvrBckNgtvePosStatus 2671;
BA_ "SigType" SG_ 2147548630 Joystick1YAxisNeutralPosStatus "DISCRETE";
BA_ "SPN" SG_ 2147548630 Joystick1YAxisNeutralPosStatus 2676;
BA_ "SigType" SG_ 2147548630 Joystick1XAxisPos "RANGE";
BA_ "SPN" SG_ 2147548630 Joystick1XAxisPos 2660;
BA_ "SigType" SG_ 2147548630 Joystick1Button9PressedStatus "DISCRETE";
BA_ "SPN" SG_ 2147548630 Joystick1Button9PressedStatus 2693;
BA_ "SigType" SG_ 2147548630 Joystick1Button10PressedStatus "DISCRETE";
BA_ "SPN" SG_ 2147548630 Joystick1Button10PressedStatus 2694;
BA_ "SigType" SG_ 2147548630 Joystick1Button11PressedStatus "DISCRETE";
BA_ "SPN" SG_ 2147548630 Joystick1Button11PressedStatus 2695;
BA_ "SigType" SG_ 2147548630 Joystick1Button12PressedStatus "DISCRETE";
BA_ "SPN" SG_ 2147548630 Joystick1Button12PressedStatus 2696;
BA_ "SigType" SG_ 2147548630 Joystick1Button5PressedStatus "DISCRETE";
BA_ "SPN" SG_ 2147548630 Joystick1Button5PressedStatus 2689;
BA_ "SigType" SG_ 2147548630 Joystick1Button6PressedStatus "DISCRETE";
BA_ "SPN" SG_ 2147548630 Joystick1Button6PressedStatus 2690;
BA_ "SigType" SG_ 2147548630 Joystick1Button7PressedStatus "DISCRETE";
BA_ "SPN" SG_ 2147548630 Joystick1Button7PressedStatus 2691;
BA_ "SigType" SG_ 2147548630 Joystick1Button8PressedStatus "DISCRETE";
BA_ "SPN" SG_ 2147548630 Joystick1Button8PressedStatus 2692;
BA_ "SigType" SG_ 2147548630 Joystick1Button1PressedStatus "DISCRETE";
BA_ "SPN" SG_ 2147548630 Joystick1Button1PressedStatus 2685;
BA_ "SigType" SG_ 2147548630 Joystick1Button2PressedStatus "DISCRETE";
BA_ "SPN" SG_ 2147548630 Joystick1Button2PressedStatus 2686;
BA_ "SigType" SG_ 2147548630 Joystick1Button3PressedStatus "DISCRETE";
BA_ "SPN" SG_ 2147548630 Joystick1Button3PressedStatus 2687;
BA_ "SigType" SG_ 2147548630 Joystick1Button4PressedStatus "DISCRETE";
BA_ "SPN" SG_ 2147548630 Joystick1Button4PressedStatus 2688;
BA_ "SigType" SG_ 2147548630 Jystck1XAxsLvrRghtPstvPosStatus "DISCRETE";
BA_ "SPN" SG_ 2147548630 Jystck1XAxsLvrRghtPstvPosStatus 2665;
BA_ "SigType" SG_ 2147548630 Jystck1XAxsLvrLftNgtvePosStatus "DISCRETE";
BA_ "SPN" SG_ 2147548630 Jystck1XAxsLvrLftNgtvePosStatus 2670;
BA_ "SigType" SG_ 2147548630 Joystick1XAxisNeutralPosStatus "DISCRETE";
BA_ "SPN" SG_ 2147548630 Joystick1XAxisNeutralPosStatus 2675;
BA_ "SigType" SG_ 2147548922 ParkingBrakeActuator "DISCRETE";
BA_ "SPN" SG_ 2147548922 ParkingBrakeActuator 619;
BA_ "SigType" SG_ 2147548922 BrakeSecondPress "RANGE";
BA_ "SPN" SG_ 2147548922 BrakeSecondPress 118;
BA_ "SigType" SG_ 2147548922 BrakePrimaryPress "RANGE";
BA_ "SPN" SG_ 2147548922 BrakePrimaryPress 117;
BA_ "SigType" SG_ 2147548922 BrakeAppPress "RANGE";
BA_ "SPN" SG_ 2147548922 BrakeAppPress 116;
BA_ "SigType" SG_ 2147548926 AuxPumpPress "RANGE";
BA_ "SPN" SG_ 2147548926 AuxPumpPress 73;
BA_ "SigType" SG_ 2147548889 AuxI_OChannel2 "RANGE";
BA_ "SPN" SG_ 2147548889 AuxI_OChannel2 1084;
BA_ "SigType" SG_ 2147548889 AuxI_OChannel1 "RANGE";
BA_ "SPN" SG_ 2147548889 AuxI_OChannel1 1083;
BA_ "SigType" SG_ 2147548889 AuxI_O13 "DISCRETE";
BA_ "SPN" SG_ 2147548889 AuxI_O13 713;
BA_ "SigType" SG_ 2147548889 AuxI_O14 "DISCRETE";
BA_ "SPN" SG_ 2147548889 AuxI_O14 714;
BA_ "SigType" SG_ 2147548889 AuxI_O15 "DISCRETE";
BA_ "SPN" SG_ 2147548889 AuxI_O15 715;
BA_ "SigType" SG_ 2147548889 AuxI_O16 "DISCRETE";
BA_ "SPN" SG_ 2147548889 AuxI_O16 716;
BA_ "SigType" SG_ 2147548889 AuxI_O09 "DISCRETE";
BA_ "SPN" SG_ 2147548889 AuxI_O09 709;
BA_ "SigType" SG_ 2147548889 AuxI_O10 "DISCRETE";
BA_ "SPN" SG_ 2147548889 AuxI_O10 710;
BA_ "SigType" SG_ 2147548889 AuxI_O11 "DISCRETE";
BA_ "SPN" SG_ 2147548889 AuxI_O11 711;
BA_ "SigType" SG_ 2147548889 AuxI_O12 "DISCRETE";
BA_ "SPN" SG_ 2147548889 AuxI_O12 712;
BA_ "SigType" SG_ 2147548889 AuxI_O05 "DISCRETE";
BA_ "SPN" SG_ 2147548889 AuxI_O05 705;
BA_ "SigType" SG_ 2147548889 AuxI_O06 "DISCRETE";
BA_ "SPN" SG_ 2147548889 AuxI_O06 706;
BA_ "SigType" SG_ 2147548889 AuxI_O07 "DISCRETE";
BA_ "SPN" SG_ 2147548889 AuxI_O07 707;
BA_ "SigType" SG_ 2147548889 AuxI_O08 "DISCRETE";
BA_ "SPN" SG_ 2147548889 AuxI_O08 708;
BA_ "SigType" SG_ 2147548889 AuxI_O01 "DISCRETE";
BA_ "SPN" SG_ 2147548889 AuxI_O01 701;
BA_ "SigType" SG_ 2147548889 AuxI_O02 "DISCRETE";
BA_ "SPN" SG_ 2147548889 AuxI_O02 702;
BA_ "SigType" SG_ 2147548889 AuxI_O03 "DISCRETE";
BA_ "SPN" SG_ 2147548889 AuxI_O03 703;
BA_ "SigType" SG_ 2147548889 AuxI_O04 "DISCRETE";
BA_ "SPN" SG_ 2147548889 AuxI_O04 704;
BA_ "SigType" SG_ 2147539968 AntitheftRandomNumber "RANGE";
BA_ "SPN" SG_ 2147539968 AntitheftRandomNumber 1198;
BA_ "SigType" SG_ 2147539968 AntitheftComponentStatusStates "DISCRETE";
BA_ "SPN" SG_ 2147539968 AntitheftComponentStatusStates 1196;
BA_ "SigType" SG_ 2147539968 AntthftEncryptnSdPrsntIndicator "DISCRETE";
BA_ "SPN" SG_ 2147539968 AntthftEncryptnSdPrsntIndicator 1194;
BA_ "SigType" SG_ 2147539968 AntitheftModifyPwdStates "DISCRETE";
BA_ "SPN" SG_ 2147539968 AntitheftModifyPwdStates 1197;
BA_ "SigType" SG_ 2147539968 AntitheftPwdValidIndicator "DISCRETE";
BA_ "SPN" SG_ 2147539968 AntitheftPwdValidIndicator 1195;
BA_ "SigType" SG_ 2147540224 AntitheftPasswordRepresentation "RANGE";
BA_ "SPN" SG_ 2147540224 AntitheftPasswordRepresentation 1202;
BA_ "SigType" SG_ 2147540224 AntitheftCmdStates "DISCRETE";
BA_ "SPN" SG_ 2147540224 AntitheftCmdStates 1201;
BA_ "SigType" SG_ 2147540224 AntitheftDesiredExitModeStates "DISCRETE";
BA_ "SPN" SG_ 2147540224 AntitheftDesiredExitModeStates 1200;
BA_ "SigType" SG_ 2147540224 AntthftEncryptonIndicatorStates "DISCRETE";
BA_ "SPN" SG_ 2147540224 AntthftEncryptonIndicatorStates 1199;
BA_ "SigType" SG_ 2147548839 EngAltWinding3Temp "RANGE";
BA_ "SPN" SG_ 2147548839 EngAltWinding3Temp 1126;
BA_ "SigType" SG_ 2147548839 EngAltWinding2Temp "RANGE";
BA_ "SPN" SG_ 2147548839 EngAltWinding2Temp 1125;
BA_ "SigType" SG_ 2147548839 EngAltWinding1Temp "RANGE";
BA_ "SPN" SG_ 2147548839 EngAltWinding1Temp 1124;
BA_ "SigType" SG_ 2147548839 EngAltBearing2Temp "RANGE";
BA_ "SPN" SG_ 2147548839 EngAltBearing2Temp 1123;
BA_ "SigType" SG_ 2147548839 EngAltBearing1Temp "RANGE";
BA_ "SPN" SG_ 2147548839 EngAltBearing1Temp 1122;
BA_ "SigType" SG_ 2147537152 LevelPresetRearAxleRight "RANGE";
BA_ "SPN" SG_ 2147537152 LevelPresetRearAxleRight 1735;
BA_ "SigType" SG_ 2147537152 LevelPresetRearAxleLeft "RANGE";
BA_ "SPN" SG_ 2147537152 LevelPresetRearAxleLeft 1758;
BA_ "SigType" SG_ 2147537152 LevelPresetFrontAxleRight "RANGE";
BA_ "SPN" SG_ 2147537152 LevelPresetFrontAxleRight 1757;
BA_ "SigType" SG_ 2147537152 LevelPresetFrontAxleLeft "RANGE";
BA_ "SPN" SG_ 2147537152 LevelPresetFrontAxleLeft 1732;
BA_ "SigType" SG_ 2147548759 ElctrncShckAbsrbrCtrlMdLft_TgAxl "DISCRETE";
BA_ "SPN" SG_ 2147548759 ElctrncShckAbsrbrCtrlMdLft_TgAxl 1831;
BA_ "SigType" SG_ 2147548759 ElctrncShckAbsrbrCtrlMdRearAxle "DISCRETE";
BA_ "SPN" SG_ 2147548759 ElctrncShckAbsrbrCtrlMdRearAxle 1832;
BA_ "SigType" SG_ 2147548759 ElctrncShckAbsrbrCtrlMdFrntAxle "DISCRETE";
BA_ "SPN" SG_ 2147548759 ElctrncShckAbsrbrCtrlMdFrntAxle 1833;
BA_ "SigType" SG_ 2147548759 DamperStiffnessLift_TagAxle "RANGE";
BA_ "SPN" SG_ 2147548759 DamperStiffnessLift_TagAxle 1731;
BA_ "SigType" SG_ 2147548759 DamperStiffnessRearAxle "RANGE";
BA_ "SPN" SG_ 2147548759 DamperStiffnessRearAxle 1730;
BA_ "SigType" SG_ 2147548759 DamperStiffnessFrontAxle "RANGE";
BA_ "SPN" SG_ 2147548759 DamperStiffnessFrontAxle 1729;
BA_ "SigType" SG_ 2147548760 BellowPressRearAxleRight "RANGE";
BA_ "SPN" SG_ 2147548760 BellowPressRearAxleRight 1728;
BA_ "SigType" SG_ 2147548760 BellowPressRearAxleLeft "RANGE";
BA_ "SPN" SG_ 2147548760 BellowPressRearAxleLeft 1727;
BA_ "SigType" SG_ 2147548760 BellowPressFrontAxleRight "RANGE";
BA_ "SPN" SG_ 2147548760 BellowPressFrontAxleRight 1726;
BA_ "SigType" SG_ 2147548760 BellowPressFrontAxleLeft "RANGE";
BA_ "SPN" SG_ 2147548760 BellowPressFrontAxleLeft 1725;
BA_ "SigType" SG_ 2147548761 RelativeLevelRearAxleRight "RANGE";
BA_ "SPN" SG_ 2147548761 RelativeLevelRearAxleRight 1723;
BA_ "SigType" SG_ 2147548761 RelativeLevelRearAxleLeft "RANGE";
BA_ "SPN" SG_ 2147548761 RelativeLevelRearAxleLeft 1724;
BA_ "SigType" SG_ 2147548761 RelativeLevelFrontAxleRight "RANGE";
BA_ "SPN" SG_ 2147548761 RelativeLevelFrontAxleRight 1722;
BA_ "SigType" SG_ 2147548761 RelativeLevelFrontAxleLeft "RANGE";
BA_ "SPN" SG_ 2147548761 RelativeLevelFrontAxleLeft 1721;
BA_ "SigType" SG_ 2147537408 KneelingCmdRearAxle "DISCRETE";
BA_ "SPN" SG_ 2147537408 KneelingCmdRearAxle 1829;
BA_ "SigType" SG_ 2147537408 KneelingCmdFrontAxle "DISCRETE";
BA_ "SPN" SG_ 2147537408 KneelingCmdFrontAxle 1830;
BA_ "SigType" SG_ 2147537408 DamperStiffnessRqLift_TagAxle "RANGE";
BA_ "SPN" SG_ 2147537408 DamperStiffnessRqLift_TagAxle 1720;
BA_ "SigType" SG_ 2147537408 DamperStiffnessRqRearAxle "RANGE";
BA_ "SPN" SG_ 2147537408 DamperStiffnessRqRearAxle 1719;
BA_ "SigType" SG_ 2147537408 DamperStiffnessRqFrontAxle "RANGE";
BA_ "SPN" SG_ 2147537408 DamperStiffnessRqFrontAxle 1718;
BA_ "SigType" SG_ 2147537408 LevelCtrlModeRq "DISCRETE";
BA_ "SPN" SG_ 2147537408 LevelCtrlModeRq 1753;
BA_ "SigType" SG_ 2147537408 NominalLevelRqRearAxle "DISCRETE";
BA_ "SPN" SG_ 2147537408 NominalLevelRqRearAxle 1750;
BA_ "SigType" SG_ 2147537408 NominalLevelRqFrontAxle "DISCRETE";
BA_ "SPN" SG_ 2147537408 NominalLevelRqFrontAxle 1751;
BA_ "SigType" SG_ 2147537408 KneelingCtrlModeRq "DISCRETE";
BA_ "SPN" SG_ 2147537408 KneelingCtrlModeRq 1747;
BA_ "SigType" SG_ 2147537408 KneelingRqRightSide "DISCRETE";
BA_ "SPN" SG_ 2147537408 KneelingRqRightSide 1748;
BA_ "SigType" SG_ 2147537408 KneelingRqLeftSide "DISCRETE";
BA_ "SPN" SG_ 2147537408 KneelingRqLeftSide 1749;
BA_ "SigType" SG_ 2147537408 AutomaticTractionHelp "DISCRETE";
BA_ "SPN" SG_ 2147537408 AutomaticTractionHelp 2984;
BA_ "SigType" SG_ 2147537408 LiftAxle2PosCmd "DISCRETE";
BA_ "SPN" SG_ 2147537408 LiftAxle2PosCmd 1828;
BA_ "SigType" SG_ 2147537408 LiftAxle1PosCmd "DISCRETE";
BA_ "SPN" SG_ 2147537408 LiftAxle1PosCmd 1752;
BA_ "SigType" SG_ 2147548762 SspensionCtrlRefusalInformation "DISCRETE";
BA_ "SPN" SG_ 2147548762 SspensionCtrlRefusalInformation 1827;
BA_ "SigType" SG_ 2147548762 SuspensionRemoteCtrl2 "DISCRETE";
BA_ "SPN" SG_ 2147548762 SuspensionRemoteCtrl2 1825;
BA_ "SigType" SG_ 2147548762 SuspensionRemoteCtrl1 "DISCRETE";
BA_ "SPN" SG_ 2147548762 SuspensionRemoteCtrl1 1826;
BA_ "SigType" SG_ 2147548762 RearAxleInBumperRange "DISCRETE";
BA_ "SPN" SG_ 2147548762 RearAxleInBumperRange 1823;
BA_ "SigType" SG_ 2147548762 FrontAxleInBumperRange "DISCRETE";
BA_ "SPN" SG_ 2147548762 FrontAxleInBumperRange 1824;
BA_ "SigType" SG_ 2147548762 DoorRelease "DISCRETE";
BA_ "SPN" SG_ 2147548762 DoorRelease 1744;
BA_ "SigType" SG_ 2147548762 VehicleMotionInhibit "DISCRETE";
BA_ "SPN" SG_ 2147548762 VehicleMotionInhibit 1745;
BA_ "SigType" SG_ 2147548762 SecurityDevice "DISCRETE";
BA_ "SPN" SG_ 2147548762 SecurityDevice 1746;
BA_ "SigType" SG_ 2147548762 LevelCtrlMode "DISCRETE";
BA_ "SPN" SG_ 2147548762 LevelCtrlMode 1741;
BA_ "SigType" SG_ 2147548762 KneelingInformation "DISCRETE";
BA_ "SPN" SG_ 2147548762 KneelingInformation 1742;
BA_ "SigType" SG_ 2147548762 LiftingCtrlModeRearAxle "DISCRETE";
BA_ "SPN" SG_ 2147548762 LiftingCtrlModeRearAxle 1756;
BA_ "SigType" SG_ 2147548762 LiftingCtrlModeFrontAxle "DISCRETE";
BA_ "SPN" SG_ 2147548762 LiftingCtrlModeFrontAxle 1739;
BA_ "SigType" SG_ 2147548762 LoweringCtrlModeRearAxle "DISCRETE";
BA_ "SPN" SG_ 2147548762 LoweringCtrlModeRearAxle 1755;
BA_ "SigType" SG_ 2147548762 LoweringCtrlModeFrontAxle "DISCRETE";
BA_ "SPN" SG_ 2147548762 LoweringCtrlModeFrontAxle 1740;
BA_ "SigType" SG_ 2147548762 AboveNominalLevelRearAxle "DISCRETE";
BA_ "SPN" SG_ 2147548762 AboveNominalLevelRearAxle 1736;
BA_ "SigType" SG_ 2147548762 AboveNominalLevelFrontAxle "DISCRETE";
BA_ "SPN" SG_ 2147548762 AboveNominalLevelFrontAxle 1737;
BA_ "SigType" SG_ 2147548762 BelowNominalLevelRearAxle "DISCRETE";
BA_ "SPN" SG_ 2147548762 BelowNominalLevelRearAxle 1754;
BA_ "SigType" SG_ 2147548762 BelowNominalLevelFrontAxle "DISCRETE";
BA_ "SPN" SG_ 2147548762 BelowNominalLevelFrontAxle 1738;
BA_ "SigType" SG_ 2147548762 NominalLevelRearAxle "DISCRETE";
BA_ "SPN" SG_ 2147548762 NominalLevelRearAxle 1733;
BA_ "SigType" SG_ 2147548762 NominalLevelFrontAxle "DISCRETE";
BA_ "SPN" SG_ 2147548762 NominalLevelFrontAxle 1734;
BA_ "SigType" SG_ 2147548762 LiftAxle2Pos "DISCRETE";
BA_ "SPN" SG_ 2147548762 LiftAxle2Pos 1822;
BA_ "SigType" SG_ 2147548762 LiftAxle1Pos "DISCRETE";
BA_ "SPN" SG_ 2147548762 LiftAxle1Pos 1743;
BA_ "SigType" SG_ 2147548885 AltSpeed "RANGE";
BA_ "SPN" SG_ 2147548885 AltSpeed 589;
BA_ "SigType" SG_ 2147548791 AuxAbsPressReading "RANGE";
BA_ "SPN" SG_ 2147548791 AuxAbsPressReading 138;
BA_ "SigType" SG_ 2147548791 AuxGagePressReading1 "RANGE";
BA_ "SPN" SG_ 2147548791 AuxGagePressReading1 137;
BA_ "SigType" SG_ 2147548791 AuxVacuumPressReading "RANGE";
BA_ "SPN" SG_ 2147548791 AuxVacuumPressReading 136;
BA_ "SigType" SG_ 2147548640 SolarSensorMax "RANGE";
BA_ "SPN" SG_ 2147548640 SolarSensorMax 2611;
BA_ "SigType" SG_ 2147548640 SolarIntensityPercent "RANGE";
BA_ "SPN" SG_ 2147548640 SolarIntensityPercent 2610;
BA_ "SigType" SG_ 2147548880 TestLimitMinimum "RANGE";
BA_ "SigType" SG_ 2147548880 TestLimitMaximum "RANGE";
BA_ "SigType" SG_ 2147548880 TestValue "RANGE";
BA_ "SigType" SG_ 2147548880 TestType "RANGE";
BA_ "SigType" SG_ 2147548880 TestIdentifier "RANGE";
BA_ "SigType" SG_ 2147541760 TestIdentifier "RANGE";
BA_ "SigType" SG_ 2147548879 OccurenceCount5 "RANGE";
BA_ "SigType" SG_ 2147548879 OccurenceCount4 "RANGE";
BA_ "SigType" SG_ 2147548879 OccurenceCount3 "RANGE";
BA_ "SigType" SG_ 2147548879 OccurenceCount2 "RANGE";
BA_ "SigType" SG_ 2147548879 OccurenceCount1 "RANGE";
BA_ "SigType" SG_ 2147548879 MalfunctionIndicatorLampStatus "DISCRETE";
BA_ "SigType" SG_ 2147548879 RedStopLampState "DISCRETE";
BA_ "SigType" SG_ 2147548879 AmberWarningLampStatus "DISCRETE";
BA_ "SigType" SG_ 2147548879 ProtectLampStatus "DISCRETE";
BA_ "SigType" SG_ 2147548878 OBDCompliance "RANGE";
BA_ "SigType" SG_ 2147548878 PreviouslyActiveTroubleCodes "RANGE";
BA_ "SigType" SG_ 2147548878 ActiveTroubleCodes "RANGE";
BA_ "SigType" SG_ 2147548877 OccurenceCount1 "RANGE";
BA_ "SigType" SG_ 2147548877 VehicleSpeed "RANGE";
BA_ "SigType" SG_ 2147548877 EngineLoad "RANGE";
BA_ "SigType" SG_ 2147548877 Boost "RANGE";
BA_ "SigType" SG_ 2147548877 EngineTorqueMode "DISCRETE";
BA_ "SigType" SG_ 2147548877 EngineSpeed "RANGE";
BA_ "SigType" SG_ 2147548877 EngineCoolantTemperature "RANGE";
BA_ "SPN" SG_ 2147548877 EngineCoolantTemperature 110;
BA_ "SigType" SG_ 2147548599 OccurenceCount1 "RANGE";
BA_ "SPN" SG_ 2147548599 ExtendedFreezeFrameLength 3149;
BA_ "SigType" SG_ 2147548598 SPNDataLength "RANGE";
BA_ "SPN" SG_ 2147548598 SPNDataLength 3148;
BA_ "SPN" SG_ 2147548598 SPNSupportType 3147;
BA_ "SPN" SG_ 2147548598 SPNSupported 3146;
BA_ "SigType" SG_ 2147548597 OccurenceCount1 "RANGE";
BA_ "SigType" SG_ 2147548597 MalfunctionIndicatorLampStatus "DISCRETE";
BA_ "SigType" SG_ 2147548597 RedStopLampState "DISCRETE";
BA_ "SigType" SG_ 2147548597 AmberWarningLampStatus "DISCRETE";
BA_ "SigType" SG_ 2147548597 ProtectLampStatus "DISCRETE";
BA_ "SigType" SG_ 2147548597 OccurenceCount5 "RANGE";
BA_ "SigType" SG_ 2147548597 OccurenceCount4 "RANGE";
BA_ "SigType" SG_ 2147548597 OccurenceCount3 "RANGE";
BA_ "SigType" SG_ 2147548597 OccurenceCount2 "RANGE";
BA_ "SPN" SG_ 2147533568 DTCClearControlByte 3034;
BA_ "SPN" SG_ 2147533568 CtrlByteSpecificIndicator 3035;
BA_ "SigType" SG_ 2147533056 TimeSinceDTCsCleared "RANGE";
BA_ "SPN" SG_ 2147533056 TimeSinceDTCsCleared 3145;
BA_ "SigType" SG_ 2147533056 MinutesRunByEngineMILActivated "RANGE";
BA_ "SPN" SG_ 2147533056 MinutesRunByEngineMILActivated 3144;
BA_ "SigType" SG_ 2147533056 DistanceSinceDTCsCleared "RANGE";
BA_ "SPN" SG_ 2147533056 DistanceSinceDTCsCleared 3143;
BA_ "SigType" SG_ 2147533056 DistanceWhileMILisActivated "RANGE";
BA_ "SPN" SG_ 2147533056 DistanceWhileMILisActivated 3069;
BA_ "SigType" SG_ 2147533312 ApplSysMonitorDenominator "RANGE";
BA_ "SPN" SG_ 2147533312 ApplSysMonitorDenominator 3068;
BA_ "SigType" SG_ 2147533312 ApplSysMonitorNumerator "RANGE";
BA_ "SPN" SG_ 2147533312 ApplSysMonitorNumerator 3067;
BA_ "SigType" SG_ 2147533312 SPNofApplSysMonitor "RANGE";
BA_ "SPN" SG_ 2147533312 SPNofApplSysMonitor 3066;
BA_ "SigType" SG_ 2147533312 OBDMonitoringCondEncountered "RANGE";
BA_ "SPN" SG_ 2147533312 OBDMonitoringCondEncountered 3049;
BA_ "SigType" SG_ 2147533312 IgnitionCycleCounter "RANGE";
BA_ "SPN" SG_ 2147533312 IgnitionCycleCounter 3048;
BA_ "SigType" SG_ 2147548875 OccurenceCount1 "RANGE";
BA_ "SigType" SG_ 2147548875 MalfunctionIndicatorLampStatus "DISCRETE";
BA_ "SigType" SG_ 2147548875 RedStopLampState "DISCRETE";
BA_ "SigType" SG_ 2147548875 AmberWarningLampStatus "DISCRETE";
BA_ "SigType" SG_ 2147548875 ProtectLampStatus "DISCRETE";
BA_ "SigType" SG_ 2147548875 OccurenceCount5 "RANGE";
BA_ "SigType" SG_ 2147548875 OccurenceCount4 "RANGE";
BA_ "SigType" SG_ 2147548875 OccurenceCount3 "RANGE";
BA_ "SigType" SG_ 2147548875 OccurenceCount2 "RANGE";
BA_ "SPN" SG_ 2147537664 CalibrationID4 1635;
BA_ "SPN" SG_ 2147537664 CalibrationID3 1635;
BA_ "SPN" SG_ 2147537664 CalibrationID2 1635;
BA_ "SPN" SG_ 2147537664 CalibrationID1 1635;
BA_ "SigType" SG_ 2147537664 CalibrationVerificationNumber "RANGE";
BA_ "SPN" SG_ 2147537664 CalibrationVerificationNumber 1634;
BA_ "SigType" SG_ 2147540736 HoldSignal "DISCRETE";
BA_ "SigType" SG_ 2147540736 J1939Network3 "DISCRETE";
BA_ "SigType" SG_ 2147540736 J1939Network2 "DISCRETE";
BA_ "SigType" SG_ 2147540736 ISO9141 "DISCRETE";
BA_ "SigType" SG_ 2147540736 SAE_J1850 "DISCRETE";
BA_ "SigType" SG_ 2147540736 ManufacturerSpecificPort "DISCRETE";
BA_ "SigType" SG_ 2147540736 CurrentDataLink "DISCRETE";
BA_ "SigType" SG_ 2147540736 SAE_J1587 "DISCRETE";
BA_ "SigType" SG_ 2147540736 SAE_J1922 "DISCRETE";
BA_ "SigType" SG_ 2147540736 J1939Network1 "DISCRETE";
BA_ "SigType" SG_ 2147548884 OccurenceCount1 "RANGE";
BA_ "SigType" SG_ 2147548884 MalfunctionIndicatorLampStatus "DISCRETE";
BA_ "SigType" SG_ 2147548884 RedStopLampState "DISCRETE";
BA_ "SigType" SG_ 2147548884 AmberWarningLampStatus "DISCRETE";
BA_ "SigType" SG_ 2147548884 ProtectLampStatus "DISCRETE";
BA_ "SigType" SG_ 2147548884 OccurenceCount5 "RANGE";
BA_ "SigType" SG_ 2147548884 OccurenceCount4 "RANGE";
BA_ "SigType" SG_ 2147548884 OccurenceCount3 "RANGE";
BA_ "SigType" SG_ 2147548884 OccurenceCount2 "RANGE";
BA_ "SigType" SG_ 2147548874 FlashEngineMalfuncIndicatorLamp "DISCRETE";
BA_ "SigType" SG_ 2147548874 MalfunctionIndicatorLampStatus "DISCRETE";
BA_ "SigType" SG_ 2147548874 AmberWarningLampStatus "DISCRETE";
BA_ "SigType" SG_ 2147548874 OccurenceCount1 "RANGE";
BA_ "SigType" SG_ 2147548874 RedStopLampState "DISCRETE";
BA_ "SigType" SG_ 2147548874 ProtectLampStatus "DISCRETE";
BA_ "SigType" SG_ 2147548874 OccurenceCount5 "RANGE";
BA_ "SigType" SG_ 2147548874 OccurenceCount4 "RANGE";
BA_ "SigType" SG_ 2147548874 OccurenceCount3 "RANGE";
BA_ "SigType" SG_ 2147548874 OccurenceCount2 "RANGE";
BA_ "SigType" SG_ 2147548663 UtlityOverallPowerFactorLagging "DISCRETE";
BA_ "SPN" SG_ 2147548663 UtlityOverallPowerFactorLagging 2522;
BA_ "SigType" SG_ 2147548663 UtilityOverallPowerFactor "RANGE";
BA_ "SPN" SG_ 2147548663 UtilityOverallPowerFactor 2498;
BA_ "SigType" SG_ 2147548663 UtilityTotalReactivePower "RANGE";
BA_ "SPN" SG_ 2147548663 UtilityTotalReactivePower 2490;
BA_ "SigType" SG_ 2147548664 UtilityTotalApparentPower "RANGE";
BA_ "SPN" SG_ 2147548664 UtilityTotalApparentPower 2494;
BA_ "SigType" SG_ 2147548664 UtilityTotalRealPower "RANGE";
BA_ "SPN" SG_ 2147548664 UtilityTotalRealPower 2486;
BA_ "SigType" SG_ 2147548653 UtilityTotalKWHoursImport "DISCRETE";
BA_ "SPN" SG_ 2147548653 UtilityTotalKWHoursImport 2503;
BA_ "SigType" SG_ 2147548653 UtilityTotalKWHoursExport "DISCRETE";
BA_ "SPN" SG_ 2147548653 UtilityTotalKWHoursExport 2502;
BA_ "SigType" SG_ 2147548654 UtilityPhaseCPowerFactorLagging "DISCRETE";
BA_ "SPN" SG_ 2147548654 UtilityPhaseCPowerFactorLagging 2525;
BA_ "SigType" SG_ 2147548654 UtilityPhaseCPowerFactor "RANGE";
BA_ "SPN" SG_ 2147548654 UtilityPhaseCPowerFactor 2501;
BA_ "SigType" SG_ 2147548654 UtilityPhaseCReactivePower "RANGE";
BA_ "SPN" SG_ 2147548654 UtilityPhaseCReactivePower 2493;
BA_ "SigType" SG_ 2147548655 UtilityPhaseCApparentPower "RANGE";
BA_ "SPN" SG_ 2147548655 UtilityPhaseCApparentPower 2497;
BA_ "SigType" SG_ 2147548655 UtilityPhaseCRealPower "RANGE";
BA_ "SPN" SG_ 2147548655 UtilityPhaseCRealPower 2489;
BA_ "SigType" SG_ 2147548656 UtilityPhaseCACRMSCurrent "RANGE";
BA_ "SPN" SG_ 2147548656 UtilityPhaseCACRMSCurrent 2485;
BA_ "SigType" SG_ 2147548656 UtilityPhaseCACFrequency "RANGE";
BA_ "SPN" SG_ 2147548656 UtilityPhaseCACFrequency 2473;
BA_ "SigType" SG_ 2147548656 UtltyPhsCLneNeutralACRMSVoltage "RANGE";
BA_ "SPN" SG_ 2147548656 UtltyPhsCLneNeutralACRMSVoltage 2481;
BA_ "SigType" SG_ 2147548656 UtltyPhseCALineLineACRMSVoltage "RANGE";
BA_ "SPN" SG_ 2147548656 UtltyPhseCALineLineACRMSVoltage 2477;
BA_ "SigType" SG_ 2147548657 UtilityPhaseBPowerFactorLagging "DISCRETE";
BA_ "SPN" SG_ 2147548657 UtilityPhaseBPowerFactorLagging 2524;
BA_ "SigType" SG_ 2147548657 UtilityPhaseBPowerFactor "RANGE";
BA_ "SPN" SG_ 2147548657 UtilityPhaseBPowerFactor 2500;
BA_ "SigType" SG_ 2147548657 UtilityPhaseBReactivePower "RANGE";
BA_ "SPN" SG_ 2147548657 UtilityPhaseBReactivePower 2492;
BA_ "SigType" SG_ 2147548658 UtilityPhaseBApparentPower "RANGE";
BA_ "SPN" SG_ 2147548658 UtilityPhaseBApparentPower 2496;
BA_ "SigType" SG_ 2147548658 UtilityPhaseBRealPower "RANGE";
BA_ "SPN" SG_ 2147548658 UtilityPhaseBRealPower 2488;
BA_ "SigType" SG_ 2147548659 UtilityPhaseBACRMSCurrent "RANGE";
BA_ "SPN" SG_ 2147548659 UtilityPhaseBACRMSCurrent 2484;
BA_ "SigType" SG_ 2147548659 UtilityPhaseBACFrequency "RANGE";
BA_ "SPN" SG_ 2147548659 UtilityPhaseBACFrequency 2472;
BA_ "SigType" SG_ 2147548659 UtltyPhsBLneNeutralACRMSVoltage "RANGE";
BA_ "SPN" SG_ 2147548659 UtltyPhsBLneNeutralACRMSVoltage 2480;
BA_ "SigType" SG_ 2147548659 UtltyPhseBCLineLineACRMSVoltage "RANGE";
BA_ "SPN" SG_ 2147548659 UtltyPhseBCLineLineACRMSVoltage 2476;
BA_ "SigType" SG_ 2147548660 UtilityPhaseAPowerFactorLagging "DISCRETE";
BA_ "SPN" SG_ 2147548660 UtilityPhaseAPowerFactorLagging 2523;
BA_ "SigType" SG_ 2147548660 UtilityPhaseAPowerFactor "RANGE";
BA_ "SPN" SG_ 2147548660 UtilityPhaseAPowerFactor 2499;
BA_ "SigType" SG_ 2147548660 UtilityPhaseAReactivePower "RANGE";
BA_ "SPN" SG_ 2147548660 UtilityPhaseAReactivePower 2491;
BA_ "SigType" SG_ 2147548661 UtilityPhaseAApparentPower "RANGE";
BA_ "SPN" SG_ 2147548661 UtilityPhaseAApparentPower 2495;
BA_ "SigType" SG_ 2147548661 UtilityPhaseARealPower "RANGE";
BA_ "SPN" SG_ 2147548661 UtilityPhaseARealPower 2487;
BA_ "SigType" SG_ 2147548662 UtilityPhaseAACRMSCurrent "RANGE";
BA_ "SPN" SG_ 2147548662 UtilityPhaseAACRMSCurrent 2483;
BA_ "SigType" SG_ 2147548662 UtilityPhaseAACFrequency "RANGE";
BA_ "SPN" SG_ 2147548662 UtilityPhaseAACFrequency 2471;
BA_ "SigType" SG_ 2147548662 UtltyPhsALneNeutralACRMSVoltage "RANGE";
BA_ "SPN" SG_ 2147548662 UtltyPhsALneNeutralACRMSVoltage 2479;
BA_ "SigType" SG_ 2147548662 UtltyPhseABLineLineACRMSVoltage "RANGE";
BA_ "SPN" SG_ 2147548662 UtltyPhseABLineLineACRMSVoltage 2475;
BA_ "SigType" SG_ 2147548665 UtilityAverageACRMSCurrent "RANGE";
BA_ "SPN" SG_ 2147548665 UtilityAverageACRMSCurrent 2482;
BA_ "SigType" SG_ 2147548665 UtilityAverageACFrequency "RANGE";
BA_ "SPN" SG_ 2147548665 UtilityAverageACFrequency 2470;
BA_ "SigType" SG_ 2147548665 UtltyAvrgLneNeutralACRMSVoltage "RANGE";
BA_ "SPN" SG_ 2147548665 UtltyAvrgLneNeutralACRMSVoltage 2478;
BA_ "SigType" SG_ 2147548665 UtltyAvrageLineLineACRMSVoltage "RANGE";
BA_ "SPN" SG_ 2147548665 UtltyAvrageLineLineACRMSVoltage 2474;
BA_ "SigType" SG_ 2147548676 GnrtorOverallPowerFactorLagging "DISCRETE";
BA_ "SPN" SG_ 2147548676 GnrtorOverallPowerFactorLagging 2518;
BA_ "SigType" SG_ 2147548676 GeneratorOverallPowerFactor "RANGE";
BA_ "SPN" SG_ 2147548676 GeneratorOverallPowerFactor 2464;
BA_ "SigType" SG_ 2147548676 GeneratorTotalReactivePower "RANGE";
BA_ "SPN" SG_ 2147548676 GeneratorTotalReactivePower 2456;
BA_ "SigType" SG_ 2147548677 GeneratorTotalApparentPower "RANGE";
BA_ "SPN" SG_ 2147548677 GeneratorTotalApparentPower 2460;
BA_ "SigType" SG_ 2147548677 GeneratorTotalRealPower "RANGE";
BA_ "SPN" SG_ 2147548677 GeneratorTotalRealPower 2452;
BA_ "SigType" SG_ 2147548666 GeneratorTotalKWHoursImport "DISCRETE";
BA_ "SPN" SG_ 2147548666 GeneratorTotalKWHoursImport 2469;
BA_ "SigType" SG_ 2147548666 GeneratorTotalKWHoursExport "DISCRETE";
BA_ "SPN" SG_ 2147548666 GeneratorTotalKWHoursExport 2468;
BA_ "SigType" SG_ 2147548667 GnratorPhaseCPowerFactorLagging "DISCRETE";
BA_ "SPN" SG_ 2147548667 GnratorPhaseCPowerFactorLagging 2521;
BA_ "SigType" SG_ 2147548667 GeneratorPhaseCPowerFactor "RANGE";
BA_ "SPN" SG_ 2147548667 GeneratorPhaseCPowerFactor 2467;
BA_ "SigType" SG_ 2147548667 GeneratorPhaseCReactivePower "RANGE";
BA_ "SPN" SG_ 2147548667 GeneratorPhaseCReactivePower 2459;
BA_ "SigType" SG_ 2147548668 GeneratorPhaseCApparentPower "RANGE";
BA_ "SPN" SG_ 2147548668 GeneratorPhaseCApparentPower 2463;
BA_ "SigType" SG_ 2147548668 GeneratorPhaseCRealPower "RANGE";
BA_ "SPN" SG_ 2147548668 GeneratorPhaseCRealPower 2455;
BA_ "SigType" SG_ 2147548669 GeneratorPhaseCACRMSCurrent "RANGE";
BA_ "SPN" SG_ 2147548669 GeneratorPhaseCACRMSCurrent 2451;
BA_ "SigType" SG_ 2147548669 GeneratorPhaseCACFrequency "RANGE";
BA_ "SPN" SG_ 2147548669 GeneratorPhaseCACFrequency 2439;
BA_ "SigType" SG_ 2147548669 GnrtrPhsCLneNeutralACRMSVoltage "RANGE";
BA_ "SPN" SG_ 2147548669 GnrtrPhsCLneNeutralACRMSVoltage 2447;
BA_ "SigType" SG_ 2147548669 GnrtrPhseCALineLineACRMSVoltage "RANGE";
BA_ "SPN" SG_ 2147548669 GnrtrPhseCALineLineACRMSVoltage 2443;
BA_ "SigType" SG_ 2147548670 GnratorPhaseBPowerFactorLagging "DISCRETE";
BA_ "SPN" SG_ 2147548670 GnratorPhaseBPowerFactorLagging 2520;
BA_ "SigType" SG_ 2147548670 GeneratorPhaseBPowerFactor "RANGE";
BA_ "SPN" SG_ 2147548670 GeneratorPhaseBPowerFactor 2466;
BA_ "SigType" SG_ 2147548670 GeneratorPhaseBReactivePower "RANGE";
BA_ "SPN" SG_ 2147548670 GeneratorPhaseBReactivePower 2458;
BA_ "SigType" SG_ 2147548671 GeneratorPhaseBApparentPower "RANGE";
BA_ "SPN" SG_ 2147548671 GeneratorPhaseBApparentPower 2462;
BA_ "SigType" SG_ 2147548671 GeneratorPhaseBRealPower "RANGE";
BA_ "SPN" SG_ 2147548671 GeneratorPhaseBRealPower 2454;
BA_ "SigType" SG_ 2147548672 GeneratorPhaseBACRMSCurrent "RANGE";
BA_ "SPN" SG_ 2147548672 GeneratorPhaseBACRMSCurrent 2450;
BA_ "SigType" SG_ 2147548672 GeneratorPhaseBACFrequency "RANGE";
BA_ "SPN" SG_ 2147548672 GeneratorPhaseBACFrequency 2438;
BA_ "SigType" SG_ 2147548672 GnrtrPhsBLneNeutralACRMSVoltage "RANGE";
BA_ "SPN" SG_ 2147548672 GnrtrPhsBLneNeutralACRMSVoltage 2446;
BA_ "SigType" SG_ 2147548672 GnrtrPhseBCLineLineACRMSVoltage "RANGE";
BA_ "SPN" SG_ 2147548672 GnrtrPhseBCLineLineACRMSVoltage 2442;
BA_ "SigType" SG_ 2147548673 GnratorPhaseAPowerFactorLagging "DISCRETE";
BA_ "SPN" SG_ 2147548673 GnratorPhaseAPowerFactorLagging 2519;
BA_ "SigType" SG_ 2147548673 GeneratorPhaseAPowerFactor "RANGE";
BA_ "SPN" SG_ 2147548673 GeneratorPhaseAPowerFactor 2465;
BA_ "SigType" SG_ 2147548673 GeneratorPhaseAReactivePower "RANGE";
BA_ "SPN" SG_ 2147548673 GeneratorPhaseAReactivePower 2457;
BA_ "SigType" SG_ 2147548674 GeneratorPhaseAApparentPower "RANGE";
BA_ "SPN" SG_ 2147548674 GeneratorPhaseAApparentPower 2461;
BA_ "SigType" SG_ 2147548674 GeneratorPhaseARealPower "RANGE";
BA_ "SPN" SG_ 2147548674 GeneratorPhaseARealPower 2453;
BA_ "SigType" SG_ 2147548675 GeneratorPhaseAACRMSCurrent "RANGE";
BA_ "SPN" SG_ 2147548675 GeneratorPhaseAACRMSCurrent 2449;
BA_ "SigType" SG_ 2147548675 GeneratorPhaseAACFrequency "RANGE";
BA_ "SPN" SG_ 2147548675 GeneratorPhaseAACFrequency 2437;
BA_ "SigType" SG_ 2147548675 GnrtrPhsALneNeutralACRMSVoltage "RANGE";
BA_ "SPN" SG_ 2147548675 GnrtrPhsALneNeutralACRMSVoltage 2445;
BA_ "SigType" SG_ 2147548675 GnrtrPhseABLineLineACRMSVoltage "RANGE";
BA_ "SPN" SG_ 2147548675 GnrtrPhseABLineLineACRMSVoltage 2441;
BA_ "SigType" SG_ 2147548678 GeneratorAverageACRMSCurrent "RANGE";
BA_ "SPN" SG_ 2147548678 GeneratorAverageACRMSCurrent 2448;
BA_ "SigType" SG_ 2147548678 GeneratorAverageACFrequency "RANGE";
BA_ "SPN" SG_ 2147548678 GeneratorAverageACFrequency 2436;
BA_ "SigType" SG_ 2147548678 GnrtrAvrgLneNeutralACRMSVoltage "RANGE";
BA_ "SPN" SG_ 2147548678 GnrtrAvrgLneNeutralACRMSVoltage 2444;
BA_ "SigType" SG_ 2147548678 GnrtrAvrageLineLineACRMSVoltage "RANGE";
BA_ "SPN" SG_ 2147548678 GnrtrAvrageLineLineACRMSVoltage 2440;
BA_ "SigType" SG_ 2147548647 Bus1_UtilityACPhaseDifference "RANGE";
BA_ "SPN" SG_ 2147548647 Bus1_UtilityACPhaseDifference 2517;
BA_ "SigType" SG_ 2147548647 Bus1_UtilityInSync "DISCRETE";
BA_ "SPN" SG_ 2147548647 Bus1_UtilityInSync 2534;
BA_ "SigType" SG_ 2147548647 Bus1_UtilityVoltageMatch "DISCRETE";
BA_ "SPN" SG_ 2147548647 Bus1_UtilityVoltageMatch 2532;
BA_ "SigType" SG_ 2147548647 Bus1_UtilityFrequencyMatch "DISCRETE";
BA_ "SPN" SG_ 2147548647 Bus1_UtilityFrequencyMatch 2533;
BA_ "SigType" SG_ 2147548647 Bus1_UtilityPhaseMatch "DISCRETE";
BA_ "SPN" SG_ 2147548647 Bus1_UtilityPhaseMatch 2531;
BA_ "SigType" SG_ 2147548647 Bus1_UtilityDeadBus "DISCRETE";
BA_ "SPN" SG_ 2147548647 Bus1_UtilityDeadBus 2535;
BA_ "SigType" SG_ 2147548649 Bus1PhaseCACFrequency "RANGE";
BA_ "SPN" SG_ 2147548649 Bus1PhaseCACFrequency 2507;
BA_ "SigType" SG_ 2147548649 Bs1PhseCLineNeutralACRMSVoltage "RANGE";
BA_ "SPN" SG_ 2147548649 Bs1PhseCLineNeutralACRMSVoltage 2515;
BA_ "SigType" SG_ 2147548649 Bus1PhaseCALineLineACRMSVoltage "RANGE";
BA_ "SPN" SG_ 2147548649 Bus1PhaseCALineLineACRMSVoltage 2511;
BA_ "SigType" SG_ 2147548650 Bus1PhaseBACFrequency "RANGE";
BA_ "SPN" SG_ 2147548650 Bus1PhaseBACFrequency 2506;
BA_ "SigType" SG_ 2147548650 Bs1PhseBLineNeutralACRMSVoltage "RANGE";
BA_ "SPN" SG_ 2147548650 Bs1PhseBLineNeutralACRMSVoltage 2514;
BA_ "SigType" SG_ 2147548650 Bus1PhaseBCLineLineACRMSVoltage "RANGE";
BA_ "SPN" SG_ 2147548650 Bus1PhaseBCLineLineACRMSVoltage 2510;
BA_ "SigType" SG_ 2147548651 Bus1PhaseAACFrequency "RANGE";
BA_ "SPN" SG_ 2147548651 Bus1PhaseAACFrequency 2505;
BA_ "SigType" SG_ 2147548651 Bs1PhseALineNeutralACRMSVoltage "RANGE";
BA_ "SPN" SG_ 2147548651 Bs1PhseALineNeutralACRMSVoltage 2513;
BA_ "SigType" SG_ 2147548651 Bus1PhaseABLineLineACRMSVoltage "RANGE";
BA_ "SPN" SG_ 2147548651 Bus1PhaseABLineLineACRMSVoltage 2509;
BA_ "SigType" SG_ 2147548648 Bus1_GeneratorACPhaseDifference "RANGE";
BA_ "SPN" SG_ 2147548648 Bus1_GeneratorACPhaseDifference 2516;
BA_ "SigType" SG_ 2147548648 Bus1_GeneratorInSync "DISCRETE";
BA_ "SPN" SG_ 2147548648 Bus1_GeneratorInSync 2529;
BA_ "SigType" SG_ 2147548648 Bus1_GeneratorVoltageMatch "DISCRETE";
BA_ "SPN" SG_ 2147548648 Bus1_GeneratorVoltageMatch 2527;
BA_ "SigType" SG_ 2147548648 Bus1_GeneratorFrequencyMatch "DISCRETE";
BA_ "SPN" SG_ 2147548648 Bus1_GeneratorFrequencyMatch 2528;
BA_ "SigType" SG_ 2147548648 Bus1_GeneratorPhaseMatch "DISCRETE";
BA_ "SPN" SG_ 2147548648 Bus1_GeneratorPhaseMatch 2526;
BA_ "SigType" SG_ 2147548648 Bus1_GeneratorDeadBus "DISCRETE";
BA_ "SPN" SG_ 2147548648 Bus1_GeneratorDeadBus 2530;
BA_ "SigType" SG_ 2147548652 Bus1AverageACFrequency "RANGE";
BA_ "SPN" SG_ 2147548652 Bus1AverageACFrequency 2504;
BA_ "SigType" SG_ 2147548652 Bs1AvrgeLineNeutralACRMSVoltage "RANGE";
BA_ "SPN" SG_ 2147548652 Bs1AvrgeLineNeutralACRMSVoltage 2512;
BA_ "SigType" SG_ 2147548652 Bus1AverageLineLineACRMSVoltage "RANGE";
BA_ "SPN" SG_ 2147548652 Bus1AverageLineLineACRMSVoltage 2508;
BA_ "SigType" SG_ 2147548888 AddressAssignment "RANGE";
BA_ "SPN" SG_ 2147548888 AddressAssignment 2847;
BA_ "SigType" SG_ 2147535360 ShrtNameOfActualReportingDevice "DISCRETE";
BA_ "SPN" SG_ 2147535360 ShrtNameOfActualReportingDevice 2554;
BA_ "SigType" SG_ 2147535360 LengthOfDataForTheReportedPGN "RANGE";
BA_ "SPN" SG_ 2147535360 LengthOfDataForTheReportedPGN 2553;
BA_ "SigType" SG_ 2147535360 PGNofRequstedInformation "RANGE";
BA_ "SPN" SG_ 2147535360 PGNofRequstedInformation 2552;
BA_ "SigType" SG_ 2147543808 SequenceNumber "RANGE";
BA_ "SPN" SG_ 2147543808 SequenceNumber 2572;
BA_ "SigType" SG_ 2147544064 PGNumber "SPECIFIC";
BA_ "SPN" SG_ 2147544064 PGNumber 2560;
BA_ "SigType" SG_ 2147544064 ConnectionAbortReason "RANGE";
BA_ "SPN" SG_ 2147544064 ConnectionAbortReason 2570;
BA_ "SigType" SG_ 2147544064 NextPacketNumberToBeSent "RANGE";
BA_ "SPN" SG_ 2147544064 NextPacketNumberToBeSent 2562;
BA_ "SigType" SG_ 2147544064 NumberOfPacketsThatCanBeSent "RANGE";
BA_ "SPN" SG_ 2147544064 NumberOfPacketsThatCanBeSent 2561;
BA_ "SigType" SG_ 2147544064 MaximumNumberOfPackets "RANGE";
BA_ "SPN" SG_ 2147544064 MaximumNumberOfPackets 2559;
BA_ "SigType" SG_ 2147544064 TotalNumberOfPackets "RANGE";
BA_ "SPN" SG_ 2147544064 TotalNumberOfPackets 2558;
BA_ "SigType" SG_ 2147544064 TotalMessageSize "RANGE";
BA_ "SPN" SG_ 2147544064 TotalMessageSize 2557;
BA_ "SigType" SG_ 2147544064 ControlByte "SPECIFIC";
BA_ "SPN" SG_ 2147544064 ControlByte 2556;
BA_ "SigType" SG_ 2147535104 UseTransferMode "DISCRETE";
BA_ "SPN" SG_ 2147535104 UseTransferMode 2575;
BA_ "SigType" SG_ 2147535104 ParameterGroupNumber "RANGE";
BA_ "SPN" SG_ 2147535104 ParameterGroupNumber 2574;
BA_ "SigType" SG_ 2147543552 RqstedPGN "RANGE";
BA_ "SPN" SG_ 2147543552 RqstedPGN 2574;
BA_ "SigType" SG_ 2147548917 RoadSurfaceTemp "RANGE";
BA_ "SPN" SG_ 2147548917 RoadSurfaceTemp 79;
BA_ "SigType" SG_ 2147548917 EngAirInletTemp "RANGE";
BA_ "SPN" SG_ 2147548917 EngAirInletTemp 172;
BA_ "SigType" SG_ 2147548917 AmbientAirTemp "RANGE";
BA_ "SPN" SG_ 2147548917 AmbientAirTemp 171;
BA_ "SigType" SG_ 2147548917 CabInteriorTemp "RANGE";
BA_ "SPN" SG_ 2147548917 CabInteriorTemp 170;
BA_ "SigType" SG_ 2147548917 BarometricPress "RANGE";
BA_ "SPN" SG_ 2147548917 BarometricPress 108;
BA_ "SigType" SG_ 2147548894 EngAirStartPress "RANGE";
BA_ "SPN" SG_ 2147548894 EngAirStartPress 82;
BA_ "SigType" SG_ 2147548846 AirSuspensionSupplyPress "RANGE";
BA_ "SPN" SG_ 2147548846 AirSuspensionSupplyPress 1090;
BA_ "SigType" SG_ 2147548846 AuxEquipmentSupplyPress "RANGE";
BA_ "SPN" SG_ 2147548846 AuxEquipmentSupplyPress 1089;
BA_ "SigType" SG_ 2147548846 ServiceBrakeAirPressCircuit2 "RANGE";
BA_ "SPN" SG_ 2147548846 ServiceBrakeAirPressCircuit2 1088;
BA_ "SigType" SG_ 2147548846 ServiceBrakeAirPressCircuit1 "RANGE";
BA_ "SPN" SG_ 2147548846 ServiceBrakeAirPressCircuit1 1087;
BA_ "SigType" SG_ 2147548846 ParkingAnd_OrTrailerAirPress "RANGE";
BA_ "SPN" SG_ 2147548846 ParkingAnd_OrTrailerAirPress 1086;
BA_ "SigType" SG_ 2147548846 PneumaticSupplyPress "RANGE";
BA_ "SPN" SG_ 2147548846 PneumaticSupplyPress 46;
BA_ "SigType" SG_ 2147548921 SteerAxleLubePress "RANGE";
BA_ "SPN" SG_ 2147548921 SteerAxleLubePress 2614;
BA_ "SigType" SG_ 2147548921 SteerAxleTemp "RANGE";
BA_ "SPN" SG_ 2147548921 SteerAxleTemp 75;
BA_ "SigType" SG_ 2147548921 DriveAxleLubePress "RANGE";
BA_ "SPN" SG_ 2147548921 DriveAxleLubePress 2613;
BA_ "SigType" SG_ 2147548921 DriveAxleTemp "RANGE";
BA_ "SPN" SG_ 2147548921 DriveAxleTemp 578;
BA_ "SigType" SG_ 2147548921 DriveAxleLiftAirPress "RANGE";
BA_ "SPN" SG_ 2147548921 DriveAxleLiftAirPress 579;
BA_ "SigType" SG_ 2147548921 DriveAxleLocation "RANGE";
BA_ "SPN" SG_ 2147548921 DriveAxleLocation 930;
BA_ "SigType" SG_ 2147548842 EngTurboWastegateValvePos "RANGE";
BA_ "SPN" SG_ 2147548842 EngTurboWastegateValvePos 1693;
BA_ "SigType" SG_ 2147548842 EngGsMssFlwSnsrFelingCorrection "RANGE";
BA_ "SPN" SG_ 2147548842 EngGsMssFlwSnsrFelingCorrection 1694;
BA_ "SigType" SG_ 2147548842 EngDsiredAbsIntakeManifoldPress "RANGE";
BA_ "SPN" SG_ 2147548842 EngDsiredAbsIntakeManifoldPress 1692;
BA_ "SigType" SG_ 2147548842 EngGasFuelCorrectionFactor "RANGE";
BA_ "SPN" SG_ 2147548842 EngGasFuelCorrectionFactor 1116;
BA_ "SigType" SG_ 2147548753 RqedACCDistanceMode "DISCRETE";
BA_ "SPN" SG_ 2147548753 RqedACCDistanceMode 1799;
BA_ "SigType" SG_ 2147548783 ACCDistanceAlertSignal "DISCRETE";
BA_ "SPN" SG_ 2147548783 ACCDistanceAlertSignal 1796;
BA_ "SigType" SG_ 2147548783 ACCSystemShutoffWarning "DISCRETE";
BA_ "SPN" SG_ 2147548783 ACCSystemShutoffWarning 1797;
BA_ "SigType" SG_ 2147548783 ACCTargetDetected "DISCRETE";
BA_ "SPN" SG_ 2147548783 ACCTargetDetected 1798;
BA_ "SigType" SG_ 2147548783 RoadCurvature "RANGE";
BA_ "SPN" SG_ 2147548783 RoadCurvature 1591;
BA_ "SigType" SG_ 2147548783 AdptveCruiseCtrlSetDistanceMode "DISCRETE";
BA_ "SPN" SG_ 2147548783 AdptveCruiseCtrlSetDistanceMode 1589;
BA_ "SigType" SG_ 2147548783 AdaptiveCruiseCtrlMode "DISCRETE";
BA_ "SPN" SG_ 2147548783 AdaptiveCruiseCtrlMode 1590;
BA_ "SigType" SG_ 2147548783 AdaptiveCruiseCtrlSetSpeed "RANGE";
BA_ "SPN" SG_ 2147548783 AdaptiveCruiseCtrlSetSpeed 1588;
BA_ "SigType" SG_ 2147548783 DistanceToForwardVehicle "RANGE";
BA_ "SPN" SG_ 2147548783 DistanceToForwardVehicle 1587;
BA_ "SigType" SG_ 2147548783 SpeedOfForwardVehicle "RANGE";
BA_ "SPN" SG_ 2147548783 SpeedOfForwardVehicle 1586;
BA_ "SigType" SG_ 2147548840 ArticulationAngle "RANGE";
BA_ "SPN" SG_ 2147548840 ArticulationAngle 1120;
BA_ "SigType" SG_ 2147548812 AuxLevel "RANGE";
BA_ "SPN" SG_ 2147548812 AuxLevel 3087;
BA_ "SigType" SG_ 2147548812 AuxPress2 "RANGE";
BA_ "SPN" SG_ 2147548812 AuxPress2 1388;
BA_ "SigType" SG_ 2147548812 AuxPress1 "RANGE";
BA_ "SPN" SG_ 2147548812 AuxPress1 1387;
BA_ "SigType" SG_ 2147548812 AuxTemp2 "RANGE";
BA_ "SPN" SG_ 2147548812 AuxTemp2 442;
BA_ "SigType" SG_ 2147548812 AuxTemp1 "RANGE";
BA_ "SPN" SG_ 2147548812 AuxTemp1 441;
BA_ "SigType" SG_ 2147548925 EngBlowerBypassValvePos "RANGE";
BA_ "SPN" SG_ 2147548925 EngBlowerBypassValvePos 72;
BA_ "SigType" SG_ 2147548925 EngGasSupplyPress "RANGE";
BA_ "SPN" SG_ 2147548925 EngGasSupplyPress 159;
BA_ "SigType" SG_ 2147543040 PGNumber "RANGE";
BA_ "SPN" SG_ 2147543040 PGNumber 2574;
BA_ "SigType" SG_ 2147543040 GroupFunctionValue "RANGE";
BA_ "SPN" SG_ 2147543040 GroupFunctionValue 2542;
BA_ "SigType" SG_ 2147543040 CtrlByte "SPECIFIC";
BA_ "SPN" SG_ 2147543040 CtrlByte 2556;
VAL_ 2147548630 Joystick1XAxisDetentPosStatus 3 "NotAvailable" 2 "ErrorIndicator" 1 "InDetentPos" 0 "NotInDetentPos" ;
VAL_ 2147548630 Joystick1YAxisDetentPosStatus 3 "NotAvailable" 2 "ErrorIndicator" 1 "InDetentPos" 0 "NotInDetentPos" ;
VAL_ 2147548630 Jystck1YAxsLvrFrwrdPstvPsStatus 1 "OnPositiveSideOfNeutral" 0 "NotOnPositiveSideOfNeutral" 3 "NotAvailable" 2 "ErrorIndicator" ;
VAL_ 2147548630 Jystck1YAxsLvrBckNgtvePosStatus 3 "NotAvailable" 2 "ErrorIndicator" 1 "OnNegativeSideOfNeutral" 0 "NotOnNegativeSideOfNeutral" ;
VAL_ 2147548630 Joystick1YAxisNeutralPosStatus 3 "NotAvailable" 2 "ErrorIndicator" 1 "InNeutralPos" 0 "NotInNeutralPos" ;
VAL_ 2147548630 Joystick1Button9PressedStatus 3 "NotAvailable" 2 "ErrorIndicator" 1 "ButtonPressed" 0 "ButtonNotPressed" ;
VAL_ 2147548630 Joystick1Button10PressedStatus 3 "NotAvailable" 2 "ErrorIndicator" 1 "ButtonPressed" 0 "ButtonNotPressed" ;
VAL_ 2147548630 Joystick1Button11PressedStatus 3 "NotAvailable" 2 "ErrorIndicator" 1 "ButtonPressed" 0 "ButtonNotPressed" ;
VAL_ 2147548630 Joystick1Button12PressedStatus 3 "NotAvailable" 2 "ErrorIndicator" 1 "ButtonPressed" 0 "ButtonNotPressed" ;
VAL_ 2147548630 Joystick1Button5PressedStatus 3 "NotAvailable" 2 "ErrorIndicator" 1 "ButtonPressed" 0 "ButtonNotPressed" ;
VAL_ 2147548630 Joystick1Button6PressedStatus 3 "NotAvailable" 2 "ErrorIndicator" 1 "ButtonPressed" 0 "ButtonNotPressed" ;
VAL_ 2147548630 Joystick1Button7PressedStatus 3 "NotAvailable" 2 "ErrorIndicator" 1 "ButtonPressed" 0 "ButtonNotPressed" ;
VAL_ 2147548630 Joystick1Button8PressedStatus 3 "NotAvailable" 2 "ErrorIndicator" 1 "ButtonPressed" 0 "ButtonNotPressed" ;
VAL_ 2147548630 Joystick1Button1PressedStatus 3 "NotAvailable" 2 "ErrorIndicator" 1 "ButtonPressed" 0 "ButtonNotPressed" ;
VAL_ 2147548630 Joystick1Button2PressedStatus 3 "NotAvailable" 2 "ErrorIndicator" 1 "ButtonPressed" 0 "ButtonNotPressed" ;
VAL_ 2147548630 Joystick1Button3PressedStatus 3 "NotAvailable" 2 "ErrorIndicator" 1 "ButtonPressed" 0 "ButtonNotPressed" ;
VAL_ 2147548630 Joystick1Button4PressedStatus 3 "NotAvailable" 2 "ErrorIndicator" 1 "ButtonPressed" 0 "ButtonNotPressed" ;
VAL_ 2147548630 Jystck1XAxsLvrRghtPstvPosStatus 3 "NotAvailable" 2 "ErrorIndicator" 1 "OnPositiveSideOfNeutral" 0 "NotOnPositiveSideOfNeutral" ;
VAL_ 2147548630 Jystck1XAxsLvrLftNgtvePosStatus 3 "NotAvailable" 2 "ErrorIndicator" 1 "OnNegativeSideOfNeutral" 0 "NotOnNegativeSideOfNeutral" ;
VAL_ 2147548630 Joystick1XAxisNeutralPosStatus 3 "NotAvailable" 2 "ErrorIndicator" 1 "InNeutralPos" 0 "NotInNeutralPos" ;
VAL_ 2147548922 ParkingBrakeActuator 1 "ParkingBrakeActuatorActive" 0 "ParkingBrakeActuatorInactive" ;
VAL_ 2147548889 AuxI_O13 1 "AuxChannelOn" 0 "AuxChannelOff" ;
VAL_ 2147548889 AuxI_O14 1 "AuxChannelOn" 0 "AuxChannelOff" ;
VAL_ 2147548889 AuxI_O15 1 "AuxChannelOn" 0 "AuxChannelOff" ;
VAL_ 2147548889 AuxI_O16 1 "AuxChannelOn" 0 "AuxChannelOff" ;
VAL_ 2147548889 AuxI_O09 1 "AuxChannelOn" 0 "AuxChannelOff" ;
VAL_ 2147548889 AuxI_O10 1 "AuxChannelOn" 0 "AuxChannelOff" ;
VAL_ 2147548889 AuxI_O11 1 "AuxChannelOn" 0 "AuxChannelOff" ;
VAL_ 2147548889 AuxI_O12 1 "AuxChannelOn" 0 "AuxChannelOff" ;
VAL_ 2147548889 AuxI_O05 1 "AuxChannelOn" 0 "AuxChannelOff" ;
VAL_ 2147548889 AuxI_O06 1 "AuxChannelOn" 0 "AuxChannelOff" ;
VAL_ 2147548889 AuxI_O07 1 "AuxChannelOn" 0 "AuxChannelOff" ;
VAL_ 2147548889 AuxI_O08 1 "AuxChannelOn" 0 "AuxChannelOff" ;
VAL_ 2147548889 AuxI_O01 1 "AuxChannelOn" 0 "AuxChannelOff" ;
VAL_ 2147548889 AuxI_O02 1 "AuxChannelOn" 0 "AuxChannelOff" ;
VAL_ 2147548889 AuxI_O03 1 "AuxChannelOn" 0 "AuxChannelOff" ;
VAL_ 2147548889 AuxI_O04 1 "AuxChannelOn" 0 "AuxChannelOff" ;
VAL_ 2147539968 AntitheftComponentStatusStates 3 "NotDefined" 2 "BlckdThsSttIndctsThtALckUnlckCm" 1 "Locked" 0 "UnlckdThsSttIndctsThtCmpnntCnBS" ;
VAL_ 2147539968 AntthftEncryptnSdPrsntIndicator 1 "RandomNumberIsPresent" 0 "RandomNumberIsNotPresent" ;
VAL_ 2147539968 AntitheftModifyPwdStates 3 "Notvalid" 2 "EmptyOfPwdsThsSttIndctsThtCmpnn" 1 "FullofPwds" 0 "OkThsSttIndctsThtRqWsSccssfllyP" ;
VAL_ 2147539968 AntitheftPwdValidIndicator 1 "PwdIsAValidatedPassword" 0 "PwdIsNotAValidatedPassword" ;
VAL_ 2147540224 AntitheftCmdStates 6 "111NotDefined" 5 "Login" 4 "ChckSttsThsSttRprsntsARqTChckTS" 3 "LockorUnlock" 2 "ChngPwdThsSttRprsntsARqTCmpnntT" 1 "DeletePwd" 0 "AddPwdThsSttRprsntsARqTCmpnntTA" ;
VAL_ 2147540224 AntitheftDesiredExitModeStates 3 "NotAvailable" 2 "NotDefined" 1 "LockWhenKeyOff" 0 "LckUpnOprtrRqThsSttIsUsdTIndctT" ;
VAL_ 2147540224 AntthftEncryptonIndicatorStates 3 "NotAvailable" 2 "NotDefined" 1 "EncryptedCodePresent" 0 "EncryptnSdRqThsSttRprsntsARqstT" ;
VAL_ 2147548759 ElctrncShckAbsrbrCtrlMdLft_TgAxl 3 "NotAvailable" 2 "Error" 1 "NormalOperationDampersActive" 0 "NormalOperationDampersPassive" ;
VAL_ 2147548759 ElctrncShckAbsrbrCtrlMdRearAxle 3 "NotAvailable" 2 "Error" 1 "NormalOperationDampersActive" 0 "NormalOperationDampersPassive" ;
VAL_ 2147548759 ElctrncShckAbsrbrCtrlMdFrntAxle 3 "NotAvailable" 2 "Error" 1 "NormalOperationDampersActive" 0 "NormalOperationDampersPassive" ;
VAL_ 2147537408 KneelingCmdRearAxle 3 "DontCare_TakeNoAction" 2 "Reserved" 1 "ActivateKneeling" 0 "DeactivateKneeling" ;
VAL_ 2147537408 KneelingCmdFrontAxle 3 "DontCare_TakeNoAction" 2 "Reserved" 1 "ActivateKneeling" 0 "DeactivateKneeling" ;
VAL_ 2147537408 LevelCtrlModeRq 15 "DontCare_TakeNoAction" 14 "Reserved" 9 "1101NotDefined" 8 "ExhaustBellows" 7 "TractionHelpLoadReduce" 6 "OptmmTrctn2IPrssAtThDrvnAxlIsCt" 5 "OptmmTrctn1IPrssAtThDrvnAxlIsCt" 4 "PrssRt2IRtBtwnThPrssrsAtThDrvnA" 3 "PrssRt1IRtBtwnThPrssrsAtThDrvnA" 2 "LdFxngIDrvnAxlnIsLddTAVlDfndByT" 1 "TrctnHlpIDrvnAxlIsLddTAMxVlGvnB" 0 "NrmlOprtnISystmPrfrmsAPrCtrlOfT" ;
VAL_ 2147537408 NominalLevelRqRearAxle 15 "DontCare_TakeNoAction" 14 "Reserved" 9 "1101NotDefined" 8 "StopLevelChange" 7 "LowerLevel" 6 "UpperLevel" 5 "CustomerLevel" 4 "PresetLevel" 3 "NormalLevel3" 2 "NormalLevel2" 1 "NormalLevel1" 0 "NoLevelRq" ;
VAL_ 2147537408 NominalLevelRqFrontAxle 15 "DontCare_TakeNoAction" 14 "Reserved" 9 "1101NotDefined" 8 "StopLevelChange" 7 "LowerLevel" 6 "UpperLevel" 5 "CustomerLevel" 4 "PresetLevel" 3 "NormalLevel3" 2 "NormalLevel2" 1 "NormalLevel1" 0 "NoLevelRq" ;
VAL_ 2147537408 KneelingCtrlModeRq 3 "DontCare_TakeNoAction" 2 "Reserved" 1 "ManuallyActuated" 0 "AutomaticallyActuated" ;
VAL_ 2147537408 KneelingRqRightSide 3 "DontCare_TakeNoAction" 2 "Reserved" 1 "KneelingRq" 0 "NoKneelingRq" ;
VAL_ 2147537408 KneelingRqLeftSide 3 "DontCare_TakeNoAction" 2 "Reserved" 1 "KneelingRq" 0 "NoKneelingRq" ;
VAL_ 2147537408 AutomaticTractionHelp 3 "DontCare" 2 "Reserved" 1 "EnableAutomaticTractionHelp" 0 "DisableAutomaticTractionHelp" ;
VAL_ 2147537408 LiftAxle2PosCmd 3 "DontCare_TakeNoAction" 2 "Reserved" 1 "LiftAxlePosUp_TagAxleUnladen" 0 "LiftAxlePosDown_TagAxleLaden" ;
VAL_ 2147537408 LiftAxle1PosCmd 3 "DontCare_TakeNoAction" 2 "Reserved" 1 "LiftAxlePosUp_TagAxleUnladen" 0 "LiftAxlePosDown_TagAxleLaden" ;
VAL_ 2147548762 SspensionCtrlRefusalInformation 7 "1101NotDefined" 15 "NotAvailable" 14 "Error" 6 "GnrlRjctINSpcifiedReasonApplies" 5 "BelowSpeedLimit" 4 "AboveSpeedLimit" 3 "BogieDiffNotLocked" 2 "WouldExceedAxleLoadLimit" 1 "AxleLoadLimitReached" 0 "ActualRqNotRefused" ;
VAL_ 2147548762 SuspensionRemoteCtrl2 3 "NotAvailable" 2 "Error" 1 "Active" 0 "NotActive" ;
VAL_ 2147548762 SuspensionRemoteCtrl1 3 "NotAvailable" 2 "Error" 1 "Active" 0 "NotActive" ;
VAL_ 2147548762 RearAxleInBumperRange 3 "NotAvailable" 2 "Error" 1 "ActualLevelWithinBumperRange" 0 "ActualLevelOutOfBumperRange" ;
VAL_ 2147548762 FrontAxleInBumperRange 3 "NotAvailable" 2 "Error" 1 "ActualLevelWithinBumperRange" 0 "ActualLevelOutOfBumperRange" ;
VAL_ 2147548762 DoorRelease 3 "NotAvailable" 2 "Error" 1 "DoorsMayBeOpened" 0 "DoorsMayNotBeOpened" ;
VAL_ 2147548762 VehicleMotionInhibit 3 "NotAvailable" 2 "Error" 1 "VehicleMotionIsInhibited" 0 "VehicleMayBeMoved" ;
VAL_ 2147548762 SecurityDevice 3 "NotAvailable" 2 "Error" 1 "Active" 0 "NotActive" ;
VAL_ 2147548762 LevelCtrlMode 15 "NotAvailable" 14 "Error" 9 "1101NotDefined" 8 "ExhstngBllwFnctnIBllwsArExhstdT" 7 "TractionHelpLoadReduce" 6 "OptmmTrctn2IPrssAtThDrvnAxlIsCt" 5 "OptmmTrctn1IPrssAtThDrvnAxlIsCt" 4 "PrssRt2IRtBtwnThPrssrsAtThDrvnA" 3 "PrssRt1IRtBtwnThPrssrsAtThDrvnA" 2 "LdFxngIDrvnAxlnIsLddTAVlDfndByT" 1 "TrctnHlpIDrvnAxlIsLddTAMxVlGvnB" 0 "NrmlOprtnISystmPrfrmsAPrCtrlOfT" ;
VAL_ 2147548762 KneelingInformation 15 "NotAvailable" 14 "Error" 5 "1101NotDefined" 4 "KneelingAborted" 3 "LiftingActive" 2 "KneelingLevelReached" 0 "NotActive" ;
VAL_ 2147548762 LiftingCtrlModeRearAxle 3 "NotAvailable" 2 "Error" 1 "LiftingActive" 0 "LiftingNotActive" ;
VAL_ 2147548762 LiftingCtrlModeFrontAxle 3 "NotAvailable" 2 "Error" 1 "LiftingActive" 0 "LiftingNotActive" ;
VAL_ 2147548762 LoweringCtrlModeRearAxle 3 "NotAvailable" 2 "Error" 1 "LoweringActive" 0 "LoweringNotActive" ;
VAL_ 2147548762 LoweringCtrlModeFrontAxle 3 "NotAvailable" 2 "Error" 1 "LoweringActive" 0 "LoweringNotActive" ;
VAL_ 2147548762 AboveNominalLevelRearAxle 3 "NotAvailable" 2 "Error" 1 "Above" 0 "NotAbove" ;
VAL_ 2147548762 AboveNominalLevelFrontAxle 3 "NotAvailable" 2 "Error" 1 "Above" 0 "NotAbove" ;
VAL_ 2147548762 BelowNominalLevelRearAxle 3 "NotAvailable" 2 "Error" 1 "Below" 0 "NotBelow" ;
VAL_ 2147548762 BelowNominalLevelFrontAxle 3 "NotAvailable" 2 "Error" 1 "Below" 0 "NotBelow" ;
VAL_ 2147548762 NominalLevelRearAxle 15 "NotAvailable" 14 "Error" 8 "1101NotDefined" 7 "LowerLevel" 6 "UpperLevel" 5 "CustomerLevel" 4 "PresetLevel" 3 "NormalLevel3" 2 "NormalLevel2" 1 "NormalLevel1" 0 "LevelNotSpecified" ;
VAL_ 2147548762 NominalLevelFrontAxle 15 "NotAvailable" 14 "Error" 8 "1101NotDefined" 7 "LowerLevel" 6 "UpperLevel" 5 "CustomerLevel" 4 "PresetLevel" 3 "NormalLevel3" 2 "NormalLevel2" 1 "NormalLevel1" 0 "LevelNotSpecified" ;
VAL_ 2147548762 LiftAxle2Pos 2 "Error" 1 "LiftAxlePosUp_TagAxleUnladen" 0 "LiftAxlePosDown_TagAxleLaden" ;
VAL_ 2147548762 LiftAxle1Pos 2 "Error" 1 "LiftAxlePosUp_TagAxleUnladen" 0 "LiftAxlePosDown_TagAxleLaden" ;
VAL_ 2147548879 FailureModeIdentifier5 31 "Not available" 19 "Received network data in error" 18 "Below normal (moderatels severe)" 17 "Below normal (least severe)" 16 "Above normal (moderately severe)" 15 "Above normal (least severe)" 14 "Special intstructions" 13 "Out of calibration" 12 "Bad intelligent device" 11 "Root cause not known" 10 "Abnormal rate of change" 9 "Abnormal update rate" 8 "Abnormal frequency" 7 "Mechanical system not responding" 6 "Current above normal" 5 "Current below normal" 4 "Voltage below normal" 3 "Voltage above normal" 2 "Data erratic" 1 "Below normal (most severe)" 0 "Above normal (most severe)" ;
VAL_ 2147548879 FailureModeIdentifier4 31 "Not available" 19 "Received network data in error" 18 "Below normal (moderatels severe)" 17 "Below normal (least severe)" 16 "Above normal (moderately severe)" 15 "Above normal (least severe)" 14 "Special intstructions" 13 "Out of calibration" 12 "Bad intelligent device" 11 "Root cause not known" 10 "Abnormal rate of change" 9 "Abnormal update rate" 8 "Abnormal frequency" 7 "Mechanical system not responding" 6 "Current above normal" 5 "Current below normal" 4 "Voltage below normal" 3 "Voltage above normal" 2 "Data erratic" 1 "Below normal (most severe)" 0 "Above normal (most severe)" ;
VAL_ 2147548879 FailureModeIdentifier3 31 "Not available" 19 "Received network data in error" 18 "Below normal (moderatels severe)" 17 "Below normal (least severe)" 16 "Above normal (moderately severe)" 15 "Above normal (least severe)" 14 "Special intstructions" 13 "Out of calibration" 12 "Bad intelligent device" 11 "Root cause not known" 10 "Abnormal rate of change" 9 "Abnormal update rate" 8 "Abnormal frequency" 7 "Mechanical system not responding" 6 "Current above normal" 5 "Current below normal" 4 "Voltage below normal" 3 "Voltage above normal" 2 "Data erratic" 1 "Below normal (most severe)" 0 "Above normal (most severe)" ;
VAL_ 2147548879 FailureModeIdentifier2 31 "Not available" 19 "Received network data in error" 18 "Below normal (moderatels severe)" 17 "Below normal (least severe)" 16 "Above normal (moderately severe)" 15 "Above normal (least severe)" 14 "Special intstructions" 13 "Out of calibration" 12 "Bad intelligent device" 11 "Root cause not known" 10 "Abnormal rate of change" 9 "Abnormal update rate" 8 "Abnormal frequency" 7 "Mechanical system not responding" 6 "Current above normal" 5 "Current below normal" 4 "Voltage below normal" 3 "Voltage above normal" 2 "Data erratic" 1 "Below normal (most severe)" 0 "Above normal (most severe)" ;
VAL_ 2147548879 FailureModeIdentifier1 31 "Not available" 19 "Received network data in error" 18 "Below normal (moderatels severe)" 17 "Below normal (least severe)" 16 "Above normal (moderately severe)" 15 "Above normal (least severe)" 14 "Special intstructions" 13 "Out of calibration" 12 "Bad intelligent device" 11 "Root cause not known" 10 "Abnormal rate of change" 9 "Abnormal update rate" 8 "Abnormal frequency" 7 "Mechanical system not responding" 6 "Current above normal" 5 "Current below normal" 4 "Voltage below normal" 3 "Voltage above normal" 2 "Data erratic" 1 "Below normal (most severe)" 0 "Above normal (most severe)" ;
VAL_ 2147548879 MalfunctionIndicatorLampStatus 3 "Not available" 2 "Reserved" 1 "Lamp on" 0 "Lamp off" ;
VAL_ 2147548879 RedStopLampState 3 "Not available" 2 "Reserved" 1 "Lamp on" 0 "Lamp off" ;
VAL_ 2147548879 AmberWarningLampStatus 3 "Not available" 2 "Reserved" 1 "Lamp on" 0 "Lamp off" ;
VAL_ 2147548879 ProtectLampStatus 3 "Not available" 2 "Reserved" 1 "Lamp on" 0 "Lamp off" ;
VAL_ 2147548878 MisfireMonitoringSupport 3 "Not available" 2 "Reserved" 1 "test supported" 0 "test not supported" ;
VAL_ 2147548878 OBDCompliance 17 "EMD" 16 "Euro EEC C" 15 "Euro V B2" 14 "Euro IV B1" 13 "JOBD, EOBD and OBD II" 12 "JOBD and EOBD" 11 "JOBD and OBD II" 10 "JOBD" 9 "EOBD, OBD and OBD II" 8 "EOBD and OBD" 7 "EOBD and OBD II" 6 "EOBD" 5 "Not intended to meet OBD II requ" 4 "OBD I" 3 "OBD and OBD II" 2 "OBD (Federal, EPA)" 1 "OBD II (California, ARB)" 0 "Reserver for assignment by SAE" ;
VAL_ 2147548878 SecondAirSystemMonStatus 1 "test not complete" 0 "test complete" ;
VAL_ 2147548878 EvaporativeSystemMonStatus 1 "test not complete" 0 "test complete" ;
VAL_ 2147548878 ACSystemRefrigerantMonStatus 1 "test not complete" 0 "test complete" ;
VAL_ 2147548878 OxygenSensorHeaterMonStatus 1 "test not complete" 0 "test complete" ;
VAL_ 2147548878 OxygenSensorMonStatus 1 "test not complete" 0 "test complete" ;
VAL_ 2147548878 EGRSystemMonitoringStatus 1 "test not complete" 0 "test complete" ;
VAL_ 2147548878 CatalystMonStatus 0 "test complete" 1 "test not complete" ;
VAL_ 2147548878 ColdStartAidSystemMonStatus 1 "test not complete" 0 "test complete" ;
VAL_ 2147548878 HeatedCatalystMonStatus 1 "test not complete" 0 "test complete" ;
VAL_ 2147548878 CatalystMonSupp 1 "test supported" 0 "test not supported" ;
VAL_ 2147548878 ColdStartAidSystemMonSupp 1 "test supported" 0 "test not supported" ;
VAL_ 2147548878 EvaporativeSystemMonSupp 1 "test supported" 0 "test not supported" ;
VAL_ 2147548878 SecondAirSystemMonSupp 1 "test supported" 0 "test not supported" ;
VAL_ 2147548878 ACSystemRefrigerantMonSupp 1 "test supported" 0 "test not supported" ;
VAL_ 2147548878 OxygenSensorMonSupp 1 "test supported" 0 "test not supported" ;
VAL_ 2147548878 OxygenSensorHeaterMonSupp 1 "test supported" 0 "test not supported" ;
VAL_ 2147548878 EGRSystemMonitoringSupp 1 "test supported" 0 "test not supported" ;
VAL_ 2147548878 MisfireMonitoringStatus 1 "test not complete" 0 "test complete" ;
VAL_ 2147548878 ComprehensiveCompMonStatus 1 "test not complete" 0 "test complete" ;
VAL_ 2147548878 FuelSystemMonitoringStatus 1 "test not complete" 0 "test complete" ;
VAL_ 2147548878 ComprehensiveComponentMonSupp 3 "Not available" 2 "Reserved" 1 "test supported" 0 "test not supported" ;
VAL_ 2147548878 FuelSystemMonitoringSupport 1 "test supported" 0 "test not supported" ;
VAL_ 2147548877 FailureModeIdentifier1 31 "Not available" 19 "Received network data in error" 18 "Below normal (moderatels severe)" 17 "Below normal (least severe)" 16 "Above normal (moderately severe)" 15 "Above normal (least severe)" 14 "Special intstructions" 13 "Out of calibration" 12 "Bad intelligent device" 11 "Root cause not known" 10 "Abnormal rate of change" 9 "Abnormal update rate" 8 "Abnormal frequency" 7 "Mechanical system not responding" 6 "Current above normal" 5 "Current below normal" 4 "Voltage below normal" 3 "Voltage above normal" 2 "Data erratic" 1 "Below normal (most severe)" 0 "Above normal (most severe)" ;
VAL_ 2147548877 EngineTorqueMode 15 "Not available" 11 "Remote accelerator" 10 "Braking system" 9 "High speed governor" 8 "Torque limiting" 7 "ABS control" 6 "Transmission control" 5 "ASR control" 4 "Road speed governor" 3 "PTO governor" 2 "Cruise control" 1 "Accelerator pedal/operator selec" 0 "Low idle governor/no request (de" ;
VAL_ 2147548599 FailureModeIdentifier1 31 "Not available" 19 "Received network data in error" 18 "Below normal (moderatels severe)" 17 "Below normal (least severe)" 16 "Above normal (moderately severe)" 15 "Above normal (least severe)" 14 "Special intstructions" 13 "Out of calibration" 12 "Bad intelligent device" 11 "Root cause not known" 10 "Abnormal rate of change" 9 "Abnormal update rate" 8 "Abnormal frequency" 7 "Mechanical system not responding" 6 "Current above normal" 5 "Current below normal" 4 "Voltage below normal" 3 "Voltage above normal" 2 "Data erratic" 1 "Below normal (most severe)" 0 "Above normal (most severe)" ;
VAL_ 2147548597 FailureModeIdentifier5 31 "Not available" 19 "Received network data in error" 18 "Below normal (moderatels severe)" 17 "Below normal (least severe)" 16 "Above normal (moderately severe)" 15 "Above normal (least severe)" 14 "Special intstructions" 13 "Out of calibration" 12 "Bad intelligent device" 11 "Root cause not known" 10 "Abnormal rate of change" 9 "Abnormal update rate" 8 "Abnormal frequency" 7 "Mechanical system not responding" 6 "Current above normal" 5 "Current below normal" 4 "Voltage below normal" 3 "Voltage above normal" 2 "Data erratic" 1 "Below normal (most severe)" 0 "Above normal (most severe)" ;
VAL_ 2147548597 FailureModeIdentifier4 31 "Not available" 19 "Received network data in error" 18 "Below normal (moderatels severe)" 17 "Below normal (least severe)" 16 "Above normal (moderately severe)" 15 "Above normal (least severe)" 14 "Special intstructions" 13 "Out of calibration" 12 "Bad intelligent device" 11 "Root cause not known" 10 "Abnormal rate of change" 9 "Abnormal update rate" 8 "Abnormal frequency" 7 "Mechanical system not responding" 6 "Current above normal" 5 "Current below normal" 4 "Voltage below normal" 3 "Voltage above normal" 2 "Data erratic" 1 "Below normal (most severe)" 0 "Above normal (most severe)" ;
VAL_ 2147548597 FailureModeIdentifier1 31 "Not available" 19 "Received network data in error" 18 "Below normal (moderatels severe)" 17 "Below normal (least severe)" 16 "Above normal (moderately severe)" 15 "Above normal (least severe)" 14 "Special intstructions" 13 "Out of calibration" 12 "Bad intelligent device" 11 "Root cause not known" 10 "Abnormal rate of change" 9 "Abnormal update rate" 8 "Abnormal frequency" 7 "Mechanical system not responding" 6 "Current above normal" 5 "Current below normal" 4 "Voltage below normal" 3 "Voltage above normal" 2 "Data erratic" 1 "Below normal (most severe)" 0 "Above normal (most severe)" ;
VAL_ 2147548597 MalfunctionIndicatorLampStatus 3 "Not available" 2 "Reserved" 1 "Lamp on" 0 "Lamp off" ;
VAL_ 2147548597 RedStopLampState 3 "Not available" 2 "Reserved" 1 "Lamp on" 0 "Lamp off" ;
VAL_ 2147548597 AmberWarningLampStatus 3 "Not available" 2 "Reserved" 1 "Lamp on" 0 "Lamp off" ;
VAL_ 2147548597 ProtectLampStatus 3 "Not available" 2 "Reserved" 1 "Lamp on" 0 "Lamp off" ;
VAL_ 2147548597 FailureModeIdentifier3 31 "Not available" 19 "Received network data in error" 18 "Below normal (moderatels severe)" 17 "Below normal (least severe)" 16 "Above normal (moderately severe)" 15 "Above normal (least severe)" 14 "Special intstructions" 13 "Out of calibration" 12 "Bad intelligent device" 11 "Root cause not known" 10 "Abnormal rate of change" 9 "Abnormal update rate" 8 "Abnormal frequency" 7 "Mechanical system not responding" 6 "Current above normal" 5 "Current below normal" 4 "Voltage below normal" 3 "Voltage above normal" 2 "Data erratic" 1 "Below normal (most severe)" 0 "Above normal (most severe)" ;
VAL_ 2147548597 FailureModeIdentifier2 31 "Not available" 19 "Received network data in error" 18 "Below normal (moderatels severe)" 17 "Below normal (least severe)" 16 "Above normal (moderately severe)" 15 "Above normal (least severe)" 14 "Special intstructions" 13 "Out of calibration" 12 "Bad intelligent device" 11 "Root cause not known" 10 "Abnormal rate of change" 9 "Abnormal update rate" 8 "Abnormal frequency" 7 "Mechanical system not responding" 6 "Current above normal" 5 "Current below normal" 4 "Voltage below normal" 3 "Voltage above normal" 2 "Data erratic" 1 "Below normal (most severe)" 0 "Above normal (most severe)" ;
VAL_ 2147533568 DTCClearControlByte 19 "NegativeACK" 18 "PositiveACK" 17 "RequestToClearSpecificActiveDTC" 3 "NegativeACK" 2 "PositiveACK" 1 "RequestToClearSpecificPreviously" ;
VAL_ 2147533568 CtrlByteSpecificIndicator 4 "DTCnoLongerActive" 3 "DTCnoLongerPreviouslyActive" 2 "DTCUnknown" 1 "AccessDenied" 0 "GeneralNegativeACK" ;
VAL_ 2147548875 FailureModeIdentifier5 31 "Not available" 19 "Received network data in error" 18 "Below normal (moderatels severe)" 17 "Below normal (least severe)" 16 "Above normal (moderately severe)" 15 "Above normal (least severe)" 14 "Special intstructions" 13 "Out of calibration" 12 "Bad intelligent device" 11 "Root cause not known" 10 "Abnormal rate of change" 9 "Abnormal update rate" 8 "Abnormal frequency" 7 "Mechanical system not responding" 6 "Current above normal" 5 "Current below normal" 4 "Voltage below normal" 3 "Voltage above normal" 2 "Data erratic" 1 "Below normal (most severe)" 0 "Above normal (most severe)" ;
VAL_ 2147548875 FailureModeIdentifier4 31 "Not available" 19 "Received network data in error" 18 "Below normal (moderatels severe)" 17 "Below normal (least severe)" 16 "Above normal (moderately severe)" 15 "Above normal (least severe)" 14 "Special intstructions" 13 "Out of calibration" 12 "Bad intelligent device" 11 "Root cause not known" 10 "Abnormal rate of change" 9 "Abnormal update rate" 8 "Abnormal frequency" 7 "Mechanical system not responding" 6 "Current above normal" 5 "Current below normal" 4 "Voltage below normal" 3 "Voltage above normal" 2 "Data erratic" 1 "Below normal (most severe)" 0 "Above normal (most severe)" ;
VAL_ 2147548875 FailureModeIdentifier1 31 "Not available" 19 "Received network data in error" 18 "Below normal (moderatels severe)" 17 "Below normal (least severe)" 16 "Above normal (moderately severe)" 15 "Above normal (least severe)" 14 "Special intstructions" 13 "Out of calibration" 12 "Bad intelligent device" 11 "Root cause not known" 10 "Abnormal rate of change" 9 "Abnormal update rate" 8 "Abnormal frequency" 7 "Mechanical system not responding" 6 "Current above normal" 5 "Current below normal" 4 "Voltage below normal" 3 "Voltage above normal" 2 "Data erratic" 1 "Below normal (most severe)" 0 "Above normal (most severe)" ;
VAL_ 2147548875 MalfunctionIndicatorLampStatus 3 "Not available" 2 "Reserved" 1 "Lamp on" 0 "Lamp off" ;
VAL_ 2147548875 RedStopLampState 3 "Not available" 2 "Reserved" 1 "Lamp on" 0 "Lamp off" ;
VAL_ 2147548875 AmberWarningLampStatus 3 "Not available" 2 "Reserved" 1 "Lamp on" 0 "Lamp off" ;
VAL_ 2147548875 ProtectLampStatus 3 "Not available" 2 "Reserved" 1 "Lamp on" 0 "Lamp off" ;
VAL_ 2147548875 FailureModeIdentifier3 31 "Not available" 19 "Received network data in error" 18 "Below normal (moderatels severe)" 17 "Below normal (least severe)" 16 "Above normal (moderately severe)" 15 "Above normal (least severe)" 14 "Special intstructions" 13 "Out of calibration" 12 "Bad intelligent device" 11 "Root cause not known" 10 "Abnormal rate of change" 9 "Abnormal update rate" 8 "Abnormal frequency" 7 "Mechanical system not responding" 6 "Current above normal" 5 "Current below normal" 4 "Voltage below normal" 3 "Voltage above normal" 2 "Data erratic" 1 "Below normal (most severe)" 0 "Above normal (most severe)" ;
VAL_ 2147548875 FailureModeIdentifier2 31 "Not available" 19 "Received network data in error" 18 "Below normal (moderatels severe)" 17 "Below normal (least severe)" 16 "Above normal (moderately severe)" 15 "Above normal (least severe)" 14 "Special intstructions" 13 "Out of calibration" 12 "Bad intelligent device" 11 "Root cause not known" 10 "Abnormal rate of change" 9 "Abnormal update rate" 8 "Abnormal frequency" 7 "Mechanical system not responding" 6 "Current above normal" 5 "Current below normal" 4 "Voltage below normal" 3 "Voltage above normal" 2 "Data erratic" 1 "Below normal (most severe)" 0 "Above normal (most severe)" ;
VAL_ 2147540736 HoldSignal 15 "Not available" 1 "Devices whose broadcast state ha" 0 "All devices" ;
VAL_ 2147540736 J1939Network3 3 "Don't care" 2 "Reserved" 1 "Start broadcast" 0 "Stop broadcast" ;
VAL_ 2147540736 J1939Network2 3 "Don't care" 2 "Reserved" 1 "Start broadcast" 0 "Stop broadcast" ;
VAL_ 2147540736 ISO9141 3 "Don't care" 2 "Reserved" 1 "Start broadcast" 0 "Stop broadcast" ;
VAL_ 2147540736 SAE_J1850 3 "Don't care" 2 "Reserved" 1 "Start broadcast" 0 "Stop broadcast" ;
VAL_ 2147540736 ManufacturerSpecificPort 3 "Don't care" 2 "Reserved" 1 "Start broadcast" 0 "Stop broadcast" ;
VAL_ 2147540736 CurrentDataLink 3 "Don't care" 2 "Reserved" 1 "Start broadcast" 0 "Stop broadcast" ;
VAL_ 2147540736 SAE_J1587 3 "Don't care" 2 "Reserved" 1 "Start broadcast" 0 "Stop broadcast" ;
VAL_ 2147540736 SAE_J1922 3 "Don't care" 2 "Reserved" 1 "Start broadcast" 0 "Stop broadcast" ;
VAL_ 2147540736 J1939Network1 3 "Don't care" 2 "Reserved" 1 "Start broadcast" 0 "Stop broadcast" ;
VAL_ 2147548884 FailureModeIdentifier5 31 "Not available" 19 "Received network data in error" 18 "Below normal (moderatels severe)" 17 "Below normal (least severe)" 16 "Above normal (moderately severe)" 15 "Above normal (least severe)" 14 "Special intstructions" 13 "Out of calibration" 12 "Bad intelligent device" 11 "Root cause not known" 10 "Abnormal rate of change" 9 "Abnormal update rate" 8 "Abnormal frequency" 7 "Mechanical system not responding" 6 "Current above normal" 5 "Current below normal" 4 "Voltage below normal" 3 "Voltage above normal" 2 "Data erratic" 1 "Below normal (most severe)" 0 "Above normal (most severe)" ;
VAL_ 2147548884 FailureModeIdentifier4 31 "Not available" 19 "Received network data in error" 18 "Below normal (moderatels severe)" 17 "Below normal (least severe)" 16 "Above normal (moderately severe)" 15 "Above normal (least severe)" 14 "Special intstructions" 13 "Out of calibration" 12 "Bad intelligent device" 11 "Root cause not known" 10 "Abnormal rate of change" 9 "Abnormal update rate" 8 "Abnormal frequency" 7 "Mechanical system not responding" 6 "Current above normal" 5 "Current below normal" 4 "Voltage below normal" 3 "Voltage above normal" 2 "Data erratic" 1 "Below normal (most severe)" 0 "Above normal (most severe)" ;
VAL_ 2147548884 FailureModeIdentifier3 31 "Not available" 19 "Received network data in error" 18 "Below normal (moderatels severe)" 17 "Below normal (least severe)" 16 "Above normal (moderately severe)" 15 "Above normal (least severe)" 14 "Special intstructions" 13 "Out of calibration" 12 "Bad intelligent device" 11 "Root cause not known" 10 "Abnormal rate of change" 9 "Abnormal update rate" 8 "Abnormal frequency" 7 "Mechanical system not responding" 6 "Current above normal" 5 "Current below normal" 4 "Voltage below normal" 3 "Voltage above normal" 2 "Data erratic" 1 "Below normal (most severe)" 0 "Above normal (most severe)" ;
VAL_ 2147548884 FailureModeIdentifier1 31 "Not available" 19 "Received network data in error" 18 "Below normal (moderatels severe)" 17 "Below normal (least severe)" 16 "Above normal (moderately severe)" 15 "Above normal (least severe)" 14 "Special intstructions" 13 "Out of calibration" 12 "Bad intelligent device" 11 "Root cause not known" 10 "Abnormal rate of change" 9 "Abnormal update rate" 8 "Abnormal frequency" 7 "Mechanical system not responding" 6 "Current above normal" 5 "Current below normal" 4 "Voltage below normal" 3 "Voltage above normal" 2 "Data erratic" 1 "Below normal (most severe)" 0 "Above normal (most severe)" ;
VAL_ 2147548884 MalfunctionIndicatorLampStatus 3 "Not available" 2 "Reserved" 1 "Lamp on" 0 "Lamp off" ;
VAL_ 2147548884 RedStopLampState 3 "Not available" 2 "Reserved" 1 "Lamp on" 0 "Lamp off" ;
VAL_ 2147548884 AmberWarningLampStatus 3 "Not available" 2 "Reserved" 1 "Lamp on" 0 "Lamp off" ;
VAL_ 2147548884 ProtectLampStatus 3 "Not available" 2 "Reserved" 1 "Lamp on" 0 "Lamp off" ;
VAL_ 2147548884 FailureModeIdentifier2 31 "Not available" 19 "Received network data in error" 18 "Below normal (moderatels severe)" 17 "Below normal (least severe)" 16 "Above normal (moderately severe)" 15 "Above normal (least severe)" 14 "Special intstructions" 13 "Out of calibration" 12 "Bad intelligent device" 11 "Root cause not known" 10 "Abnormal rate of change" 9 "Abnormal update rate" 8 "Abnormal frequency" 7 "Mechanical system not responding" 6 "Current above normal" 5 "Current below normal" 4 "Voltage below normal" 3 "Voltage above normal" 2 "Data erratic" 1 "Below normal (most severe)" 0 "Above normal (most severe)" ;
VAL_ 2147548882 Test8 1 "test supported" 0 "test not supported" ;
VAL_ 2147548882 Test7 1 "test supported" 0 "test not supported" ;
VAL_ 2147548882 Test6 1 "test supported" 0 "test not supported" ;
VAL_ 2147548882 Test5 1 "test supported" 0 "test not supported" ;
VAL_ 2147548882 Test4 1 "test supported" 0 "test not supported" ;
VAL_ 2147548882 Test3 1 "test supported" 0 "test not supported" ;
VAL_ 2147548882 Test2 1 "test supported" 0 "test not supported" ;
VAL_ 2147548882 Test1 1 "test supported" 0 "test not supported" ;
VAL_ 2147548874 FailureModeIdentifier5 31 "Not available" 19 "Received network data in error" 18 "Below normal (moderatels severe)" 17 "Below normal (least severe)" 16 "Above normal (moderately severe)" 15 "Above normal (least severe)" 14 "Special intstructions" 13 "Out of calibration" 12 "Bad intelligent device" 11 "Root cause not known" 10 "Abnormal rate of change" 9 "Abnormal update rate" 8 "Abnormal frequency" 7 "Mechanical system not responding" 6 "Current above normal" 5 "Current below normal" 4 "Voltage below normal" 3 "Voltage above normal" 2 "Data erratic" 1 "Below normal (most severe)" 0 "Above normal (most severe)" ;
VAL_ 2147548874 FailureModeIdentifier4 31 "Not available" 19 "Received network data in error" 18 "Below normal (moderatels severe)" 17 "Below normal (least severe)" 16 "Above normal (moderately severe)" 15 "Above normal (least severe)" 14 "Special intstructions" 13 "Out of calibration" 12 "Bad intelligent device" 11 "Root cause not known" 10 "Abnormal rate of change" 9 "Abnormal update rate" 8 "Abnormal frequency" 7 "Mechanical system not responding" 6 "Current above normal" 5 "Current below normal" 4 "Voltage below normal" 3 "Voltage above normal" 2 "Data erratic" 1 "Below normal (most severe)" 0 "Above normal (most severe)" ;
VAL_ 2147548874 FailureModeIdentifier3 31 "Not available" 19 "Received network data in error" 18 "Below normal (moderatels severe)" 17 "Below normal (least severe)" 16 "Above normal (moderately severe)" 15 "Above normal (least severe)" 14 "Special intstructions" 13 "Out of calibration" 12 "Bad intelligent device" 11 "Root cause not known" 10 "Abnormal rate of change" 9 "Abnormal update rate" 8 "Abnormal frequency" 7 "Mechanical system not responding" 6 "Current above normal" 5 "Current below normal" 4 "Voltage below normal" 3 "Voltage above normal" 2 "Data erratic" 1 "Below normal (most severe)" 0 "Above normal (most severe)" ;
VAL_ 2147548874 FlashEngineRedStopLamp 3 "Unavailable / Do Not Flash" 2 "Reserved" 1 "Fast Flash" 0 "Slow Flash" ;
VAL_ 2147548874 FlashEngineProtectLamp 3 "Unavailable / Do Not Flash" 2 "Reserved" 1 "Fast Flash" 0 "Slow Flash" ;
VAL_ 2147548874 FlashEngineMalfuncIndicatorLamp 3 "Unavailable / Do Not Flash" 2 "Reserved" 1 "Fast Flash" 0 "Slow Flash" ;
VAL_ 2147548874 FlashEngineAmberWarningLamp 3 "Unavailable / Do Not Flash" 2 "Reserved" 1 "Fast Flash" 0 "Slow Flash" ;
VAL_ 2147548874 MalfunctionIndicatorLampStatus 3 "Not available" 2 "Reserved" 1 "Lamp on" 0 "Lamp off" ;
VAL_ 2147548874 AmberWarningLampStatus 3 "Not available" 2 "Reserved" 1 "Lamp on" 0 "Lamp off" ;
VAL_ 2147548874 FailureModeIdentifier1 31 "Not available" 19 "Received network data in error" 18 "Below normal (moderatels severe)" 17 "Below normal (least severe)" 16 "Above normal (moderately severe)" 15 "Above normal (least severe)" 14 "Special intstructions" 13 "Out of calibration" 12 "Bad intelligent device" 11 "Root cause not known" 10 "Abnormal rate of change" 9 "Abnormal update rate" 8 "Abnormal frequency" 7 "Mechanical system not responding" 6 "Current above normal" 5 "Current below normal" 4 "Voltage below normal" 3 "Voltage above normal" 2 "Data erratic" 1 "Below normal (most severe)" 0 "Above normal (most severe)" ;
VAL_ 2147548874 RedStopLampState 3 "Not available" 2 "Reserved" 1 "Lamp on" 0 "Lamp off" ;
VAL_ 2147548874 ProtectLampStatus 3 "Not available" 2 "Reserved" 1 "Lamp on" 0 "Lamp off" ;
VAL_ 2147548874 FailureModeIdentifier2 31 "Not available" 19 "Received network data in error" 18 "Below normal (moderatels severe)" 17 "Below normal (least severe)" 16 "Above normal (moderately severe)" 15 "Above normal (least severe)" 14 "Special intstructions" 13 "Out of calibration" 12 "Bad intelligent device" 11 "Root cause not known" 10 "Abnormal rate of change" 9 "Abnormal update rate" 8 "Abnormal frequency" 7 "Mechanical system not responding" 6 "Current above normal" 5 "Current below normal" 4 "Voltage below normal" 3 "Voltage above normal" 2 "Data erratic" 1 "Below normal (most severe)" 0 "Above normal (most severe)" ;
VAL_ 2147544064 PGNumber 255 "NotAvailable" ;
VAL_ 2147544064 ControlByte 24 "EAbort" 23 "EEoMACK" 22 "EDPO" 21 "ECTS" 20 "ERTS" 3 "CannotRespond" 2 "AccessDenied" 1 "NACK" 0 "PACK" 255 "Abort" 32 "BAM" 19 "EoMA" 17 "CTS" 16 "RTS" ;
VAL_ 2147535104 UseTransferMode 3 "NA" 2 "Undefined" 1 "Yes" 0 "No" ;
VAL_ 2147548753 RqedACCDistanceMode 7 "notAvailable" 6 "errorCondition" 5 "notDefined" 4 "RqedACCDistanceMode5" 3 "RqedACCDistanceMode4" 2 "RqedACCDistanceMode3" 1 "RqedACCDistanceMode2" 0 "RqedACCDistanceMode1" ;
VAL_ 2147548783 ACCDistanceAlertSignal 3 "TakeNoAction" 2 "Reserved" 1 "ACCDASActive" 0 "ACCDASNotActive" ;
VAL_ 2147548783 ACCSystemShutoffWarning 3 "TakeNoAction" 2 "Reserved" 1 "ACCSSOWActive" 0 "ACCSSOWNotActive" ;
VAL_ 2147548783 ACCTargetDetected 3 "TakeNoAction" 2 "Reserved" 1 "TargetDetected" 0 "NoTargetsDetected" ;
VAL_ 2147548783 AdptveCruiseCtrlSetDistanceMode 7 "NotAvailable_NotValid" 6 "ErrorCondition" 5 "ConventionalCruiseCtrlMode" 4 "ACCDistanceMode5" 3 "ACCDistanceMode4" 2 "ACCDistanceMode3" 1 "ACCDistanceMode2" 0 "ACCDistanceMode1" ;
VAL_ 2147548783 AdaptiveCruiseCtrlMode 7 "NotAvailable_NotValid" 6 "DsbldErrrCndtnUsdTIndctThtACCIs" 5 "FinishMode" 4 "HldMdUsdTIndctThtACCHsLstThPrvs" 3 "OvertakeMode" 2 "DstncCtrlActvUsdTIndctThtACCIsO" 1 "SpeedCtrlActive" 0 "OffUsdTIndctACCIsEnbldInClbCnfg" ;
VAL_ 2147543040 CtrlByte 24 "EAbort" 23 "EEoMACK" 22 "EDPO" 21 "ECTS" 20 "ERTS" 3 "CannotRespond" 2 "AccessDenied" 1 "NACK" 0 "PACK" 255 "Abort" 32 "BAM" 19 "EoMA" 17 "CTS" 16 "RTS" ;
